VERSION ""

NS_ :

BS_:

BU_: PFAF_HS LVMPC_HS DCDC_HS AMP_HS VICM2_HS FICM_HS ARS_HS MCP_B_HS MCP_A_HS ICCM_OBD_HS SAS_HS ACCM_HS VLBS_HS EBCM_OBD_HS EDI_HS HPCC_HS VITM_OBD_HS PTAM_HS OBCM_HS VICM_HS HCP_HS FDCM_HS APPS_HS ICCM_HS EOCM_F_HS GPCM_HS FSCM_ITBC_HS SCM_HS ITBC_HS VCM_HS HMIM_HS FCP_HS VES_HS Dummy_HS MCP_C_HS RWS_HS ONSTAR_HS EPS_HS TestTool_HS MCP_HS BCP_HS ALC_HS AHL_AFL_HS SADS_HS EPB_HS FSCM_HS AFS_HS FCM_HS TCCM_HS RDCM_HS PTO_HS PCM_HS EBCM_HS ACC_HS BCM_HS TCM_HS ECM_HS

BO_ 452 PPEI_Torque_Request_Status: 8 ECM_HS
 SG_ FSpRgACCSwADdPVal : 50|2@0+ (1,0) [0|3] ""  EBCM_OBD_HS,EBCM_HS
 SG_ FSpRgACCSwADdARC : 6|2@0+ (1,0) [0|3] ""  EBCM_OBD_HS,EBCM_HS
 SG_ FSpRgACCSwADd : 7|1@0+ (1,0) [0|1] ""  EBCM_OBD_HS,EBCM_HS,ACC_HS
 SG_ AutBrkAccActPsStRC : 34|2@0+ (1,0) [0|3] ""  EOCM_F_HS,ACC_HS,EBCM_OBD_HS,EBCM_HS
 SG_ AutBrkAccActPsStPVal : 48|9@0+ (1,0) [0|511] ""  EOCM_F_HS,ACC_HS,EBCM_OBD_HS,EBCM_HS
 SG_ ABAAPS_AccPos : 47|8@0+ (0.392157,0) [0|100.000035] "%"  EBCM_OBD_HS,EBCM_HS,ACC_HS,EOCM_F_HS
 SG_ ABAAPS_AccPosV : 32|1@0+ (1,0) [0|1] ""  EBCM_OBD_HS,EBCM_HS,ACC_HS,EOCM_F_HS
 SG_ ACCATCS_LmtgStat : 12|2@0+ (1,0) [0|3] ""  EOCM_F_HS,ACC_HS
 SG_ ACCATCS_RqStat : 15|3@0+ (1,0) [0|7] ""  EOCM_F_HS,ACC_HS
 SG_ RdLdNomAxlTrq : 10|19@0+ (0.125,-22534) [-22534|43001.875] "Nm"  EOCM_F_HS,ACC_HS
 SG_ AccPdlOvrrdAtvProtVal : 1|2@0+ (1,0) [0|3] ""  EOCM_F_HS,EBCM_OBD_HS,EBCM_HS,ACC_HS,PTO_HS
 SG_ AccPdlOvrrdAtvARC : 3|2@0+ (1,0) [0|3] ""  EOCM_F_HS,EBCM_OBD_HS,EBCM_HS,ACC_HS,PTO_HS
 SG_ AccPdlOvrrdAtv : 4|1@0+ (1,0) [0|1] ""  BCM_HS,EOCM_F_HS,EBCM_OBD_HS,EBCM_HS,ACC_HS,PTO_HS
 SG_ CPSATCS_ReqStatus : 37|3@0+ (1,0) [0|7] ""  ACC_HS,EOCM_F_HS
 SG_ CPSATCS_LmtngStatus : 39|2@0+ (1,0) [0|3] ""  ACC_HS,EOCM_F_HS
 SG_ RVBATCS_ReqStat : 53|3@0+ (1,0) [0|7] ""  EOCM_F_HS
 SG_ RVBATCS_LmtngStat : 55|2@0+ (1,0) [0|3] ""  EOCM_F_HS

BO_ 1905 DTC_Triggered_771: 7 FDCM_HS
 SG_ DTCI_DTCFaultType_771 : 55|8@0+ (1,0) [0|255] ""  HMIM_HS,FCP_HS,ONSTAR_HS
 SG_ DTCI_CodeSupported_771 : 40|1@0+ (1,0) [0|1] ""  HMIM_HS,FCP_HS,ONSTAR_HS
 SG_ DTCI_CurrentStatus_771 : 41|1@0+ (1,0) [0|1] ""  HMIM_HS,FCP_HS,ONSTAR_HS
 SG_ DTCI_TstNPsdCdClrdSt_771 : 42|1@0+ (1,0) [0|1] ""  HMIM_HS,FCP_HS,ONSTAR_HS
 SG_ DTCI_TstFldCdClrdStat_771 : 43|1@0+ (1,0) [0|1] ""  HMIM_HS,FCP_HS,ONSTAR_HS
 SG_ DTCI_HistStat_771 : 44|1@0+ (1,0) [0|1] ""  HMIM_HS,FCP_HS,ONSTAR_HS
 SG_ DTCI_TstNPsdPwrUpSt_771 : 45|1@0+ (1,0) [0|1] ""  HMIM_HS,FCP_HS,ONSTAR_HS
 SG_ DTCI_TstFldPwrUpSt_771 : 46|1@0+ (1,0) [0|1] ""  HMIM_HS,FCP_HS,ONSTAR_HS
 SG_ DTCI_WrnIndRqdSt_771 : 47|1@0+ (1,0) [0|1] ""  HMIM_HS,FCP_HS,ONSTAR_HS
 SG_ DTCI_DTCFailType_771 : 39|8@0+ (1,0) [0|255] ""  HMIM_HS,FCP_HS,ONSTAR_HS
 SG_ DTCI_DTCNumber_771 : 23|16@0+ (1,0) [0|65535] ""  HMIM_HS,FCP_HS,ONSTAR_HS
 SG_ DTCI_DTCSource_771 : 15|8@0+ (1,0) [0|255] ""  HMIM_HS,FCP_HS,ONSTAR_HS
 SG_ DTCI_DTCTriggered_771 : 0|1@0+ (1,0) [0|1] ""  HMIM_HS,FCP_HS,ONSTAR_HS
 SG_ DTCIUnused7_771 : 1|1@0+ (1,0) [0|1] ""  HMIM_HS,FCP_HS,ONSTAR_HS
 SG_ DTCIUnused6_771 : 2|1@0+ (1,0) [0|1] ""  HMIM_HS,FCP_HS,ONSTAR_HS
 SG_ DTCIUnused5_771 : 3|1@0+ (1,0) [0|1] ""  HMIM_HS,FCP_HS,ONSTAR_HS
 SG_ DTCIUnused4_771 : 4|1@0+ (1,0) [0|1] ""  HMIM_HS,FCP_HS,ONSTAR_HS
 SG_ DTCIUnused3_771 : 5|1@0+ (1,0) [0|1] ""  HMIM_HS,FCP_HS,ONSTAR_HS
 SG_ DTCIUnused2_771 : 6|1@0+ (1,0) [0|1] ""  HMIM_HS,FCP_HS,ONSTAR_HS
 SG_ DTCIUnused1_771 : 7|1@0+ (1,0) [0|1] ""  HMIM_HS,FCP_HS,ONSTAR_HS

BO_ 1935 DTC_Triggered_78F: 7 Dummy_HS
 SG_ DTCI_DTCSource_78F : 15|8@0+ (1,0) [0|255] ""  HMIM_HS,FCP_HS,ONSTAR_HS
 SG_ DTCI_DTCTriggered_78F : 0|1@0+ (1,0) [0|1] ""  HMIM_HS,FCP_HS,ONSTAR_HS
 SG_ DTCIUnused1_78F : 7|1@0+ (1,0) [0|1] ""  HMIM_HS,FCP_HS,ONSTAR_HS
 SG_ DTCIUnused2_78F : 6|1@0+ (1,0) [0|1] ""  HMIM_HS,FCP_HS,ONSTAR_HS
 SG_ DTCIUnused3_78F : 5|1@0+ (1,0) [0|1] ""  HMIM_HS,FCP_HS,ONSTAR_HS
 SG_ DTCIUnused4_78F : 4|1@0+ (1,0) [0|1] ""  HMIM_HS,FCP_HS,ONSTAR_HS
 SG_ DTCIUnused5_78F : 3|1@0+ (1,0) [0|1] ""  HMIM_HS,FCP_HS,ONSTAR_HS
 SG_ DTCIUnused6_78F : 2|1@0+ (1,0) [0|1] ""  HMIM_HS,FCP_HS,ONSTAR_HS
 SG_ DTCIUnused7_78F : 1|1@0+ (1,0) [0|1] ""  HMIM_HS,FCP_HS,ONSTAR_HS
 SG_ DTCI_CodeSupported_78F : 40|1@0+ (1,0) [0|1] ""  HMIM_HS,FCP_HS,ONSTAR_HS
 SG_ DTCI_CurrentStatus_78F : 41|1@0+ (1,0) [0|1] ""  HMIM_HS,FCP_HS,ONSTAR_HS
 SG_ DTCI_DTCFaultType_78F : 55|8@0+ (1,0) [0|255] ""  HMIM_HS,FCP_HS,ONSTAR_HS
 SG_ DTCI_TstFldCdClrdStat_78F : 43|1@0+ (1,0) [0|1] ""  HMIM_HS,FCP_HS,ONSTAR_HS
 SG_ DTCI_TstNPsdCdClrdSt_78F : 42|1@0+ (1,0) [0|1] ""  HMIM_HS,FCP_HS,ONSTAR_HS
 SG_ DTCI_HistStat_78F : 44|1@0+ (1,0) [0|1] ""  HMIM_HS,FCP_HS,ONSTAR_HS
 SG_ DTCI_TstNPsdPwrUpSt_78F : 45|1@0+ (1,0) [0|1] ""  HMIM_HS,FCP_HS,ONSTAR_HS
 SG_ DTCI_TstFldPwrUpSt_78F : 46|1@0+ (1,0) [0|1] ""  HMIM_HS,FCP_HS,ONSTAR_HS
 SG_ DTCI_WrnIndRqdSt_78F : 47|1@0+ (1,0) [0|1] ""  HMIM_HS,FCP_HS,ONSTAR_HS
 SG_ DTCI_DTCFailType_78F : 39|8@0+ (1,0) [0|255] ""  HMIM_HS,FCP_HS,ONSTAR_HS
 SG_ DTCI_DTCNumber_78F : 23|16@0+ (1,0) [0|65535] ""  HMIM_HS,FCP_HS,ONSTAR_HS

BO_ 1934 DTC_Triggered_78E: 7 Dummy_HS
 SG_ DTCI_CodeSupported_78E : 40|1@0+ (1,0) [0|1] ""  HMIM_HS,FCP_HS,ONSTAR_HS
 SG_ DTCI_CurrentStatus_78E : 41|1@0+ (1,0) [0|1] ""  HMIM_HS,FCP_HS,ONSTAR_HS
 SG_ DTCI_DTCFailType_78E : 39|8@0+ (1,0) [0|255] ""  HMIM_HS,FCP_HS,ONSTAR_HS
 SG_ DTCI_DTCFaultType_78E : 55|8@0+ (1,0) [0|255] ""  HMIM_HS,FCP_HS,ONSTAR_HS
 SG_ DTCI_DTCNumber_78E : 23|16@0+ (1,0) [0|65535] ""  HMIM_HS,FCP_HS,ONSTAR_HS
 SG_ DTCI_DTCSource_78E : 15|8@0+ (1,0) [0|255] ""  HMIM_HS,FCP_HS,ONSTAR_HS
 SG_ DTCI_DTCTriggered_78E : 0|1@0+ (1,0) [0|1] ""  HMIM_HS,FCP_HS,ONSTAR_HS
 SG_ DTCI_HistStat_78E : 44|1@0+ (1,0) [0|1] ""  HMIM_HS,FCP_HS,ONSTAR_HS
 SG_ DTCI_TstFldCdClrdStat_78E : 43|1@0+ (1,0) [0|1] ""  HMIM_HS,FCP_HS,ONSTAR_HS
 SG_ DTCI_TstFldPwrUpSt_78E : 46|1@0+ (1,0) [0|1] ""  HMIM_HS,FCP_HS,ONSTAR_HS
 SG_ DTCI_TstNPsdCdClrdSt_78E : 42|1@0+ (1,0) [0|1] ""  HMIM_HS,FCP_HS,ONSTAR_HS
 SG_ DTCI_TstNPsdPwrUpSt_78E : 45|1@0+ (1,0) [0|1] ""  HMIM_HS,FCP_HS,ONSTAR_HS
 SG_ DTCIUnused1_78E : 7|1@0+ (1,0) [0|1] ""  HMIM_HS,FCP_HS,ONSTAR_HS
 SG_ DTCIUnused2_78E : 6|1@0+ (1,0) [0|1] ""  HMIM_HS,FCP_HS,ONSTAR_HS
 SG_ DTCIUnused3_78E : 5|1@0+ (1,0) [0|1] ""  HMIM_HS,FCP_HS,ONSTAR_HS
 SG_ DTCIUnused4_78E : 4|1@0+ (1,0) [0|1] ""  HMIM_HS,FCP_HS,ONSTAR_HS
 SG_ DTCIUnused5_78E : 3|1@0+ (1,0) [0|1] ""  HMIM_HS,FCP_HS,ONSTAR_HS
 SG_ DTCIUnused6_78E : 2|1@0+ (1,0) [0|1] ""  HMIM_HS,FCP_HS,ONSTAR_HS
 SG_ DTCIUnused7_78E : 1|1@0+ (1,0) [0|1] ""  HMIM_HS,FCP_HS,ONSTAR_HS
 SG_ DTCI_WrnIndRqdSt_78E : 47|1@0+ (1,0) [0|1] ""  HMIM_HS,FCP_HS,ONSTAR_HS

BO_ 1933 DTC_Triggered_78D: 7 Dummy_HS
 SG_ DTCI_CodeSupported_78D : 40|1@0+ (1,0) [0|1] ""  HMIM_HS,FCP_HS,ONSTAR_HS
 SG_ DTCI_CurrentStatus_78D : 41|1@0+ (1,0) [0|1] ""  HMIM_HS,FCP_HS,ONSTAR_HS
 SG_ DTCI_DTCFailType_78D : 39|8@0+ (1,0) [0|255] ""  HMIM_HS,FCP_HS,ONSTAR_HS
 SG_ DTCI_DTCFaultType_78D : 55|8@0+ (1,0) [0|255] ""  HMIM_HS,FCP_HS,ONSTAR_HS
 SG_ DTCI_DTCNumber_78D : 23|16@0+ (1,0) [0|65535] ""  HMIM_HS,FCP_HS,ONSTAR_HS
 SG_ DTCI_DTCSource_78D : 15|8@0+ (1,0) [0|255] ""  HMIM_HS,FCP_HS,ONSTAR_HS
 SG_ DTCI_DTCTriggered_78D : 0|1@0+ (1,0) [0|1] ""  HMIM_HS,FCP_HS,ONSTAR_HS
 SG_ DTCI_HistStat_78D : 44|1@0+ (1,0) [0|1] ""  HMIM_HS,FCP_HS,ONSTAR_HS
 SG_ DTCI_TstFldCdClrdStat_78D : 43|1@0+ (1,0) [0|1] ""  HMIM_HS,FCP_HS,ONSTAR_HS
 SG_ DTCI_TstFldPwrUpSt_78D : 46|1@0+ (1,0) [0|1] ""  HMIM_HS,FCP_HS,ONSTAR_HS
 SG_ DTCI_TstNPsdCdClrdSt_78D : 42|1@0+ (1,0) [0|1] ""  HMIM_HS,FCP_HS,ONSTAR_HS
 SG_ DTCI_TstNPsdPwrUpSt_78D : 45|1@0+ (1,0) [0|1] ""  HMIM_HS,FCP_HS,ONSTAR_HS
 SG_ DTCIUnused1_78D : 7|1@0+ (1,0) [0|1] ""  HMIM_HS,FCP_HS,ONSTAR_HS
 SG_ DTCIUnused2_78D : 6|1@0+ (1,0) [0|1] ""  HMIM_HS,FCP_HS,ONSTAR_HS
 SG_ DTCIUnused3_78D : 5|1@0+ (1,0) [0|1] ""  HMIM_HS,FCP_HS,ONSTAR_HS
 SG_ DTCIUnused4_78D : 4|1@0+ (1,0) [0|1] ""  HMIM_HS,FCP_HS,ONSTAR_HS
 SG_ DTCIUnused5_78D : 3|1@0+ (1,0) [0|1] ""  HMIM_HS,FCP_HS,ONSTAR_HS
 SG_ DTCIUnused6_78D : 2|1@0+ (1,0) [0|1] ""  HMIM_HS,FCP_HS,ONSTAR_HS
 SG_ DTCIUnused7_78D : 1|1@0+ (1,0) [0|1] ""  HMIM_HS,FCP_HS,ONSTAR_HS
 SG_ DTCI_WrnIndRqdSt_78D : 47|1@0+ (1,0) [0|1] ""  HMIM_HS,FCP_HS,ONSTAR_HS

BO_ 1932 DTC_Triggered_78C: 7 Dummy_HS
 SG_ DTCI_CodeSupported_78C : 40|1@0+ (1,0) [0|1] ""  HMIM_HS,FCP_HS,ONSTAR_HS
 SG_ DTCI_CurrentStatus_78C : 41|1@0+ (1,0) [0|1] ""  HMIM_HS,FCP_HS,ONSTAR_HS
 SG_ DTCI_DTCFailType_78C : 39|8@0+ (1,0) [0|255] ""  HMIM_HS,FCP_HS,ONSTAR_HS
 SG_ DTCI_DTCFaultType_78C : 55|8@0+ (1,0) [0|255] ""  HMIM_HS,FCP_HS,ONSTAR_HS
 SG_ DTCI_DTCNumber_78C : 23|16@0+ (1,0) [0|65535] ""  HMIM_HS,FCP_HS,ONSTAR_HS
 SG_ DTCI_DTCSource_78C : 15|8@0+ (1,0) [0|255] ""  HMIM_HS,FCP_HS,ONSTAR_HS
 SG_ DTCI_DTCTriggered_78C : 0|1@0+ (1,0) [0|1] ""  HMIM_HS,FCP_HS,ONSTAR_HS
 SG_ DTCI_HistStat_78C : 44|1@0+ (1,0) [0|1] ""  HMIM_HS,FCP_HS,ONSTAR_HS
 SG_ DTCI_TstFldCdClrdStat_78C : 43|1@0+ (1,0) [0|1] ""  HMIM_HS,FCP_HS,ONSTAR_HS
 SG_ DTCI_TstFldPwrUpSt_78C : 45|1@0+ (1,0) [0|1] ""  HMIM_HS,FCP_HS,ONSTAR_HS
 SG_ DTCI_TstNPsdCdClrdSt_78C : 42|1@0+ (1,0) [0|1] ""  HMIM_HS,FCP_HS,ONSTAR_HS
 SG_ DTCI_TstNPsdPwrUpSt_78C : 46|1@0+ (1,0) [0|1] ""  HMIM_HS,FCP_HS,ONSTAR_HS
 SG_ DTCIUnused1_78C : 7|1@0+ (1,0) [0|1] ""  HMIM_HS,FCP_HS,ONSTAR_HS
 SG_ DTCIUnused2_78C : 6|1@0+ (1,0) [0|1] ""  HMIM_HS,FCP_HS,ONSTAR_HS
 SG_ DTCIUnused3_78C : 5|1@0+ (1,0) [0|1] ""  HMIM_HS,FCP_HS,ONSTAR_HS
 SG_ DTCIUnused4_78C : 4|1@0+ (1,0) [0|1] ""  HMIM_HS,FCP_HS,ONSTAR_HS
 SG_ DTCIUnused5_78C : 3|1@0+ (1,0) [0|1] ""  HMIM_HS,FCP_HS,ONSTAR_HS
 SG_ DTCIUnused6_78C : 2|1@0+ (1,0) [0|1] ""  HMIM_HS,FCP_HS,ONSTAR_HS
 SG_ DTCIUnused7_78C : 1|1@0+ (1,0) [0|1] ""  HMIM_HS,FCP_HS,ONSTAR_HS
 SG_ DTCI_WrnIndRqdSt_78C : 47|1@0+ (1,0) [0|1] ""  HMIM_HS,FCP_HS,ONSTAR_HS

BO_ 1931 DTC_Triggered_78B: 7 Dummy_HS
 SG_ DTCI_CodeSupported_78B : 40|1@0+ (1,0) [0|1] ""  HMIM_HS,FCP_HS,ONSTAR_HS
 SG_ DTCI_CurrentStatus_78B : 41|1@0+ (1,0) [0|1] ""  HMIM_HS,FCP_HS,ONSTAR_HS
 SG_ DTCI_DTCFailType_78B : 39|8@0+ (1,0) [0|255] ""  HMIM_HS,FCP_HS,ONSTAR_HS
 SG_ DTCI_DTCFaultType_78B : 55|8@0+ (1,0) [0|255] ""  HMIM_HS,FCP_HS,ONSTAR_HS
 SG_ DTCI_DTCNumber_78B : 23|16@0+ (1,0) [0|65535] ""  HMIM_HS,FCP_HS,ONSTAR_HS
 SG_ DTCI_DTCSource_78B : 15|8@0+ (1,0) [0|255] ""  HMIM_HS,FCP_HS,ONSTAR_HS
 SG_ DTCI_DTCTriggered_78B : 0|1@0+ (1,0) [0|1] ""  HMIM_HS,FCP_HS,ONSTAR_HS
 SG_ DTCI_HistStat_78B : 44|1@0+ (1,0) [0|1] ""  HMIM_HS,FCP_HS,ONSTAR_HS
 SG_ DTCI_TstFldCdClrdStat_78B : 43|1@0+ (1,0) [0|1] ""  HMIM_HS,FCP_HS,ONSTAR_HS
 SG_ DTCI_TstFldPwrUpSt_78B : 46|1@0+ (1,0) [0|1] ""  HMIM_HS,FCP_HS,ONSTAR_HS
 SG_ DTCI_TstNPsdCdClrdSt_78B : 42|1@0+ (1,0) [0|1] ""  HMIM_HS,FCP_HS,ONSTAR_HS
 SG_ DTCI_TstNPsdPwrUpSt_78B : 45|1@0+ (1,0) [0|1] ""  HMIM_HS,FCP_HS,ONSTAR_HS
 SG_ DTCIUnused1_78B : 7|1@0+ (1,0) [0|1] ""  HMIM_HS,FCP_HS,ONSTAR_HS
 SG_ DTCIUnused2_78B : 6|1@0+ (1,0) [0|1] ""  HMIM_HS,FCP_HS,ONSTAR_HS
 SG_ DTCIUnused3_78B : 5|1@0+ (1,0) [0|1] ""  HMIM_HS,FCP_HS,ONSTAR_HS
 SG_ DTCIUnused4_78B : 4|1@0+ (1,0) [0|1] ""  HMIM_HS,FCP_HS,ONSTAR_HS
 SG_ DTCIUnused5_78B : 3|1@0+ (1,0) [0|1] ""  HMIM_HS,FCP_HS,ONSTAR_HS
 SG_ DTCIUnused6_78B : 2|1@0+ (1,0) [0|1] ""  HMIM_HS,FCP_HS,ONSTAR_HS
 SG_ DTCIUnused7_78B : 1|1@0+ (1,0) [0|1] ""  HMIM_HS,FCP_HS,ONSTAR_HS
 SG_ DTCI_WrnIndRqdSt_78B : 47|1@0+ (1,0) [0|1] ""  HMIM_HS,FCP_HS,ONSTAR_HS

BO_ 1930 DTC_Triggered_78A: 7 EOCM_F_HS
 SG_ DTCI_CodeSupported_78A : 40|1@0+ (1,0) [0|1] ""  HMIM_HS,FCP_HS,ONSTAR_HS
 SG_ DTCI_CurrentStatus_78A : 41|1@0+ (1,0) [0|1] ""  HMIM_HS,FCP_HS,ONSTAR_HS
 SG_ DTCI_DTCFailType_78A : 39|8@0+ (1,0) [0|255] ""  HMIM_HS,FCP_HS,ONSTAR_HS
 SG_ DTCI_DTCFaultType_78A : 55|8@0+ (1,0) [0|255] ""  HMIM_HS,FCP_HS,ONSTAR_HS
 SG_ DTCI_DTCNumber_78A : 23|16@0+ (1,0) [0|65535] ""  HMIM_HS,FCP_HS,ONSTAR_HS
 SG_ DTCI_DTCSource_78A : 15|8@0+ (1,0) [0|255] ""  HMIM_HS,FCP_HS,ONSTAR_HS
 SG_ DTCI_DTCTriggered_78A : 0|1@0+ (1,0) [0|1] ""  HMIM_HS,FCP_HS,ONSTAR_HS
 SG_ DTCI_HistStat_78A : 44|1@0+ (1,0) [0|1] ""  HMIM_HS,FCP_HS,ONSTAR_HS
 SG_ DTCI_TstFldCdClrdStat_78A : 43|1@0+ (1,0) [0|1] ""  HMIM_HS,FCP_HS,ONSTAR_HS
 SG_ DTCI_TstFldPwrUpSt_78A : 46|1@0+ (1,0) [0|1] ""  HMIM_HS,FCP_HS,ONSTAR_HS
 SG_ DTCI_TstNPsdCdClrdSt_78A : 42|1@0+ (1,0) [0|1] ""  HMIM_HS,FCP_HS,ONSTAR_HS
 SG_ DTCI_TstNPsdPwrUpSt_78A : 45|1@0+ (1,0) [0|1] ""  HMIM_HS,FCP_HS,ONSTAR_HS
 SG_ DTCIUnused1_78A : 7|1@0+ (1,0) [0|1] ""  HMIM_HS,FCP_HS,ONSTAR_HS
 SG_ DTCIUnused2_78A : 6|1@0+ (1,0) [0|1] ""  HMIM_HS,FCP_HS,ONSTAR_HS
 SG_ DTCIUnused3_78A : 5|1@0+ (1,0) [0|1] ""  HMIM_HS,FCP_HS,ONSTAR_HS
 SG_ DTCIUnused4_78A : 4|1@0+ (1,0) [0|1] ""  HMIM_HS,FCP_HS,ONSTAR_HS
 SG_ DTCIUnused5_78A : 3|1@0+ (1,0) [0|1] ""  HMIM_HS,FCP_HS,ONSTAR_HS
 SG_ DTCIUnused6_78A : 2|1@0+ (1,0) [0|1] ""  HMIM_HS,FCP_HS,ONSTAR_HS
 SG_ DTCIUnused7_78A : 1|1@0+ (1,0) [0|1] ""  HMIM_HS,FCP_HS,ONSTAR_HS
 SG_ DTCI_WrnIndRqdSt_78A : 47|1@0+ (1,0) [0|1] ""  HMIM_HS,FCP_HS,ONSTAR_HS

BO_ 1929 DTC_Triggered_789: 7 ARS_HS
 SG_ DTCI_CodeSupported_789 : 40|1@0+ (1,0) [0|1] ""  HMIM_HS,FCP_HS,ONSTAR_HS
 SG_ DTCI_CurrentStatus_789 : 41|1@0+ (1,0) [0|1] ""  HMIM_HS,FCP_HS,ONSTAR_HS
 SG_ DTCI_DTCFailType_789 : 39|8@0+ (1,0) [0|255] ""  HMIM_HS,FCP_HS,ONSTAR_HS
 SG_ DTCI_DTCFaultType_789 : 55|8@0+ (1,0) [0|255] ""  HMIM_HS,FCP_HS,ONSTAR_HS
 SG_ DTCI_DTCNumber_789 : 23|16@0+ (1,0) [0|65535] ""  HMIM_HS,FCP_HS,ONSTAR_HS
 SG_ DTCI_DTCSource_789 : 15|8@0+ (1,0) [0|255] ""  HMIM_HS,FCP_HS,ONSTAR_HS
 SG_ DTCI_DTCTriggered_789 : 0|1@0+ (1,0) [0|1] ""  HMIM_HS,FCP_HS,ONSTAR_HS
 SG_ DTCI_HistStat_789 : 44|1@0+ (1,0) [0|1] ""  HMIM_HS,FCP_HS,ONSTAR_HS
 SG_ DTCI_TstFldCdClrdStat_789 : 43|1@0+ (1,0) [0|1] ""  HMIM_HS,FCP_HS,ONSTAR_HS
 SG_ DTCI_TstFldPwrUpSt_789 : 46|1@0+ (1,0) [0|1] ""  HMIM_HS,FCP_HS,ONSTAR_HS
 SG_ DTCI_TstNPsdCdClrdSt_789 : 42|1@0+ (1,0) [0|1] ""  HMIM_HS,FCP_HS,ONSTAR_HS
 SG_ DTCI_TstNPsdPwrUpSt_789 : 45|1@0+ (1,0) [0|1] ""  HMIM_HS,FCP_HS,ONSTAR_HS
 SG_ DTCIUnused1_789 : 7|1@0+ (1,0) [0|1] ""  HMIM_HS,FCP_HS,ONSTAR_HS
 SG_ DTCIUnused2_789 : 6|1@0+ (1,0) [0|1] ""  HMIM_HS,FCP_HS,ONSTAR_HS
 SG_ DTCIUnused3_789 : 5|1@0+ (1,0) [0|1] ""  HMIM_HS,FCP_HS,ONSTAR_HS
 SG_ DTCIUnused4_789 : 4|1@0+ (1,0) [0|1] ""  HMIM_HS,FCP_HS,ONSTAR_HS
 SG_ DTCIUnused5_789 : 3|1@0+ (1,0) [0|1] ""  HMIM_HS,FCP_HS,ONSTAR_HS
 SG_ DTCIUnused6_789 : 2|1@0+ (1,0) [0|1] ""  HMIM_HS,FCP_HS,ONSTAR_HS
 SG_ DTCIUnused7_789 : 1|1@0+ (1,0) [0|1] ""  HMIM_HS,FCP_HS,ONSTAR_HS
 SG_ DTCI_WrnIndRqdSt_789 : 47|1@0+ (1,0) [0|1] ""  HMIM_HS,FCP_HS,ONSTAR_HS

BO_ 1928 DTC_Triggered_788: 7 HMIM_HS
 SG_ DTCI_CodeSupported_788 : 40|1@0+ (1,0) [0|1] ""  HMIM_HS,FCP_HS,ONSTAR_HS
 SG_ DTCI_CurrentStatus_788 : 41|1@0+ (1,0) [0|1] ""  HMIM_HS,FCP_HS,ONSTAR_HS
 SG_ DTCI_DTCFailType_788 : 39|8@0+ (1,0) [0|255] ""  HMIM_HS,FCP_HS,ONSTAR_HS
 SG_ DTCI_DTCFaultType_788 : 55|8@0+ (1,0) [0|255] ""  HMIM_HS,FCP_HS,ONSTAR_HS
 SG_ DTCI_DTCNumber_788 : 23|16@0+ (1,0) [0|65535] ""  HMIM_HS,FCP_HS,ONSTAR_HS
 SG_ DTCI_DTCSource_788 : 15|8@0+ (1,0) [0|255] ""  HMIM_HS,FCP_HS,ONSTAR_HS
 SG_ DTCI_DTCTriggered_788 : 0|1@0+ (1,0) [0|1] ""  HMIM_HS,FCP_HS,ONSTAR_HS
 SG_ DTCI_HistStat_788 : 44|1@0+ (1,0) [0|1] ""  HMIM_HS,FCP_HS,ONSTAR_HS
 SG_ DTCI_TstFldCdClrdStat_788 : 42|1@0+ (1,0) [0|1] ""  HMIM_HS,FCP_HS,ONSTAR_HS
 SG_ DTCI_TstFldPwrUpSt_788 : 46|1@0+ (1,0) [0|1] ""  HMIM_HS,FCP_HS,ONSTAR_HS
 SG_ DTCI_TstNPsdCdClrdSt_788 : 43|1@0+ (1,0) [0|1] ""  HMIM_HS,FCP_HS,ONSTAR_HS
 SG_ DTCI_TstNPsdPwrUpSt_788 : 45|1@0+ (1,0) [0|1] ""  HMIM_HS,FCP_HS,ONSTAR_HS
 SG_ DTCIUnused1_788 : 7|1@0+ (1,0) [0|1] ""  HMIM_HS,FCP_HS,ONSTAR_HS
 SG_ DTCIUnused2_788 : 6|1@0+ (1,0) [0|1] ""  HMIM_HS,FCP_HS,ONSTAR_HS
 SG_ DTCIUnused3_788 : 5|1@0+ (1,0) [0|1] ""  HMIM_HS,FCP_HS,ONSTAR_HS
 SG_ DTCIUnused4_788 : 4|1@0+ (1,0) [0|1] ""  HMIM_HS,FCP_HS,ONSTAR_HS
 SG_ DTCIUnused5_788 : 3|1@0+ (1,0) [0|1] ""  HMIM_HS,FCP_HS,ONSTAR_HS
 SG_ DTCIUnused6_788 : 2|1@0+ (1,0) [0|1] ""  HMIM_HS,FCP_HS,ONSTAR_HS
 SG_ DTCIUnused7_788 : 1|1@0+ (1,0) [0|1] ""  HMIM_HS,FCP_HS,ONSTAR_HS
 SG_ DTCI_WrnIndRqdSt_788 : 47|1@0+ (1,0) [0|1] ""  HMIM_HS,FCP_HS,ONSTAR_HS

BO_ 1927 DTC_Triggered_787: 7 VICM_HS
 SG_ DTCI_CodeSupported_787 : 40|1@0+ (1,0) [0|1] ""  HMIM_HS,FCP_HS,ONSTAR_HS
 SG_ DTCI_CurrentStatus_787 : 41|1@0+ (1,0) [0|1] ""  HMIM_HS,FCP_HS,ONSTAR_HS
 SG_ DTCI_DTCFailType_787 : 39|8@0+ (1,0) [0|255] ""  HMIM_HS,FCP_HS,ONSTAR_HS
 SG_ DTCI_DTCFaultType_787 : 55|8@0+ (1,0) [0|255] ""  HMIM_HS,FCP_HS,ONSTAR_HS
 SG_ DTCI_DTCNumber_787 : 23|16@0+ (1,0) [0|65535] ""  HMIM_HS,FCP_HS,ONSTAR_HS
 SG_ DTCI_DTCSource_787 : 15|8@0+ (1,0) [0|255] ""  HMIM_HS,FCP_HS,ONSTAR_HS
 SG_ DTCI_DTCTriggered_787 : 0|1@0+ (1,0) [0|1] ""  HMIM_HS,FCP_HS,ONSTAR_HS
 SG_ DTCI_HistStat_787 : 44|1@0+ (1,0) [0|1] ""  HMIM_HS,FCP_HS,ONSTAR_HS
 SG_ DTCI_TstFldCdClrdStat_787 : 43|1@0+ (1,0) [0|1] ""  HMIM_HS,FCP_HS,ONSTAR_HS
 SG_ DTCI_TstFldPwrUpSt_787 : 46|1@0+ (1,0) [0|1] ""  HMIM_HS,FCP_HS,ONSTAR_HS
 SG_ DTCI_TstNPsdCdClrdSt_787 : 42|1@0+ (1,0) [0|1] ""  HMIM_HS,FCP_HS,ONSTAR_HS
 SG_ DTCI_TstNPsdPwrUpSt_787 : 45|1@0+ (1,0) [0|1] ""  HMIM_HS,FCP_HS,ONSTAR_HS
 SG_ DTCIUnused1_787 : 7|1@0+ (1,0) [0|1] ""  HMIM_HS,FCP_HS,ONSTAR_HS
 SG_ DTCIUnused2_787 : 6|1@0+ (1,0) [0|1] ""  HMIM_HS,FCP_HS,ONSTAR_HS
 SG_ DTCIUnused3_787 : 5|1@0+ (1,0) [0|1] ""  HMIM_HS,FCP_HS,ONSTAR_HS
 SG_ DTCIUnused4_787 : 4|1@0+ (1,0) [0|1] ""  HMIM_HS,FCP_HS,ONSTAR_HS
 SG_ DTCIUnused5_787 : 3|1@0+ (1,0) [0|1] ""  HMIM_HS,FCP_HS,ONSTAR_HS
 SG_ DTCIUnused6_787 : 2|1@0+ (1,0) [0|1] ""  HMIM_HS,FCP_HS,ONSTAR_HS
 SG_ DTCIUnused7_787 : 1|1@0+ (1,0) [0|1] ""  HMIM_HS,FCP_HS,ONSTAR_HS
 SG_ DTCI_WrnIndRqdSt_787 : 47|1@0+ (1,0) [0|1] ""  HMIM_HS,FCP_HS,ONSTAR_HS

BO_ 1926 DTC_Triggered_786: 7 MCP_B_HS
 SG_ DTCI_CodeSupported_786 : 40|1@0+ (1,0) [0|1] ""  HMIM_HS,FCP_HS,ONSTAR_HS
 SG_ DTCI_CurrentStatus_786 : 41|1@0+ (1,0) [0|1] ""  HMIM_HS,FCP_HS,ONSTAR_HS
 SG_ DTCI_DTCFailType_786 : 39|8@0+ (1,0) [0|255] ""  HMIM_HS,FCP_HS,ONSTAR_HS
 SG_ DTCI_DTCFaultType_786 : 55|8@0+ (1,0) [0|255] ""  HMIM_HS,FCP_HS,ONSTAR_HS
 SG_ DTCI_DTCNumber_786 : 23|16@0+ (1,0) [0|65535] ""  HMIM_HS,FCP_HS,ONSTAR_HS
 SG_ DTCI_DTCSource_786 : 15|8@0+ (1,0) [0|255] ""  HMIM_HS,FCP_HS,ONSTAR_HS
 SG_ DTCI_DTCTriggered_786 : 0|1@0+ (1,0) [0|1] ""  HMIM_HS,FCP_HS,ONSTAR_HS
 SG_ DTCI_HistStat_786 : 44|1@0+ (1,0) [0|1] ""  HMIM_HS,FCP_HS,ONSTAR_HS
 SG_ DTCI_TstFldCdClrdStat_786 : 43|1@0+ (1,0) [0|1] ""  HMIM_HS,FCP_HS,ONSTAR_HS
 SG_ DTCI_TstFldPwrUpSt_786 : 46|1@0+ (1,0) [0|1] ""  HMIM_HS,FCP_HS,ONSTAR_HS
 SG_ DTCI_TstNPsdCdClrdSt_786 : 42|1@0+ (1,0) [0|1] ""  HMIM_HS,FCP_HS,ONSTAR_HS
 SG_ DTCI_TstNPsdPwrUpSt_786 : 45|1@0+ (1,0) [0|1] ""  HMIM_HS,FCP_HS,ONSTAR_HS
 SG_ DTCIUnused1_786 : 7|1@0+ (1,0) [0|1] ""  HMIM_HS,FCP_HS,ONSTAR_HS
 SG_ DTCIUnused2_786 : 6|1@0+ (1,0) [0|1] ""  HMIM_HS,FCP_HS,ONSTAR_HS
 SG_ DTCIUnused3_786 : 5|1@0+ (1,0) [0|1] ""  HMIM_HS,FCP_HS,ONSTAR_HS
 SG_ DTCIUnused4_786 : 4|1@0+ (1,0) [0|1] ""  HMIM_HS,FCP_HS,ONSTAR_HS
 SG_ DTCIUnused5_786 : 3|1@0+ (1,0) [0|1] ""  HMIM_HS,FCP_HS,ONSTAR_HS
 SG_ DTCIUnused6_786 : 2|1@0+ (1,0) [0|1] ""  HMIM_HS,FCP_HS,ONSTAR_HS
 SG_ DTCIUnused7_786 : 1|1@0+ (1,0) [0|1] ""  HMIM_HS,FCP_HS,ONSTAR_HS
 SG_ DTCI_WrnIndRqdSt_786 : 47|1@0+ (1,0) [0|1] ""  HMIM_HS,FCP_HS,ONSTAR_HS

BO_ 1925 DTC_Triggered_785: 7 ICCM_HS
 SG_ DTCI_CodeSupported_785 : 40|1@0+ (1,0) [0|1] ""  HMIM_HS,FCP_HS,ONSTAR_HS
 SG_ DTCI_CurrentStatus_785 : 41|1@0+ (1,0) [0|1] ""  HMIM_HS,FCP_HS,ONSTAR_HS
 SG_ DTCI_DTCFailType_785 : 39|8@0+ (1,0) [0|255] ""  HMIM_HS,FCP_HS,ONSTAR_HS
 SG_ DTCI_DTCFaultType_785 : 55|8@0+ (1,0) [0|255] ""  HMIM_HS,FCP_HS,ONSTAR_HS
 SG_ DTCI_DTCNumber_785 : 23|16@0+ (1,0) [0|65535] ""  HMIM_HS,FCP_HS,ONSTAR_HS
 SG_ DTCI_DTCSource_785 : 15|8@0+ (1,0) [0|255] ""  HMIM_HS,FCP_HS,ONSTAR_HS
 SG_ DTCI_DTCTriggered_785 : 0|1@0+ (1,0) [0|1] ""  HMIM_HS,FCP_HS,ONSTAR_HS
 SG_ DTCI_HistStat_785 : 44|1@0+ (1,0) [0|1] ""  HMIM_HS,FCP_HS,ONSTAR_HS
 SG_ DTCI_TstFldCdClrdStat_785 : 43|1@0+ (1,0) [0|1] ""  HMIM_HS,FCP_HS,ONSTAR_HS
 SG_ DTCI_TstFldPwrUpSt_785 : 46|1@0+ (1,0) [0|1] ""  HMIM_HS,FCP_HS,ONSTAR_HS
 SG_ DTCI_TstNPsdCdClrdSt_785 : 42|1@0+ (1,0) [0|1] ""  HMIM_HS,FCP_HS,ONSTAR_HS
 SG_ DTCI_TstNPsdPwrUpSt_785 : 45|1@0+ (1,0) [0|1] ""  HMIM_HS,FCP_HS,ONSTAR_HS
 SG_ DTCIUnused1_785 : 7|1@0+ (1,0) [0|1] ""  HMIM_HS,FCP_HS,ONSTAR_HS
 SG_ DTCIUnused2_785 : 6|1@0+ (1,0) [0|1] ""  HMIM_HS,FCP_HS,ONSTAR_HS
 SG_ DTCIUnused3_785 : 5|1@0+ (1,0) [0|1] ""  HMIM_HS,FCP_HS,ONSTAR_HS
 SG_ DTCIUnused4_785 : 4|1@0+ (1,0) [0|1] ""  HMIM_HS,FCP_HS,ONSTAR_HS
 SG_ DTCIUnused5_785 : 3|1@0+ (1,0) [0|1] ""  HMIM_HS,FCP_HS,ONSTAR_HS
 SG_ DTCIUnused6_785 : 2|1@0+ (1,0) [0|1] ""  HMIM_HS,FCP_HS,ONSTAR_HS
 SG_ DTCIUnused7_785 : 1|1@0+ (1,0) [0|1] ""  HMIM_HS,FCP_HS,ONSTAR_HS
 SG_ DTCI_WrnIndRqdSt_785 : 47|1@0+ (1,0) [0|1] ""  HMIM_HS,FCP_HS,ONSTAR_HS

BO_ 1924 DTC_Triggered_784: 7 PTAM_HS
 SG_ DTCI_HistStat_784 : 44|1@0+ (1,0) [0|1] ""  HMIM_HS,FCP_HS,ONSTAR_HS
 SG_ DTCI_TstFldCdClrdStat_784 : 43|1@0+ (1,0) [0|1] ""  HMIM_HS,FCP_HS,ONSTAR_HS
 SG_ DTCI_TstFldPwrUpSt_784 : 46|1@0+ (1,0) [0|1] ""  HMIM_HS,FCP_HS,ONSTAR_HS
 SG_ DTCI_TstNPsdCdClrdSt_784 : 42|1@0+ (1,0) [0|1] ""  HMIM_HS,FCP_HS,ONSTAR_HS
 SG_ DTCI_TstNPsdPwrUpSt_784 : 45|1@0+ (1,0) [0|1] ""  HMIM_HS,FCP_HS,ONSTAR_HS
 SG_ DTCIUnused1_784 : 7|1@0+ (1,0) [0|1] ""  HMIM_HS,FCP_HS,ONSTAR_HS
 SG_ DTCIUnused2_784 : 6|1@0+ (1,0) [0|1] ""  HMIM_HS,FCP_HS,ONSTAR_HS
 SG_ DTCIUnused3_784 : 5|1@0+ (1,0) [0|1] ""  HMIM_HS,FCP_HS,ONSTAR_HS
 SG_ DTCIUnused4_784 : 4|1@0+ (1,0) [0|1] ""  HMIM_HS,FCP_HS,ONSTAR_HS
 SG_ DTCIUnused5_784 : 3|1@0+ (1,0) [0|1] ""  HMIM_HS,FCP_HS,ONSTAR_HS
 SG_ DTCIUnused6_784 : 2|1@0+ (1,0) [0|1] ""  HMIM_HS,FCP_HS,ONSTAR_HS
 SG_ DTCIUnused7_784 : 1|1@0+ (1,0) [0|1] ""  HMIM_HS,FCP_HS,ONSTAR_HS
 SG_ DTCI_WrnIndRqdSt_784 : 47|1@0+ (1,0) [0|1] ""  HMIM_HS,FCP_HS,ONSTAR_HS
 SG_ DTCI_CodeSupported_784 : 40|1@0+ (1,0) [0|1] ""  HMIM_HS,FCP_HS,ONSTAR_HS
 SG_ DTCI_CurrentStatus_784 : 41|1@0+ (1,0) [0|1] ""  HMIM_HS,FCP_HS,ONSTAR_HS
 SG_ DTCI_DTCFailType_784 : 39|8@0+ (1,0) [0|255] ""  HMIM_HS,FCP_HS,ONSTAR_HS
 SG_ DTCI_DTCFaultType_784 : 55|8@0+ (1,0) [0|255] ""  HMIM_HS,FCP_HS,ONSTAR_HS
 SG_ DTCI_DTCNumber_784 : 23|16@0+ (1,0) [0|65535] ""  HMIM_HS,FCP_HS,ONSTAR_HS
 SG_ DTCI_DTCSource_784 : 15|8@0+ (1,0) [0|255] ""  HMIM_HS,FCP_HS,ONSTAR_HS
 SG_ DTCI_DTCTriggered_784 : 0|1@0+ (1,0) [0|1] ""  HMIM_HS,FCP_HS,ONSTAR_HS

BO_ 1923 DTC_Triggered_783: 7 ALC_HS
 SG_ DTCI_WrnIndRqdSt_783 : 47|1@0+ (1,0) [0|1] ""  HMIM_HS,FCP_HS,ONSTAR_HS
 SG_ DTCI_TstNPsdPwrUpSt_783 : 45|1@0+ (1,0) [0|1] ""  HMIM_HS,FCP_HS,ONSTAR_HS
 SG_ DTCI_TstNPsdCdClrdSt_783 : 42|1@0+ (1,0) [0|1] ""  HMIM_HS,FCP_HS,ONSTAR_HS
 SG_ DTCI_TstFldPwrUpSt_783 : 46|1@0+ (1,0) [0|1] ""  HMIM_HS,FCP_HS,ONSTAR_HS
 SG_ DTCI_TstFldCdClrdStat_783 : 43|1@0+ (1,0) [0|1] ""  HMIM_HS,FCP_HS,ONSTAR_HS
 SG_ DTCI_HistStat_783 : 44|1@0+ (1,0) [0|1] ""  HMIM_HS,FCP_HS,ONSTAR_HS
 SG_ DTCI_DTCTriggered_783 : 0|1@0+ (1,0) [0|1] ""  HMIM_HS,FCP_HS,ONSTAR_HS
 SG_ DTCI_DTCSource_783 : 15|8@0+ (1,0) [0|255] ""  HMIM_HS,FCP_HS,ONSTAR_HS
 SG_ DTCI_DTCNumber_783 : 23|16@0+ (1,0) [0|65535] ""  HMIM_HS,FCP_HS,ONSTAR_HS
 SG_ DTCI_DTCFaultType_783 : 55|8@0+ (1,0) [0|255] ""  HMIM_HS,FCP_HS,ONSTAR_HS
 SG_ DTCI_DTCFailType_783 : 39|8@0+ (1,0) [0|255] ""  HMIM_HS,FCP_HS,ONSTAR_HS
 SG_ DTCI_CurrentStatus_783 : 41|1@0+ (1,0) [0|1] ""  HMIM_HS,FCP_HS,ONSTAR_HS
 SG_ DTCI_CodeSupported_783 : 40|1@0+ (1,0) [0|1] ""  HMIM_HS,FCP_HS,ONSTAR_HS
 SG_ DTCIUnused7_783 : 1|1@0+ (1,0) [0|1] ""  HMIM_HS,FCP_HS,ONSTAR_HS
 SG_ DTCIUnused6_783 : 2|1@0+ (1,0) [0|1] ""  HMIM_HS,FCP_HS,ONSTAR_HS
 SG_ DTCIUnused5_783 : 3|1@0+ (1,0) [0|1] ""  HMIM_HS,FCP_HS,ONSTAR_HS
 SG_ DTCIUnused4_783 : 4|1@0+ (1,0) [0|1] ""  HMIM_HS,FCP_HS,ONSTAR_HS
 SG_ DTCIUnused3_783 : 5|1@0+ (1,0) [0|1] ""  HMIM_HS,FCP_HS,ONSTAR_HS
 SG_ DTCIUnused2_783 : 6|1@0+ (1,0) [0|1] ""  HMIM_HS,FCP_HS,ONSTAR_HS
 SG_ DTCIUnused1_783 : 7|1@0+ (1,0) [0|1] ""  HMIM_HS,FCP_HS,ONSTAR_HS

BO_ 1363 UUDT_Resp_From_AMP_HS: 8 AMP_HS
 SG_ DgnInf_HS553 : 7|64@0+ (1,0) [0|1.844674407371E+019] ""  FCP_HS,ONSTAR_HS,TestTool_HS

BO_ 607 USDT_Req_to_VLBS_HS: 8 TestTool_HS
 SG_ DgnInf : 7|64@0+ (1,0) [0|1.844674407371E+019] ""  VLBS_HS

BO_ 1630 USDT_Resp_From_VCM_HS: 8 VCM_HS
 SG_ DgnInf : 7|64@0+ (1,0) [0|1.844674407371E+019] ""  FCP_HS,ONSTAR_HS,TestTool_HS

BO_ 1629 USDT_Resp_From_ARS_HS: 8 ARS_HS
 SG_ DgnInf : 7|64@0+ (1,0) [0|1.844674407371E+019] ""  FCP_HS,ONSTAR_HS,TestTool_HS

BO_ 606 USDT_Req_to_VCM_HS: 8 TestTool_HS
 SG_ DgnInf : 7|64@0+ (1,0) [0|1.844674407371E+019] ""  VCM_HS

BO_ 605 USDT_Req_to_ARS_HS: 8 TestTool_HS
 SG_ DgnInf : 7|64@0+ (1,0) [0|1.844674407371E+019] ""  ARS_HS

BO_ 604 USDT_Req_to_ACCM_HS: 8 TestTool_HS
 SG_ DgnInf : 7|64@0+ (1,0) [0|1.844674407371E+019] ""  ACCM_HS

BO_ 603 USDT_Req_to_ACC_HS: 8 TestTool_HS
 SG_ DgnInf : 7|64@0+ (1,0) [0|1.844674407371E+019] ""  ACC_HS

BO_ 602 USDT_Req_to_ICCM_HS: 8 TestTool_HS
 SG_ DgnInf : 7|64@0+ (1,0) [0|1.844674407371E+019] ""  ICCM_HS

BO_ 1631 USDT_Resp_From_VLBS_HS: 8 VLBS_HS
 SG_ DgnInf : 7|64@0+ (1,0) [0|1.844674407371E+019] ""  FCP_HS,ONSTAR_HS,TestTool_HS

BO_ 1375 UUDT_Resp_From_VLBS_HS: 8 VLBS_HS
 SG_ DgnInf_HS55F : 7|64@0+ (1,0) [0|1.844674407371E+019] ""  FCP_HS,ONSTAR_HS,TestTool_HS

BO_ 1374 UUDT_Resp_From_VCM_HS: 8 VCM_HS
 SG_ DgnInf_HS55E : 7|64@0+ (1,0) [0|1.844674407371E+019] ""  FCP_HS,ONSTAR_HS,TestTool_HS

BO_ 1373 UUDT_Resp_From_ARS_HS: 8 ARS_HS
 SG_ DgnInf_HS55D : 7|64@0+ (1,0) [0|1.844674407371E+019] ""  FCP_HS,ONSTAR_HS,TestTool_HS

BO_ 1372 UUDT_Resp_From_ACCM_HS: 8 ACCM_HS
 SG_ DgnInf_HS55C : 7|64@0+ (1,0) [0|1.844674407371E+019] ""  FCP_HS,ONSTAR_HS,TestTool_HS

BO_ 1371 UUDT_Resp_From_ACC_HS: 8 ACC_HS
 SG_ DgnInf_HS55B : 7|64@0+ (1,0) [0|1.844674407371E+019] ""  FCP_HS,ONSTAR_HS,TestTool_HS

BO_ 1370 UUDT_Resp_From_ICCM_HS: 8 ICCM_HS
 SG_ DgnInf_HS55A : 7|64@0+ (1,0) [0|1.844674407371E+019] ""  FCP_HS,ONSTAR_HS,TestTool_HS

BO_ 1368 UUDT_Resp_From_MCP_B_HS: 8 MCP_B_HS
 SG_ DgnInf_HS558 : 7|64@0+ (1,0) [0|1.844674407371E+019] ""  FCP_HS,ONSTAR_HS,TestTool_HS

BO_ 1367 UUDT_Resp_From_MCP_HS: 8 MCP_HS
 SG_ DgnInf_HS557 : 7|64@0+ (1,0) [0|1.844674407371E+019] ""  FCP_HS,ONSTAR_HS,TestTool_HS

BO_ 1366 UUDT_Resp_From_TCCM_HS: 8 TCCM_HS
 SG_ DgnInf_HS556 : 7|64@0+ (1,0) [0|1.844674407371E+019] ""  FCP_HS,ONSTAR_HS,TestTool_HS

BO_ 1362 UUDT_Resp_From_HMIM_HS: 8 HMIM_HS
 SG_ DgnInf_HS552 : 7|64@0+ (1,0) [0|1.844674407371E+019] ""  FCP_HS,ONSTAR_HS,TestTool_HS

BO_ 1628 USDT_Resp_From_ACCM_HS: 8 ACCM_HS
 SG_ DgnInf : 7|64@0+ (1,0) [0|1.844674407371E+019] ""  FCP_HS,ONSTAR_HS,TestTool_HS

BO_ 1627 USDT_Resp_From_ACC_HS: 8 ACC_HS
 SG_ DgnInf : 7|64@0+ (1,0) [0|1.844674407371E+019] ""  FCP_HS,ONSTAR_HS,TestTool_HS

BO_ 1626 USDT_Resp_From_ICCM_HS: 8 ICCM_HS
 SG_ DgnInf : 7|64@0+ (1,0) [0|1.844674407371E+019] ""  FCP_HS,ONSTAR_HS,TestTool_HS

BO_ 1624 USDT_Resp_From_MCP_B_HS: 8 MCP_B_HS
 SG_ DgnInf : 7|64@0+ (1,0) [0|1.844674407371E+019] ""  FCP_HS,ONSTAR_HS,TestTool_HS

BO_ 1623 USDT_Resp_From_MCP_HS: 8 MCP_HS
 SG_ DgnInf : 7|64@0+ (1,0) [0|1.844674407371E+019] ""  FCP_HS,ONSTAR_HS,TestTool_HS

BO_ 1622 USDT_Resp_From_TCCM_HS: 8 TCCM_HS
 SG_ DgnInf : 7|64@0+ (1,0) [0|1.844674407371E+019] ""  FCP_HS,ONSTAR_HS,TestTool_HS

BO_ 1619 USDT_Resp_From_AMP_HS: 8 AMP_HS
 SG_ DgnInf : 7|64@0+ (1,0) [0|1.844674407371E+019] ""  FCP_HS,ONSTAR_HS,TestTool_HS

BO_ 1618 USDT_Resp_From_HMIM_HS: 8 HMIM_HS
 SG_ DgnInf : 7|64@0+ (1,0) [0|1.844674407371E+019] ""  FCP_HS,ONSTAR_HS,TestTool_HS

BO_ 1617 USDT_Resp_From_FDCM_HS: 8 FDCM_HS
 SG_ DgnInf : 7|64@0+ (1,0) [0|1.844674407371E+019] ""  FCP_HS,ONSTAR_HS,TestTool_HS

BO_ 600 USDT_Req_to_MCP_B_HS: 8 TestTool_HS
 SG_ DgnInf : 7|64@0+ (1,0) [0|1.844674407371E+019] ""  MCP_B_HS

BO_ 599 USDT_Req_to_MCP_HS: 8 TestTool_HS
 SG_ DgnInf : 7|64@0+ (1,0) [0|1.844674407371E+019] ""  MCP_A_HS,MCP_HS

BO_ 598 USDT_Req_to_TCCM_HS: 8 TestTool_HS
 SG_ DgnInf : 7|64@0+ (1,0) [0|1.844674407371E+019] ""  TCCM_HS

BO_ 595 USDT_Req_to_AMP_HS: 8 TestTool_HS
 SG_ DgnInf : 7|64@0+ (1,0) [0|1.844674407371E+019] ""  AMP_HS

BO_ 594 USDT_Req_to_HMIM_HS: 8 TestTool_HS
 SG_ DgnInf : 7|64@0+ (1,0) [0|1.844674407371E+019] ""  HMIM_HS

BO_ 593 USDT_Req_to_FDCM_HS: 8 TestTool_HS
 SG_ DgnInf : 7|64@0+ (1,0) [0|1.844674407371E+019] ""  FDCM_HS

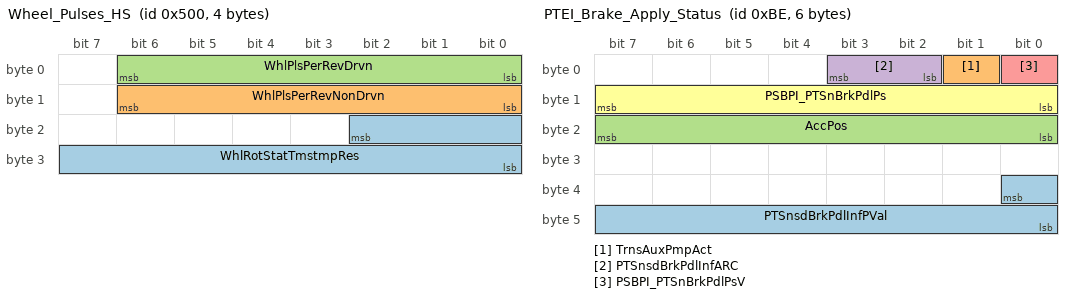
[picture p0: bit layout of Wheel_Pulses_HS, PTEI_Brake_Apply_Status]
BO_ 1280 Wheel_Pulses_HS: 4 EBCM_HS
 SG_ WhlRotStatTmstmpRes : 18|11@0+ (0.002,0) [0|4.094] "uSec"  HMIM_HS,TCCM_HS,BCM_HS,VES_HS,EPS_HS,EOCM_F_HS,FSCM_ITBC_HS
 SG_ WhlPlsPerRevNonDrvn : 14|7@0+ (1,0) [0|127] ""  ICCM_OBD_HS,ICCM_HS,HMIM_HS,TCCM_HS,EOCM_F_HS,FSCM_ITBC_HS,VES_HS,EPS_HS,RDCM_HS,EPB_HS,ACC_HS,BCM_HS,AFS_HS,SADS_HS,FCP_HS,ONSTAR_HS
 SG_ WhlPlsPerRevDrvn : 6|7@0+ (1,0) [0|127] ""  ICCM_OBD_HS,ICCM_HS,HMIM_HS,TCCM_HS,EOCM_F_HS,FSCM_ITBC_HS,VES_HS,EPS_HS,RDCM_HS,FCP_HS,ONSTAR_HS,ACC_HS,BCM_HS,EPB_HS,AFS_HS,SADS_HS

BO_ 190 PTEI_Brake_Apply_Status: 6 ECM_HS
 SG_ PTSnsdBrkPdlInfPVal : 32|9@0+ (1,0) [0|511] ""  ICCM_OBD_HS,ICCM_HS
 SG_ TrnsAuxPmpAct : 1|1@0+ (1,0) [0|1] ""  TCM_HS
 SG_ AccPos : 23|8@0+ (0.392157,0) [0|100.000035] "%"  BCP_HS,FICM_HS,TCM_HS,TCCM_HS
 SG_ PTSnsdBrkPdlInfARC : 3|2@0+ (1,0) [0|3] ""  ICCM_OBD_HS,ICCM_HS
 SG_ PSBPI_PTSnBrkPdlPsV : 0|1@0+ (1,0) [0|1] ""  ICCM_OBD_HS,ICCM_HS,TCM_HS
 SG_ PSBPI_PTSnBrkPdlPs : 15|8@0+ (0.392157,0) [0|100.000035] "%"  ICCM_OBD_HS,ICCM_HS,TCM_HS

BO_ 1361 UUDT_Resp_From_FDCM_HS: 8 FDCM_HS
 SG_ DgnInf_HS551 : 7|64@0+ (1,0) [0|1.844674407371E+019] ""  FCP_HS,ONSTAR_HS,TestTool_HS

BO_ 1345 UUDT_Resp_From_BCM_HS: 8 BCM_HS
 SG_ DgnInf_HS541 : 7|64@0+ (1,0) [0|1.844674407371E+019] ""  FCP_HS,ONSTAR_HS,TestTool_HS

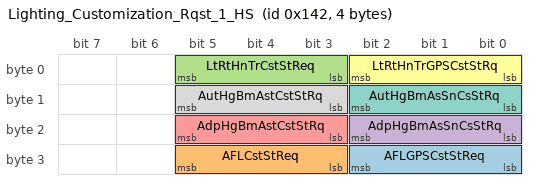
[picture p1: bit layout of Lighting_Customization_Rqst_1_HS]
BO_ 322 Lighting_Customization_Rqst_1_HS: 4 BCM_HS
 SG_ AFLGPSCstStReq : 26|3@0+ (1,0) [0|7] ""  AHL_AFL_HS
 SG_ AFLCstStReq : 29|3@0+ (1,0) [0|7] ""  AHL_AFL_HS
 SG_ LtRtHnTrCstStReq : 5|3@0+ (1,0) [0|7] ""  AHL_AFL_HS
 SG_ AdpHgBmAsSnCsStRq : 18|3@0+ (1,0) [0|7] ""  AHL_AFL_HS
 SG_ AdpHgBmAstCstStRq : 21|3@0+ (1,0) [0|7] ""  AHL_AFL_HS
 SG_ LtRtHnTrGPSCstStRq : 2|3@0+ (1,0) [0|7] ""  AHL_AFL_HS
 SG_ AutHgBmAsSnCsStRq : 10|3@0+ (1,0) [0|7] ""  AHL_AFL_HS
 SG_ AutHgBmAstCstStRq : 13|3@0+ (1,0) [0|7] ""  AHL_AFL_HS

BO_ 1608 USDT_Resp_From_Free_48_HS: 8 Dummy_HS
 SG_ DgnInf : 7|64@0+ (1,0) [0|1.844674407371E+019] ""  FCP_HS,ONSTAR_HS,TestTool_HS

BO_ 534 Damper_Information_HS: 2 SADS_HS
 SG_ DmpSysVehTopSpdLim : 15|8@0+ (2,0) [0|510] "km / h"  BCM_HS
 SG_ SrvSuspSysIO : 0|1@0+ (1,0) [0|1] ""  EDI_HS,FCP_HS,ONSTAR_HS,BCM_HS

BO_ 309 Body_Information_2_HS: 8 BCM_HS
 SG_ StBltTgtCSRq : 23|3@0+ (1,0) [0|7] ""  EBCM_OBD_HS,EBCM_HS
 SG_ ColPrSysCustReq : 15|3@0+ (1,0) [0|7] ""  ACC_HS,EOCM_F_HS
 SG_ SecV : 62|1@0+ (1,0) [0|1] ""  ACC_HS
 SG_ Sec : 61|6@0+ (1,0) [0|63] "s"  ACC_HS
 SG_ CldrYr_154 : 55|8@0+ (1,2000) [2000|2255] "year"  ACC_HS
 SG_ CldrYr : 47|8@0+ (1,2000) [2000|2255] "year"  ACC_HS
 SG_ CldrMth_154 : 39|4@0+ (1,0) [0|15] ""  ACC_HS
 SG_ CldrMth : 35|4@0+ (1,0) [0|15] ""  ACC_HS
 SG_ CldrDay_154 : 30|5@0+ (1,0) [0|31] "days"  ACC_HS
 SG_ CldrDay : 20|5@0+ (1,0) [0|31] "days"  ACC_HS
 SG_ AutoHiBmVDA : 25|1@0+ (1,0) [0|1] ""  AHL_AFL_HS
 SG_ CtLghtDet : 24|1@0+ (1,0) [0|1] ""  AHL_AFL_HS
 SG_ RrClosVDA : 11|1@0+ (1,0) [0|1] ""  ICCM_OBD_HS,ICCM_HS,ALC_HS,SADS_HS
 SG_ TCSysDisSwAtv : 4|1@0+ (1,0) [0|1] ""  EBCM_OBD_HS,EBCM_HS
 SG_ VehMovState : 2|3@0+ (1,0) [0|7] ""  HMIM_HS,EBCM_OBD_HS,EBCM_HS,RDCM_HS,FCM_HS,SADS_HS,AHL_AFL_HS
 SG_ TCSysDisSwAtvV : 3|1@0+ (1,0) [0|1] ""  EBCM_OBD_HS,EBCM_HS
 SG_ HillDesCtrlMdSwActV : 10|1@0+ (1,0) [0|1] ""  EBCM_OBD_HS,EBCM_HS
 SG_ WSWshSwAtv : 5|1@0+ (1,0) [0|1] ""  EOCM_F_HS,FCM_HS,ACC_HS
 SG_ HillDesCtrlMdSwAct : 9|1@0+ (1,0) [0|1] ""  EBCM_OBD_HS,EBCM_HS
 SG_ RrClosAjarSwAct : 12|1@0+ (1,0) [0|1] ""  ICCM_OBD_HS,ICCM_HS,ALC_HS,SADS_HS
 SG_ WSWprAct : 6|1@0+ (1,0) [0|1] ""  FCM_HS,EOCM_F_HS,EBCM_OBD_HS,EBCM_HS,ACC_HS,AHL_AFL_HS

BO_TX_BU_ 452 : PCM_HS,ECM_HS;
BO_TX_BU_ 1925 : ICCM_OBD_HS,ICCM_HS;
BO_TX_BU_ 607 : FCP_HS,ONSTAR_HS,TestTool_HS;
BO_TX_BU_ 606 : FCP_HS,ONSTAR_HS,TestTool_HS;
BO_TX_BU_ 605 : FCP_HS,ONSTAR_HS,TestTool_HS;
BO_TX_BU_ 604 : FCP_HS,ONSTAR_HS,TestTool_HS;
BO_TX_BU_ 603 : FCP_HS,ONSTAR_HS,TestTool_HS;
BO_TX_BU_ 602 : FCP_HS,ONSTAR_HS,TestTool_HS;
BO_TX_BU_ 1367 : MCP_A_HS,MCP_HS;
BO_TX_BU_ 1623 : MCP_A_HS,MCP_HS;
BO_TX_BU_ 600 : FCP_HS,ONSTAR_HS,TestTool_HS;
BO_TX_BU_ 599 : FCP_HS,ONSTAR_HS,TestTool_HS;
BO_TX_BU_ 598 : FCP_HS,ONSTAR_HS,TestTool_HS;
BO_TX_BU_ 595 : FCP_HS,ONSTAR_HS,TestTool_HS;
BO_TX_BU_ 594 : FCP_HS,ONSTAR_HS,TestTool_HS;
BO_TX_BU_ 593 : FCP_HS,ONSTAR_HS,TestTool_HS;
BO_TX_BU_ 1280 : EBCM_OBD_HS,EBCM_HS;
BO_TX_BU_ 190 : PCM_HS,ECM_HS;
CM_ SG_ 1905 DTCI_DTCFaultType_771 "Based on Powertrain definition.  Not expected to be supported by all devices.";
CM_ SG_ 1905 DTCI_DTCFailType_771 "Assigned per GMW3110, Appendix E";
CM_ SG_ 1905 DTCI_DTCSource_771 "This shall be equal to the Diagnostic Address of the transmittting device.";
CM_ SG_ 1935 DTCI_DTCSource_78F "This shall be equal to the Diagnostic Address of the transmittting device.";
CM_ SG_ 1935 DTCI_DTCFaultType_78F "Based on Powertrain definition.  Not expected to be supported by all devices.";
CM_ SG_ 1935 DTCI_DTCFailType_78F "Assigned per GMW3110, Appendix E";
CM_ SG_ 1934 DTCI_DTCFailType_78E "Assigned per GMW3110, Appendix E";
CM_ SG_ 1934 DTCI_DTCFaultType_78E "Based on Powertrain definition.  Not expected to be supported by all devices.";
CM_ SG_ 1934 DTCI_DTCSource_78E "This shall be equal to the Diagnostic Address of the transmittting device.";
CM_ SG_ 1933 DTCI_DTCFailType_78D "Assigned per GMW3110, Appendix E";
CM_ SG_ 1933 DTCI_DTCFaultType_78D "Based on Powertrain definition.  Not expected to be supported by all devices.";
CM_ SG_ 1933 DTCI_DTCSource_78D "This shall be equal to the Diagnostic Address of the transmittting device.";
CM_ SG_ 1932 DTCI_DTCFailType_78C "Assigned per GMW3110, Appendix E";
CM_ SG_ 1932 DTCI_DTCFaultType_78C "Based on Powertrain definition.  Not expected to be supported by all devices.";
CM_ SG_ 1932 DTCI_DTCSource_78C "This shall be equal to the Diagnostic Address of the transmittting device.";
CM_ SG_ 1931 DTCI_DTCFailType_78B "Assigned per GMW3110, Appendix E";
CM_ SG_ 1931 DTCI_DTCFaultType_78B "Based on Powertrain definition.  Not expected to be supported by all devices.";
CM_ SG_ 1931 DTCI_DTCSource_78B "This shall be equal to the Diagnostic Address of the transmittting device.";
CM_ SG_ 1930 DTCI_DTCFailType_78A "Assigned per GMW3110, Appendix E";
CM_ SG_ 1930 DTCI_DTCFaultType_78A "Based on Powertrain definition.  Not expected to be supported by all devices.";
CM_ SG_ 1930 DTCI_DTCSource_78A "This shall be equal to the Diagnostic Address of the transmittting device.";
CM_ SG_ 1929 DTCI_DTCFailType_789 "Assigned per GMW3110, Appendix E";
CM_ SG_ 1929 DTCI_DTCFaultType_789 "Based on Powertrain definition.  Not expected to be supported by all devices.";
CM_ SG_ 1929 DTCI_DTCSource_789 "This shall be equal to the Diagnostic Address of the transmittting device.";
CM_ SG_ 1928 DTCI_DTCFailType_788 "Assigned per GMW3110, Appendix E";
CM_ SG_ 1928 DTCI_DTCFaultType_788 "Based on Powertrain definition.  Not expected to be supported by all devices.";
CM_ SG_ 1928 DTCI_DTCSource_788 "This shall be equal to the Diagnostic Address of the transmittting device.";
CM_ SG_ 1927 DTCI_DTCFailType_787 "Assigned per GMW3110, Appendix E";
CM_ SG_ 1927 DTCI_DTCFaultType_787 "Based on Powertrain definition.  Not expected to be supported by all devices.";
CM_ SG_ 1927 DTCI_DTCSource_787 "This shall be equal to the Diagnostic Address of the transmittting device.";
CM_ SG_ 1926 DTCI_DTCFailType_786 "Assigned per GMW3110, Appendix E";
CM_ SG_ 1926 DTCI_DTCFaultType_786 "Based on Powertrain definition.  Not expected to be supported by all devices.";
CM_ SG_ 1926 DTCI_DTCSource_786 "This shall be equal to the Diagnostic Address of the transmittting device.";
CM_ SG_ 1925 DTCI_DTCFailType_785 "Assigned per GMW3110, Appendix E";
CM_ SG_ 1925 DTCI_DTCFaultType_785 "Based on Powertrain definition.  Not expected to be supported by all devices.";
CM_ SG_ 1925 DTCI_DTCSource_785 "This shall be equal to the Diagnostic Address of the transmittting device.";
CM_ SG_ 1924 DTCI_DTCFailType_784 "Assigned per GMW3110, Appendix E";
CM_ SG_ 1924 DTCI_DTCFaultType_784 "Based on Powertrain definition.  Not expected to be supported by all devices.";
CM_ SG_ 1924 DTCI_DTCSource_784 "This shall be equal to the Diagnostic Address of the transmittting device.";
CM_ SG_ 1923 DTCI_DTCSource_783 "This shall be equal to the Diagnostic Address of the transmittting device.";
CM_ SG_ 1923 DTCI_DTCFaultType_783 "Based on Powertrain definition.  Not expected to be supported by all devices.";
CM_ SG_ 1923 DTCI_DTCFailType_783 "Assigned per GMW3110, Appendix E";
BA_DEF_ SG_  "VNSigSLHS_VNReq" ENUM  "No","Yes";
BA_DEF_ SG_  "VNSigSLHSSharedDiagnostic" ENUM  "No","Yes";
BA_DEF_ SG_  "SignalType" STRING ;
BA_DEF_ SG_  "PacketOrder" INT 0 65535;
BA_DEF_ SG_  "SignalLongName" STRING ;
BA_DEF_ SG_  "GenSigStartValue" INT 0 65535;
BA_DEF_ SG_  "VNSigAllNodes" ENUM  "No","Yes";
BA_DEF_ SG_  "GenSigDeltaValue" INT 0 0;
BA_DEF_ SG_  "GenSigSendType" ENUM  "not used","not used","not used","not used","not used","not used","not used","NoSigSendType","not used","not used","OnAnyChange","OnChangeIfActive","OnDelta";
BA_DEF_ SG_  "GenSigSendOnInit" ENUM  "Not Initialized","Application","Handler";
BA_DEF_ BO_  "AppGenMsgCycleTime" INT 0 0;
BA_DEF_ BO_  "GenMsgILSupport" ENUM  "No","Yes";
BA_DEF_ BO_  "TpApplType" STRING ;
BA_DEF_ BO_  "Prio" INT 0 7;
BA_DEF_ BO_  "MessageSubnet" ENUM  "LS","MS","HS","CE","PE","HV","FO";
BA_DEF_ BO_  "DiagState" ENUM  "No","Yes";
BA_DEF_ BO_  "GenMsgDelayTime" INT 0 100000;
BA_DEF_ BO_  "GenMsgCycleTime" INT 0 100000;
BA_DEF_ BO_  "GenMsgSendType" ENUM  "cyclicX","spontanX","cyclicIfActiveX","spontanWithDelay","cyclicAndSpontanX","cyclicAndSpontanWithDelay","spontanWithRepitition","cyclicIfActiveAndSpontanWD";
BA_DEF_ BO_  "DiagResponse" ENUM  "No","Yes";
BA_DEF_ BO_  "DiagRequest" ENUM  "No","Yes";
BA_DEF_ BO_  "NmMessage" ENUM  "No","Yes";
BA_DEF_REL_ BU_SG_REL_  "GenSigSuprvRespComment" STRING ;
BA_DEF_REL_ BU_SG_REL_  "GenSigVBitResp" ENUM  "No","Yes";
BA_DEF_REL_ BU_SG_REL_  "GenSigVBitRespComment" STRING ;
BA_DEF_REL_ BU_SG_REL_  "GenSigVDAFailComment" STRING ;
BA_DEF_REL_ BU_SG_REL_  "GenSigVDAFailResp" ENUM  "No","Yes";
BA_DEF_REL_ BU_SG_REL_  "GenSigRxStartValue" STRING ;
BA_DEF_REL_ BU_SG_REL_  "GenSigSuprvRespSubValue" INT 0 65535;
BA_DEF_REL_ BU_SG_REL_  "GenSigSuprvResp" ENUM  "None","Notify App","Substitute Default";
BA_DEF_REL_ BU_SG_REL_  "GenSigTimeoutMsg" HEX -2147483648 268435455;
BA_DEF_REL_ BU_SG_REL_  "GenSigTimeoutTime" INT 0 15000;
BA_DEF_DEF_  "VNSigSLHS_VNReq" "No";
BA_DEF_DEF_  "VNSigSLHSSharedDiagnostic" "No";
BA_DEF_DEF_  "SignalType" "";
BA_DEF_DEF_  "PacketOrder" 0;
BA_DEF_DEF_  "SignalLongName" "";
BA_DEF_DEF_  "GenSigStartValue" 0;
BA_DEF_DEF_  "VNSigAllNodes" "No";
BA_DEF_DEF_  "GenSigDeltaValue" 0;
BA_DEF_DEF_  "GenSigSendType" "NoSigSendType";
BA_DEF_DEF_  "GenSigSendOnInit" "Not Initialized";
BA_DEF_DEF_  "AppGenMsgCycleTime" 0;
BA_DEF_DEF_  "GenMsgILSupport" "Yes";
BA_DEF_DEF_  "TpApplType" "";
BA_DEF_DEF_  "Prio" 4;
BA_DEF_DEF_  "MessageSubnet" "FO";
BA_DEF_DEF_  "DiagState" "No";
BA_DEF_DEF_  "GenMsgDelayTime" 0;
BA_DEF_DEF_  "GenMsgCycleTime" 0;
BA_DEF_DEF_  "GenMsgSendType" "spontanX";
BA_DEF_DEF_  "DiagResponse" "No";
BA_DEF_DEF_  "DiagRequest" "No";
BA_DEF_DEF_  "NmMessage" "No";
BA_DEF_DEF_REL_ "GenSigSuprvRespComment" "";
BA_DEF_DEF_REL_ "GenSigVBitResp" "No";
BA_DEF_DEF_REL_ "GenSigVBitRespComment" "";
BA_DEF_DEF_REL_ "GenSigVDAFailComment" "";
BA_DEF_DEF_REL_ "GenSigVDAFailResp" "No";
BA_DEF_DEF_REL_ "GenSigRxStartValue" "";
BA_DEF_DEF_REL_ "GenSigSuprvRespSubValue" 0;
BA_DEF_DEF_REL_ "GenSigSuprvResp" "None";
BA_DEF_DEF_REL_ "GenSigTimeoutMsg" 0;
BA_DEF_DEF_REL_ "GenSigTimeoutTime" 0;
BA_ "Prio" BO_ 452 0;
BA_ "MessageSubnet" BO_ 452 2;
BA_ "GenMsgCycleTime" BO_ 452 25;
BA_ "GenMsgSendType" BO_ 452 0;
BA_ "Prio" BO_ 1905 6;
BA_ "MessageSubnet" BO_ 1905 2;
BA_ "GenMsgCycleTime" BO_ 1905 1000;
BA_ "GenMsgSendType" BO_ 1905 0;
BA_ "Prio" BO_ 1935 0;
BA_ "MessageSubnet" BO_ 1935 2;
BA_ "GenMsgCycleTime" BO_ 1935 1000;
BA_ "GenMsgSendType" BO_ 1935 0;
BA_ "Prio" BO_ 1934 0;
BA_ "MessageSubnet" BO_ 1934 2;
BA_ "GenMsgCycleTime" BO_ 1934 1000;
BA_ "GenMsgSendType" BO_ 1934 0;
BA_ "Prio" BO_ 1933 0;
BA_ "MessageSubnet" BO_ 1933 2;
BA_ "GenMsgCycleTime" BO_ 1933 1000;
BA_ "GenMsgSendType" BO_ 1933 0;
BA_ "Prio" BO_ 1932 0;
BA_ "MessageSubnet" BO_ 1932 2;
BA_ "GenMsgCycleTime" BO_ 1932 1000;
BA_ "GenMsgSendType" BO_ 1932 0;
BA_ "Prio" BO_ 1931 0;
BA_ "MessageSubnet" BO_ 1931 2;
BA_ "GenMsgCycleTime" BO_ 1931 1000;
BA_ "GenMsgSendType" BO_ 1931 0;
BA_ "Prio" BO_ 1930 0;
BA_ "MessageSubnet" BO_ 1930 2;
BA_ "GenMsgCycleTime" BO_ 1930 1000;
BA_ "GenMsgSendType" BO_ 1930 0;
BA_ "Prio" BO_ 1929 0;
BA_ "MessageSubnet" BO_ 1929 2;
BA_ "GenMsgCycleTime" BO_ 1929 1000;
BA_ "GenMsgSendType" BO_ 1929 0;
BA_ "Prio" BO_ 1928 0;
BA_ "MessageSubnet" BO_ 1928 2;
BA_ "GenMsgCycleTime" BO_ 1928 1000;
BA_ "GenMsgSendType" BO_ 1928 0;
BA_ "Prio" BO_ 1927 0;
BA_ "MessageSubnet" BO_ 1927 2;
BA_ "GenMsgCycleTime" BO_ 1927 1000;
BA_ "GenMsgSendType" BO_ 1927 0;
BA_ "Prio" BO_ 1926 0;
BA_ "MessageSubnet" BO_ 1926 2;
BA_ "GenMsgCycleTime" BO_ 1926 1000;
BA_ "GenMsgSendType" BO_ 1926 0;
BA_ "Prio" BO_ 1925 0;
BA_ "MessageSubnet" BO_ 1925 2;
BA_ "GenMsgCycleTime" BO_ 1925 1000;
BA_ "GenMsgSendType" BO_ 1925 0;
BA_ "Prio" BO_ 1924 0;
BA_ "MessageSubnet" BO_ 1924 2;
BA_ "GenMsgCycleTime" BO_ 1924 1000;
BA_ "GenMsgSendType" BO_ 1924 0;
BA_ "Prio" BO_ 1923 0;
BA_ "MessageSubnet" BO_ 1923 2;
BA_ "GenMsgCycleTime" BO_ 1923 1000;
BA_ "GenMsgSendType" BO_ 1923 0;
BA_ "GenMsgILSupport" BO_ 1363 0;
BA_ "TpApplType" BO_ 1363 "DiagUUDTResponse";
BA_ "Prio" BO_ 1363 0;
BA_ "MessageSubnet" BO_ 1363 2;
BA_ "Prio" BO_ 607 0;
BA_ "MessageSubnet" BO_ 607 2;
BA_ "DiagRequest" BO_ 607 1;
BA_ "GenMsgILSupport" BO_ 1630 0;
BA_ "Prio" BO_ 1630 0;
BA_ "MessageSubnet" BO_ 1630 2;
BA_ "DiagResponse" BO_ 1630 1;
BA_ "GenMsgILSupport" BO_ 1629 0;
BA_ "Prio" BO_ 1629 0;
BA_ "MessageSubnet" BO_ 1629 2;
BA_ "DiagResponse" BO_ 1629 1;
BA_ "GenMsgILSupport" BO_ 606 0;
BA_ "Prio" BO_ 606 0;
BA_ "MessageSubnet" BO_ 606 2;
BA_ "DiagRequest" BO_ 606 1;
BA_ "GenMsgILSupport" BO_ 605 0;
BA_ "Prio" BO_ 605 0;
BA_ "MessageSubnet" BO_ 605 2;
BA_ "DiagRequest" BO_ 605 1;
BA_ "Prio" BO_ 604 0;
BA_ "MessageSubnet" BO_ 604 2;
BA_ "DiagRequest" BO_ 604 1;
BA_ "Prio" BO_ 603 0;
BA_ "MessageSubnet" BO_ 603 2;
BA_ "DiagRequest" BO_ 603 1;
BA_ "Prio" BO_ 602 0;
BA_ "MessageSubnet" BO_ 602 2;
BA_ "DiagRequest" BO_ 602 1;
BA_ "Prio" BO_ 1631 0;
BA_ "MessageSubnet" BO_ 1631 2;
BA_ "DiagResponse" BO_ 1631 1;
BA_ "GenMsgILSupport" BO_ 1375 0;
BA_ "TpApplType" BO_ 1375 "DiagUUDTResponse";
BA_ "Prio" BO_ 1375 0;
BA_ "MessageSubnet" BO_ 1375 2;
BA_ "GenMsgILSupport" BO_ 1374 0;
BA_ "TpApplType" BO_ 1374 "DiagUUDTResponse";
BA_ "Prio" BO_ 1374 0;
BA_ "MessageSubnet" BO_ 1374 2;
BA_ "GenMsgILSupport" BO_ 1373 0;
BA_ "TpApplType" BO_ 1373 "DiagUUDTResponse";
BA_ "Prio" BO_ 1373 0;
BA_ "MessageSubnet" BO_ 1373 2;
BA_ "GenMsgILSupport" BO_ 1372 0;
BA_ "TpApplType" BO_ 1372 "DiagUUDTResponse";
BA_ "Prio" BO_ 1372 0;
BA_ "MessageSubnet" BO_ 1372 2;
BA_ "GenMsgILSupport" BO_ 1371 0;
BA_ "TpApplType" BO_ 1371 "DiagUUDTResponse";
BA_ "Prio" BO_ 1371 0;
BA_ "MessageSubnet" BO_ 1371 2;
BA_ "GenMsgILSupport" BO_ 1370 0;
BA_ "TpApplType" BO_ 1370 "DiagUUDTResponse";
BA_ "Prio" BO_ 1370 0;
BA_ "MessageSubnet" BO_ 1370 2;
BA_ "GenMsgILSupport" BO_ 1368 0;
BA_ "TpApplType" BO_ 1368 "DiagUUDTResponse";
BA_ "Prio" BO_ 1368 0;
BA_ "MessageSubnet" BO_ 1368 2;
BA_ "GenMsgILSupport" BO_ 1367 0;
BA_ "TpApplType" BO_ 1367 "DiagUUDTResponse";
BA_ "Prio" BO_ 1367 0;
BA_ "MessageSubnet" BO_ 1367 2;
BA_ "GenMsgILSupport" BO_ 1366 0;
BA_ "TpApplType" BO_ 1366 "DiagUUDTResponse";
BA_ "Prio" BO_ 1366 0;
BA_ "MessageSubnet" BO_ 1366 2;
BA_ "GenMsgILSupport" BO_ 1362 0;
BA_ "TpApplType" BO_ 1362 "DiagUUDTResponse";
BA_ "Prio" BO_ 1362 0;
BA_ "MessageSubnet" BO_ 1362 2;
BA_ "Prio" BO_ 1628 0;
BA_ "MessageSubnet" BO_ 1628 2;
BA_ "DiagResponse" BO_ 1628 1;
BA_ "Prio" BO_ 1627 0;
BA_ "MessageSubnet" BO_ 1627 2;
BA_ "DiagResponse" BO_ 1627 1;
BA_ "Prio" BO_ 1626 0;
BA_ "MessageSubnet" BO_ 1626 2;
BA_ "DiagResponse" BO_ 1626 1;
BA_ "Prio" BO_ 1624 0;
BA_ "MessageSubnet" BO_ 1624 2;
BA_ "DiagResponse" BO_ 1624 1;
BA_ "Prio" BO_ 1623 0;
BA_ "MessageSubnet" BO_ 1623 2;
BA_ "DiagResponse" BO_ 1623 1;
BA_ "Prio" BO_ 1622 0;
BA_ "MessageSubnet" BO_ 1622 2;
BA_ "DiagResponse" BO_ 1622 1;
BA_ "Prio" BO_ 1619 0;
BA_ "MessageSubnet" BO_ 1619 2;
BA_ "DiagResponse" BO_ 1619 1;
BA_ "Prio" BO_ 1618 0;
BA_ "MessageSubnet" BO_ 1618 2;
BA_ "DiagResponse" BO_ 1618 1;
BA_ "Prio" BO_ 1617 0;
BA_ "MessageSubnet" BO_ 1617 2;
BA_ "DiagResponse" BO_ 1617 1;
BA_ "Prio" BO_ 600 0;
BA_ "MessageSubnet" BO_ 600 2;
BA_ "DiagRequest" BO_ 600 1;
BA_ "Prio" BO_ 599 0;
BA_ "MessageSubnet" BO_ 599 2;
BA_ "DiagRequest" BO_ 599 1;
BA_ "Prio" BO_ 598 0;
BA_ "MessageSubnet" BO_ 598 2;
BA_ "DiagRequest" BO_ 598 1;
BA_ "Prio" BO_ 595 0;
BA_ "MessageSubnet" BO_ 595 2;
BA_ "DiagRequest" BO_ 595 1;
BA_ "Prio" BO_ 594 0;
BA_ "MessageSubnet" BO_ 594 2;
BA_ "DiagRequest" BO_ 594 1;
BA_ "Prio" BO_ 593 0;
BA_ "MessageSubnet" BO_ 593 2;
BA_ "DiagRequest" BO_ 593 1;
BA_ "Prio" BO_ 1280 0;
BA_ "MessageSubnet" BO_ 1280 2;
BA_ "GenMsgCycleTime" BO_ 1280 1000;
BA_ "GenMsgSendType" BO_ 1280 0;
BA_ "Prio" BO_ 190 0;
BA_ "MessageSubnet" BO_ 190 2;
BA_ "GenMsgCycleTime" BO_ 190 12;
BA_ "GenMsgSendType" BO_ 190 0;
BA_ "GenMsgILSupport" BO_ 1361 0;
BA_ "TpApplType" BO_ 1361 "DiagUUDTResponse";
BA_ "Prio" BO_ 1361 0;
BA_ "MessageSubnet" BO_ 1361 2;
BA_ "GenMsgILSupport" BO_ 1345 0;
BA_ "TpApplType" BO_ 1345 "DiagUUDTResponse";
BA_ "Prio" BO_ 1345 0;
BA_ "MessageSubnet" BO_ 1345 2;
BA_ "Prio" BO_ 322 0;
BA_ "MessageSubnet" BO_ 322 2;
BA_ "GenMsgCycleTime" BO_ 322 100;
BA_ "GenMsgSendType" BO_ 322 0;
BA_ "Prio" BO_ 1608 0;
BA_ "MessageSubnet" BO_ 1608 2;
BA_ "DiagResponse" BO_ 1608 1;
BA_ "Prio" BO_ 534 0;
BA_ "MessageSubnet" BO_ 534 2;
BA_ "GenMsgCycleTime" BO_ 534 100;
BA_ "GenMsgSendType" BO_ 534 0;
BA_ "Prio" BO_ 309 0;
BA_ "MessageSubnet" BO_ 309 2;
BA_ "GenMsgCycleTime" BO_ 309 100;
BA_ "GenMsgSendType" BO_ 309 0;
BA_ "SignalType" SG_ 452 FSpRgACCSwADdPVal "UNM";
BA_ "SignalLongName" SG_ 452 FSpRgACCSwADdPVal "Full Speed Range ACC Cruise Switch Action Detected Protection Value";
BA_ "VNSigAllNodes" SG_ 452 FSpRgACCSwADdPVal 1;
BA_ "SignalType" SG_ 452 FSpRgACCSwADdARC "UNM";
BA_ "SignalLongName" SG_ 452 FSpRgACCSwADdARC "Full Speed Range ACC Cruise Switch Action Detected Alive Rolling Count";
BA_ "VNSigAllNodes" SG_ 452 FSpRgACCSwADdARC 1;
BA_ "SignalType" SG_ 452 FSpRgACCSwADd "BLN";
BA_ "SignalLongName" SG_ 452 FSpRgACCSwADd "Full Speed Range ACC Cruise Switch Action Detected";
BA_ "VNSigAllNodes" SG_ 452 FSpRgACCSwADd 1;
BA_ "SignalType" SG_ 452 AutBrkAccActPsStRC "UNM";
BA_ "SignalLongName" SG_ 452 AutBrkAccActPsStRC "Autonomous Braking Accelerator Actual Position Status Rolling Count";
BA_ "VNSigAllNodes" SG_ 452 AutBrkAccActPsStRC 1;
BA_ "SignalType" SG_ 452 AutBrkAccActPsStPVal "UNM";
BA_ "SignalLongName" SG_ 452 AutBrkAccActPsStPVal "Autonomous Braking Accelerator Actual Position Status Protection Value";
BA_ "VNSigAllNodes" SG_ 452 AutBrkAccActPsStPVal 1;
BA_ "SignalType" SG_ 452 ABAAPS_AccPos "UNM";
BA_ "PacketOrder" SG_ 452 ABAAPS_AccPos 2;
BA_ "SignalLongName" SG_ 452 ABAAPS_AccPos "Autonomous Braking Accelerator Actual Position Status : Accelerator Position";
BA_ "VNSigAllNodes" SG_ 452 ABAAPS_AccPos 1;
BA_ "SignalType" SG_ 452 ABAAPS_AccPosV "ENM";
BA_ "PacketOrder" SG_ 452 ABAAPS_AccPosV 1;
BA_ "SignalLongName" SG_ 452 ABAAPS_AccPosV "Autonomous Braking Accelerator Actual Position Status : Accelerator Position Validity";
BA_ "VNSigAllNodes" SG_ 452 ABAAPS_AccPosV 1;
BA_ "SignalType" SG_ 452 ACCATCS_LmtgStat "ENM";
BA_ "PacketOrder" SG_ 452 ACCATCS_LmtgStat 2;
BA_ "SignalLongName" SG_ 452 ACCATCS_LmtgStat "Adaptive Cruise Control Axle Torque Command Status : Limiting Status";
BA_ "VNSigAllNodes" SG_ 452 ACCATCS_LmtgStat 1;
BA_ "SignalType" SG_ 452 ACCATCS_RqStat "ENM";
BA_ "PacketOrder" SG_ 452 ACCATCS_RqStat 1;
BA_ "SignalLongName" SG_ 452 ACCATCS_RqStat "Adaptive Cruise Control Axle Torque Command Status : Request Status";
BA_ "VNSigAllNodes" SG_ 452 ACCATCS_RqStat 1;
BA_ "SignalType" SG_ 452 RdLdNomAxlTrq "UNM";
BA_ "SignalLongName" SG_ 452 RdLdNomAxlTrq "Road Load Nominal Axle Torque";
BA_ "VNSigAllNodes" SG_ 452 RdLdNomAxlTrq 1;
BA_ "SignalType" SG_ 452 AccPdlOvrrdAtvProtVal "UNM";
BA_ "SignalLongName" SG_ 452 AccPdlOvrrdAtvProtVal "Accelerator Pedal Override Active Protection Value";
BA_ "VNSigAllNodes" SG_ 452 AccPdlOvrrdAtvProtVal 1;
BA_ "SignalType" SG_ 452 AccPdlOvrrdAtvARC "UNM";
BA_ "SignalLongName" SG_ 452 AccPdlOvrrdAtvARC "Accelerator Pedal Override Active Alive Rolling Count";
BA_ "VNSigAllNodes" SG_ 452 AccPdlOvrrdAtvARC 1;
BA_ "SignalType" SG_ 452 AccPdlOvrrdAtv "BLN";
BA_ "SignalLongName" SG_ 452 AccPdlOvrrdAtv "Accelerator Pedal Override Active";
BA_ "VNSigAllNodes" SG_ 452 AccPdlOvrrdAtv 1;
BA_ "SignalType" SG_ 452 CPSATCS_ReqStatus "ENM";
BA_ "PacketOrder" SG_ 452 CPSATCS_ReqStatus 1;
BA_ "SignalLongName" SG_ 452 CPSATCS_ReqStatus "Collision Preparation System Axle Torque Command Status : Request Status";
BA_ "VNSigAllNodes" SG_ 452 CPSATCS_ReqStatus 1;
BA_ "SignalType" SG_ 452 CPSATCS_LmtngStatus "ENM";
BA_ "PacketOrder" SG_ 452 CPSATCS_LmtngStatus 2;
BA_ "SignalLongName" SG_ 452 CPSATCS_LmtngStatus "Collision Preparation System Axle Torque Command Status : Limiting Status";
BA_ "VNSigAllNodes" SG_ 452 CPSATCS_LmtngStatus 1;
BA_ "SignalType" SG_ 452 RVBATCS_ReqStat "ENM";
BA_ "PacketOrder" SG_ 452 RVBATCS_ReqStat 1;
BA_ "SignalLongName" SG_ 452 RVBATCS_ReqStat "Rear Virtual Bumper Axle Torque Command Status : Request Status";
BA_ "VNSigAllNodes" SG_ 452 RVBATCS_ReqStat 1;
BA_ "SignalType" SG_ 452 RVBATCS_LmtngStat "ENM";
BA_ "PacketOrder" SG_ 452 RVBATCS_LmtngStat 2;
BA_ "SignalLongName" SG_ 452 RVBATCS_LmtngStat "Rear Virtual Bumper Axle Torque Command Status : Limiting Status";
BA_ "VNSigAllNodes" SG_ 452 RVBATCS_LmtngStat 1;
BA_ "SignalType" SG_ 1905 DTCI_DTCFaultType_771 "ENM";
BA_ "PacketOrder" SG_ 1905 DTCI_DTCFaultType_771 20;
BA_ "SignalLongName" SG_ 1905 DTCI_DTCFaultType_771 "Diagnostic Trouble Code Information Extended : Diagnostic Trouble Code Fault Type";
BA_ "VNSigAllNodes" SG_ 1905 DTCI_DTCFaultType_771 1;
BA_ "SignalType" SG_ 1905 DTCI_CodeSupported_771 "BLN";
BA_ "PacketOrder" SG_ 1905 DTCI_CodeSupported_771 19;
BA_ "SignalLongName" SG_ 1905 DTCI_CodeSupported_771 "Diagnostic Trouble Code Information Extended : Code Supported";
BA_ "VNSigAllNodes" SG_ 1905 DTCI_CodeSupported_771 1;
BA_ "SignalType" SG_ 1905 DTCI_CurrentStatus_771 "BLN";
BA_ "PacketOrder" SG_ 1905 DTCI_CurrentStatus_771 18;
BA_ "SignalLongName" SG_ 1905 DTCI_CurrentStatus_771 "Diagnostic Trouble Code Information Extended : Current Status";
BA_ "VNSigAllNodes" SG_ 1905 DTCI_CurrentStatus_771 1;
BA_ "SignalType" SG_ 1905 DTCI_TstNPsdCdClrdSt_771 "BLN";
BA_ "PacketOrder" SG_ 1905 DTCI_TstNPsdCdClrdSt_771 17;
BA_ "SignalLongName" SG_ 1905 DTCI_TstNPsdCdClrdSt_771 "Diagnostic Trouble Code Information Extended : Test Not Passed Since Code Cleared Status";
BA_ "VNSigAllNodes" SG_ 1905 DTCI_TstNPsdCdClrdSt_771 1;
BA_ "SignalType" SG_ 1905 DTCI_TstFldCdClrdStat_771 "BLN";
BA_ "PacketOrder" SG_ 1905 DTCI_TstFldCdClrdStat_771 16;
BA_ "SignalLongName" SG_ 1905 DTCI_TstFldCdClrdStat_771 "Diagnostic Trouble Code Information Extended : Test Failed Since Code Cleared Status";
BA_ "VNSigAllNodes" SG_ 1905 DTCI_TstFldCdClrdStat_771 1;
BA_ "SignalType" SG_ 1905 DTCI_HistStat_771 "BLN";
BA_ "PacketOrder" SG_ 1905 DTCI_HistStat_771 15;
BA_ "SignalLongName" SG_ 1905 DTCI_HistStat_771 "Diagnostic Trouble Code Information Extended : History Status";
BA_ "VNSigAllNodes" SG_ 1905 DTCI_HistStat_771 1;
BA_ "SignalType" SG_ 1905 DTCI_TstNPsdPwrUpSt_771 "BLN";
BA_ "PacketOrder" SG_ 1905 DTCI_TstNPsdPwrUpSt_771 14;
BA_ "SignalLongName" SG_ 1905 DTCI_TstNPsdPwrUpSt_771 "Diagnostic Trouble Code Information Extended : Test Not Passed Since Power Up Status";
BA_ "VNSigAllNodes" SG_ 1905 DTCI_TstNPsdPwrUpSt_771 1;
BA_ "SignalType" SG_ 1905 DTCI_TstFldPwrUpSt_771 "BLN";
BA_ "PacketOrder" SG_ 1905 DTCI_TstFldPwrUpSt_771 13;
BA_ "SignalLongName" SG_ 1905 DTCI_TstFldPwrUpSt_771 "Diagnostic Trouble Code Information Extended : Test Failed Since Power Up Status";
BA_ "VNSigAllNodes" SG_ 1905 DTCI_TstFldPwrUpSt_771 1;
BA_ "SignalType" SG_ 1905 DTCI_WrnIndRqdSt_771 "BLN";
BA_ "PacketOrder" SG_ 1905 DTCI_WrnIndRqdSt_771 12;
BA_ "SignalLongName" SG_ 1905 DTCI_WrnIndRqdSt_771 "Diagnostic Trouble Code Information Extended : Warning Indicator Requested Status";
BA_ "VNSigAllNodes" SG_ 1905 DTCI_WrnIndRqdSt_771 1;
BA_ "SignalType" SG_ 1905 DTCI_DTCFailType_771 "UNM";
BA_ "PacketOrder" SG_ 1905 DTCI_DTCFailType_771 11;
BA_ "SignalLongName" SG_ 1905 DTCI_DTCFailType_771 "Diagnostic Trouble Code Information Extended : Diagnostic Trouble Code Failure Type";
BA_ "VNSigAllNodes" SG_ 1905 DTCI_DTCFailType_771 1;
BA_ "SignalType" SG_ 1905 DTCI_DTCNumber_771 "UNM";
BA_ "PacketOrder" SG_ 1905 DTCI_DTCNumber_771 10;
BA_ "SignalLongName" SG_ 1905 DTCI_DTCNumber_771 "Diagnostic Trouble Code Information Extended : Diagnostic Trouble Code Number";
BA_ "VNSigAllNodes" SG_ 1905 DTCI_DTCNumber_771 1;
BA_ "SignalType" SG_ 1905 DTCI_DTCSource_771 "UNM";
BA_ "PacketOrder" SG_ 1905 DTCI_DTCSource_771 9;
BA_ "SignalLongName" SG_ 1905 DTCI_DTCSource_771 "Diagnostic Trouble Code Information Extended : Diagnostic Trouble Code Source";
BA_ "VNSigAllNodes" SG_ 1905 DTCI_DTCSource_771 1;
BA_ "SignalType" SG_ 1905 DTCI_DTCTriggered_771 "BLN";
BA_ "PacketOrder" SG_ 1905 DTCI_DTCTriggered_771 8;
BA_ "SignalLongName" SG_ 1905 DTCI_DTCTriggered_771 "Diagnostic Trouble Code Information Extended : Diagnostic Trouble Code Triggered";
BA_ "VNSigAllNodes" SG_ 1905 DTCI_DTCTriggered_771 1;
BA_ "SignalType" SG_ 1905 DTCIUnused7_771 "BLN";
BA_ "PacketOrder" SG_ 1905 DTCIUnused7_771 7;
BA_ "SignalLongName" SG_ 1905 DTCIUnused7_771 "Diagnostic Trouble Code Information Extended : Unused 7";
BA_ "VNSigAllNodes" SG_ 1905 DTCIUnused7_771 1;
BA_ "SignalType" SG_ 1905 DTCIUnused6_771 "BLN";
BA_ "PacketOrder" SG_ 1905 DTCIUnused6_771 6;
BA_ "SignalLongName" SG_ 1905 DTCIUnused6_771 "Diagnostic Trouble Code Information Extended : Unused 6";
BA_ "VNSigAllNodes" SG_ 1905 DTCIUnused6_771 1;
BA_ "SignalType" SG_ 1905 DTCIUnused5_771 "BLN";
BA_ "PacketOrder" SG_ 1905 DTCIUnused5_771 5;
BA_ "SignalLongName" SG_ 1905 DTCIUnused5_771 "Diagnostic Trouble Code Information Extended : Unused 5";
BA_ "VNSigAllNodes" SG_ 1905 DTCIUnused5_771 1;
BA_ "SignalType" SG_ 1905 DTCIUnused4_771 "BLN";
BA_ "PacketOrder" SG_ 1905 DTCIUnused4_771 4;
BA_ "SignalLongName" SG_ 1905 DTCIUnused4_771 "Diagnostic Trouble Code Information Extended : Unused 4";
BA_ "VNSigAllNodes" SG_ 1905 DTCIUnused4_771 1;
BA_ "SignalType" SG_ 1905 DTCIUnused3_771 "BLN";
BA_ "PacketOrder" SG_ 1905 DTCIUnused3_771 3;
BA_ "SignalLongName" SG_ 1905 DTCIUnused3_771 "Diagnostic Trouble Code Information Extended : Unused 3";
BA_ "VNSigAllNodes" SG_ 1905 DTCIUnused3_771 1;
BA_ "SignalType" SG_ 1905 DTCIUnused2_771 "BLN";
BA_ "PacketOrder" SG_ 1905 DTCIUnused2_771 2;
BA_ "SignalLongName" SG_ 1905 DTCIUnused2_771 "Diagnostic Trouble Code Information Extended : Unused 2";
BA_ "VNSigAllNodes" SG_ 1905 DTCIUnused2_771 1;
BA_ "SignalType" SG_ 1905 DTCIUnused1_771 "BLN";
BA_ "PacketOrder" SG_ 1905 DTCIUnused1_771 1;
BA_ "SignalLongName" SG_ 1905 DTCIUnused1_771 "Diagnostic Trouble Code Information Extended : Unused 1";
BA_ "VNSigAllNodes" SG_ 1905 DTCIUnused1_771 1;
BA_ "SignalType" SG_ 1935 DTCI_DTCSource_78F "UNM";
BA_ "PacketOrder" SG_ 1935 DTCI_DTCSource_78F 9;
BA_ "SignalLongName" SG_ 1935 DTCI_DTCSource_78F "Diagnostic Trouble Code Information Extended 78F : Diagnostic Trouble Code Source";
BA_ "VNSigAllNodes" SG_ 1935 DTCI_DTCSource_78F 1;
BA_ "SignalType" SG_ 1935 DTCI_DTCTriggered_78F "BLN";
BA_ "PacketOrder" SG_ 1935 DTCI_DTCTriggered_78F 8;
BA_ "SignalLongName" SG_ 1935 DTCI_DTCTriggered_78F "Diagnostic Trouble Code Information Extended 78F : Diagnostic Trouble Code Triggered";
BA_ "VNSigAllNodes" SG_ 1935 DTCI_DTCTriggered_78F 1;
BA_ "SignalType" SG_ 1935 DTCIUnused1_78F "BLN";
BA_ "PacketOrder" SG_ 1935 DTCIUnused1_78F 1;
BA_ "SignalLongName" SG_ 1935 DTCIUnused1_78F "Diagnostic Trouble Code Information Extended 78F : Unused 1";
BA_ "VNSigAllNodes" SG_ 1935 DTCIUnused1_78F 1;
BA_ "SignalType" SG_ 1935 DTCIUnused2_78F "BLN";
BA_ "PacketOrder" SG_ 1935 DTCIUnused2_78F 2;
BA_ "SignalLongName" SG_ 1935 DTCIUnused2_78F "Diagnostic Trouble Code Information Extended 78F : Unused 2";
BA_ "VNSigAllNodes" SG_ 1935 DTCIUnused2_78F 1;
BA_ "SignalType" SG_ 1935 DTCIUnused3_78F "BLN";
BA_ "PacketOrder" SG_ 1935 DTCIUnused3_78F 3;
BA_ "SignalLongName" SG_ 1935 DTCIUnused3_78F "Diagnostic Trouble Code Information Extended 78F : Unused 3";
BA_ "VNSigAllNodes" SG_ 1935 DTCIUnused3_78F 1;
BA_ "SignalType" SG_ 1935 DTCIUnused4_78F "BLN";
BA_ "PacketOrder" SG_ 1935 DTCIUnused4_78F 4;
BA_ "SignalLongName" SG_ 1935 DTCIUnused4_78F "Diagnostic Trouble Code Information Extended 78F : Unused 4";
BA_ "VNSigAllNodes" SG_ 1935 DTCIUnused4_78F 1;
BA_ "SignalType" SG_ 1935 DTCIUnused5_78F "BLN";
BA_ "PacketOrder" SG_ 1935 DTCIUnused5_78F 5;
BA_ "SignalLongName" SG_ 1935 DTCIUnused5_78F "Diagnostic Trouble Code Information Extended 78F : Unused 5";
BA_ "VNSigAllNodes" SG_ 1935 DTCIUnused5_78F 1;
BA_ "SignalType" SG_ 1935 DTCIUnused6_78F "BLN";
BA_ "PacketOrder" SG_ 1935 DTCIUnused6_78F 6;
BA_ "SignalLongName" SG_ 1935 DTCIUnused6_78F "Diagnostic Trouble Code Information Extended 78F : Unused 6";
BA_ "VNSigAllNodes" SG_ 1935 DTCIUnused6_78F 1;
BA_ "SignalType" SG_ 1935 DTCIUnused7_78F "BLN";
BA_ "PacketOrder" SG_ 1935 DTCIUnused7_78F 7;
BA_ "SignalLongName" SG_ 1935 DTCIUnused7_78F "Diagnostic Trouble Code Information Extended 78F : Unused 7";
BA_ "VNSigAllNodes" SG_ 1935 DTCIUnused7_78F 1;
BA_ "SignalType" SG_ 1935 DTCI_CodeSupported_78F "BLN";
BA_ "PacketOrder" SG_ 1935 DTCI_CodeSupported_78F 19;
BA_ "SignalLongName" SG_ 1935 DTCI_CodeSupported_78F "Diagnostic Trouble Code Information Extended 78F : Code Supported";
BA_ "VNSigAllNodes" SG_ 1935 DTCI_CodeSupported_78F 1;
BA_ "SignalType" SG_ 1935 DTCI_CurrentStatus_78F "BLN";
BA_ "PacketOrder" SG_ 1935 DTCI_CurrentStatus_78F 18;
BA_ "SignalLongName" SG_ 1935 DTCI_CurrentStatus_78F "Diagnostic Trouble Code Information Extended 78F : Current Status";
BA_ "VNSigAllNodes" SG_ 1935 DTCI_CurrentStatus_78F 1;
BA_ "SignalType" SG_ 1935 DTCI_DTCFaultType_78F "ENM";
BA_ "PacketOrder" SG_ 1935 DTCI_DTCFaultType_78F 20;
BA_ "SignalLongName" SG_ 1935 DTCI_DTCFaultType_78F "Diagnostic Trouble Code Information Extended 78F : Diagnostic Trouble Code Fault Type";
BA_ "VNSigAllNodes" SG_ 1935 DTCI_DTCFaultType_78F 1;
BA_ "SignalType" SG_ 1935 DTCI_TstFldCdClrdStat_78F "BLN";
BA_ "PacketOrder" SG_ 1935 DTCI_TstFldCdClrdStat_78F 16;
BA_ "SignalLongName" SG_ 1935 DTCI_TstFldCdClrdStat_78F "Diagnostic Trouble Code Information Extended 78F : Test Failed Since Code Cleared Status";
BA_ "VNSigAllNodes" SG_ 1935 DTCI_TstFldCdClrdStat_78F 1;
BA_ "SignalType" SG_ 1935 DTCI_TstNPsdCdClrdSt_78F "BLN";
BA_ "PacketOrder" SG_ 1935 DTCI_TstNPsdCdClrdSt_78F 17;
BA_ "SignalLongName" SG_ 1935 DTCI_TstNPsdCdClrdSt_78F "Diagnostic Trouble Code Information Extended 78F : Test Not Passed Since Code Cleared Status";
BA_ "VNSigAllNodes" SG_ 1935 DTCI_TstNPsdCdClrdSt_78F 1;
BA_ "SignalType" SG_ 1935 DTCI_HistStat_78F "BLN";
BA_ "PacketOrder" SG_ 1935 DTCI_HistStat_78F 15;
BA_ "SignalLongName" SG_ 1935 DTCI_HistStat_78F "Diagnostic Trouble Code Information Extended 78F : History Status";
BA_ "VNSigAllNodes" SG_ 1935 DTCI_HistStat_78F 1;
BA_ "SignalType" SG_ 1935 DTCI_TstNPsdPwrUpSt_78F "BLN";
BA_ "PacketOrder" SG_ 1935 DTCI_TstNPsdPwrUpSt_78F 14;
BA_ "SignalLongName" SG_ 1935 DTCI_TstNPsdPwrUpSt_78F "Diagnostic Trouble Code Information Extended 78F : Test Not Passed Since Power Up Status";
BA_ "VNSigAllNodes" SG_ 1935 DTCI_TstNPsdPwrUpSt_78F 1;
BA_ "SignalType" SG_ 1935 DTCI_TstFldPwrUpSt_78F "BLN";
BA_ "PacketOrder" SG_ 1935 DTCI_TstFldPwrUpSt_78F 13;
BA_ "SignalLongName" SG_ 1935 DTCI_TstFldPwrUpSt_78F "Diagnostic Trouble Code Information Extended 78F : Test Failed Since Power Up Status";
BA_ "VNSigAllNodes" SG_ 1935 DTCI_TstFldPwrUpSt_78F 1;
BA_ "SignalType" SG_ 1935 DTCI_WrnIndRqdSt_78F "BLN";
BA_ "PacketOrder" SG_ 1935 DTCI_WrnIndRqdSt_78F 12;
BA_ "SignalLongName" SG_ 1935 DTCI_WrnIndRqdSt_78F "Diagnostic Trouble Code Information Extended 78F : Warning Indicator Requested Status";
BA_ "VNSigAllNodes" SG_ 1935 DTCI_WrnIndRqdSt_78F 1;
BA_ "SignalType" SG_ 1935 DTCI_DTCFailType_78F "UNM";
BA_ "PacketOrder" SG_ 1935 DTCI_DTCFailType_78F 11;
BA_ "SignalLongName" SG_ 1935 DTCI_DTCFailType_78F "Diagnostic Trouble Code Information Extended 78F : Diagnostic Trouble Code Failure Type";
BA_ "VNSigAllNodes" SG_ 1935 DTCI_DTCFailType_78F 1;
BA_ "SignalType" SG_ 1935 DTCI_DTCNumber_78F "UNM";
BA_ "PacketOrder" SG_ 1935 DTCI_DTCNumber_78F 10;
BA_ "SignalLongName" SG_ 1935 DTCI_DTCNumber_78F "Diagnostic Trouble Code Information Extended 78F : Diagnostic Trouble Code Number";
BA_ "VNSigAllNodes" SG_ 1935 DTCI_DTCNumber_78F 1;
BA_ "SignalType" SG_ 1934 DTCI_CodeSupported_78E "BLN";
BA_ "PacketOrder" SG_ 1934 DTCI_CodeSupported_78E 19;
BA_ "SignalLongName" SG_ 1934 DTCI_CodeSupported_78E "Diagnostic Trouble Code Information Extended 78E : Code Supported";
BA_ "VNSigAllNodes" SG_ 1934 DTCI_CodeSupported_78E 1;
BA_ "SignalType" SG_ 1934 DTCI_CurrentStatus_78E "BLN";
BA_ "PacketOrder" SG_ 1934 DTCI_CurrentStatus_78E 18;
BA_ "SignalLongName" SG_ 1934 DTCI_CurrentStatus_78E "Diagnostic Trouble Code Information Extended 78E : Current Status";
BA_ "VNSigAllNodes" SG_ 1934 DTCI_CurrentStatus_78E 1;
BA_ "SignalType" SG_ 1934 DTCI_DTCFailType_78E "UNM";
BA_ "PacketOrder" SG_ 1934 DTCI_DTCFailType_78E 11;
BA_ "SignalLongName" SG_ 1934 DTCI_DTCFailType_78E "Diagnostic Trouble Code Information Extended 78E : Diagnostic Trouble Code Failure Type";
BA_ "VNSigAllNodes" SG_ 1934 DTCI_DTCFailType_78E 1;
BA_ "SignalType" SG_ 1934 DTCI_DTCFaultType_78E "ENM";
BA_ "PacketOrder" SG_ 1934 DTCI_DTCFaultType_78E 20;
BA_ "SignalLongName" SG_ 1934 DTCI_DTCFaultType_78E "Diagnostic Trouble Code Information Extended 78E : Diagnostic Trouble Code Fault Type";
BA_ "VNSigAllNodes" SG_ 1934 DTCI_DTCFaultType_78E 1;
BA_ "SignalType" SG_ 1934 DTCI_DTCNumber_78E "UNM";
BA_ "PacketOrder" SG_ 1934 DTCI_DTCNumber_78E 10;
BA_ "SignalLongName" SG_ 1934 DTCI_DTCNumber_78E "Diagnostic Trouble Code Information Extended 78E : Diagnostic Trouble Code Number";
BA_ "VNSigAllNodes" SG_ 1934 DTCI_DTCNumber_78E 1;
BA_ "SignalType" SG_ 1934 DTCI_DTCSource_78E "UNM";
BA_ "PacketOrder" SG_ 1934 DTCI_DTCSource_78E 9;
BA_ "SignalLongName" SG_ 1934 DTCI_DTCSource_78E "Diagnostic Trouble Code Information Extended 78E : Diagnostic Trouble Code Source";
BA_ "VNSigAllNodes" SG_ 1934 DTCI_DTCSource_78E 1;
BA_ "SignalType" SG_ 1934 DTCI_DTCTriggered_78E "BLN";
BA_ "PacketOrder" SG_ 1934 DTCI_DTCTriggered_78E 8;
BA_ "SignalLongName" SG_ 1934 DTCI_DTCTriggered_78E "Diagnostic Trouble Code Information Extended 78E : Diagnostic Trouble Code Triggered";
BA_ "VNSigAllNodes" SG_ 1934 DTCI_DTCTriggered_78E 1;
BA_ "SignalType" SG_ 1934 DTCI_HistStat_78E "BLN";
BA_ "PacketOrder" SG_ 1934 DTCI_HistStat_78E 15;
BA_ "SignalLongName" SG_ 1934 DTCI_HistStat_78E "Diagnostic Trouble Code Information Extended 78E : History Status";
BA_ "VNSigAllNodes" SG_ 1934 DTCI_HistStat_78E 1;
BA_ "SignalType" SG_ 1934 DTCI_TstFldCdClrdStat_78E "BLN";
BA_ "PacketOrder" SG_ 1934 DTCI_TstFldCdClrdStat_78E 16;
BA_ "SignalLongName" SG_ 1934 DTCI_TstFldCdClrdStat_78E "Diagnostic Trouble Code Information Extended 78E : Test Failed Since Code Cleared Status";
BA_ "VNSigAllNodes" SG_ 1934 DTCI_TstFldCdClrdStat_78E 1;
BA_ "SignalType" SG_ 1934 DTCI_TstFldPwrUpSt_78E "BLN";
BA_ "PacketOrder" SG_ 1934 DTCI_TstFldPwrUpSt_78E 13;
BA_ "SignalLongName" SG_ 1934 DTCI_TstFldPwrUpSt_78E "Diagnostic Trouble Code Information Extended 78E : Test Failed Since Power Up Status";
BA_ "VNSigAllNodes" SG_ 1934 DTCI_TstFldPwrUpSt_78E 1;
BA_ "SignalType" SG_ 1934 DTCI_TstNPsdCdClrdSt_78E "BLN";
BA_ "PacketOrder" SG_ 1934 DTCI_TstNPsdCdClrdSt_78E 17;
BA_ "SignalLongName" SG_ 1934 DTCI_TstNPsdCdClrdSt_78E "Diagnostic Trouble Code Information Extended 78E : Test Not Passed Since Code Cleared Status";
BA_ "VNSigAllNodes" SG_ 1934 DTCI_TstNPsdCdClrdSt_78E 1;
BA_ "SignalType" SG_ 1934 DTCI_TstNPsdPwrUpSt_78E "BLN";
BA_ "PacketOrder" SG_ 1934 DTCI_TstNPsdPwrUpSt_78E 14;
BA_ "SignalLongName" SG_ 1934 DTCI_TstNPsdPwrUpSt_78E "Diagnostic Trouble Code Information Extended 78E : Test Not Passed Since Power Up Status";
BA_ "VNSigAllNodes" SG_ 1934 DTCI_TstNPsdPwrUpSt_78E 1;
BA_ "SignalType" SG_ 1934 DTCIUnused1_78E "BLN";
BA_ "PacketOrder" SG_ 1934 DTCIUnused1_78E 1;
BA_ "SignalLongName" SG_ 1934 DTCIUnused1_78E "Diagnostic Trouble Code Information Extended 78E : Unused 1";
BA_ "VNSigAllNodes" SG_ 1934 DTCIUnused1_78E 1;
BA_ "SignalType" SG_ 1934 DTCIUnused2_78E "BLN";
BA_ "PacketOrder" SG_ 1934 DTCIUnused2_78E 2;
BA_ "SignalLongName" SG_ 1934 DTCIUnused2_78E "Diagnostic Trouble Code Information Extended 78E : Unused 2";
BA_ "VNSigAllNodes" SG_ 1934 DTCIUnused2_78E 1;
BA_ "SignalType" SG_ 1934 DTCIUnused3_78E "BLN";
BA_ "PacketOrder" SG_ 1934 DTCIUnused3_78E 3;
BA_ "SignalLongName" SG_ 1934 DTCIUnused3_78E "Diagnostic Trouble Code Information Extended 78E : Unused 3";
BA_ "VNSigAllNodes" SG_ 1934 DTCIUnused3_78E 1;
BA_ "SignalType" SG_ 1934 DTCIUnused4_78E "BLN";
BA_ "PacketOrder" SG_ 1934 DTCIUnused4_78E 4;
BA_ "SignalLongName" SG_ 1934 DTCIUnused4_78E "Diagnostic Trouble Code Information Extended 78E : Unused 4";
BA_ "VNSigAllNodes" SG_ 1934 DTCIUnused4_78E 1;
BA_ "SignalType" SG_ 1934 DTCIUnused5_78E "BLN";
BA_ "PacketOrder" SG_ 1934 DTCIUnused5_78E 5;
BA_ "SignalLongName" SG_ 1934 DTCIUnused5_78E "Diagnostic Trouble Code Information Extended 78E : Unused 5";
BA_ "VNSigAllNodes" SG_ 1934 DTCIUnused5_78E 1;
BA_ "SignalType" SG_ 1934 DTCIUnused6_78E "BLN";
BA_ "PacketOrder" SG_ 1934 DTCIUnused6_78E 6;
BA_ "SignalLongName" SG_ 1934 DTCIUnused6_78E "Diagnostic Trouble Code Information Extended 78E : Unused 6";
BA_ "VNSigAllNodes" SG_ 1934 DTCIUnused6_78E 1;
BA_ "SignalType" SG_ 1934 DTCIUnused7_78E "BLN";
BA_ "PacketOrder" SG_ 1934 DTCIUnused7_78E 7;
BA_ "SignalLongName" SG_ 1934 DTCIUnused7_78E "Diagnostic Trouble Code Information Extended 78E : Unused 7";
BA_ "VNSigAllNodes" SG_ 1934 DTCIUnused7_78E 1;
BA_ "SignalType" SG_ 1934 DTCI_WrnIndRqdSt_78E "BLN";
BA_ "PacketOrder" SG_ 1934 DTCI_WrnIndRqdSt_78E 12;
BA_ "SignalLongName" SG_ 1934 DTCI_WrnIndRqdSt_78E "Diagnostic Trouble Code Information Extended 78E : Warning Indicator Requested Status";
BA_ "VNSigAllNodes" SG_ 1934 DTCI_WrnIndRqdSt_78E 1;
BA_ "SignalType" SG_ 1933 DTCI_CodeSupported_78D "BLN";
BA_ "PacketOrder" SG_ 1933 DTCI_CodeSupported_78D 19;
BA_ "SignalLongName" SG_ 1933 DTCI_CodeSupported_78D "Diagnostic Trouble Code Information Extended 78D : Code Supported";
BA_ "VNSigAllNodes" SG_ 1933 DTCI_CodeSupported_78D 1;
BA_ "SignalType" SG_ 1933 DTCI_CurrentStatus_78D "BLN";
BA_ "PacketOrder" SG_ 1933 DTCI_CurrentStatus_78D 18;
BA_ "SignalLongName" SG_ 1933 DTCI_CurrentStatus_78D "Diagnostic Trouble Code Information Extended 78D : Current Status";
BA_ "VNSigAllNodes" SG_ 1933 DTCI_CurrentStatus_78D 1;
BA_ "SignalType" SG_ 1933 DTCI_DTCFailType_78D "UNM";
BA_ "PacketOrder" SG_ 1933 DTCI_DTCFailType_78D 11;
BA_ "SignalLongName" SG_ 1933 DTCI_DTCFailType_78D "Diagnostic Trouble Code Information Extended 78D : Diagnostic Trouble Code Failure Type";
BA_ "VNSigAllNodes" SG_ 1933 DTCI_DTCFailType_78D 1;
BA_ "SignalType" SG_ 1933 DTCI_DTCFaultType_78D "ENM";
BA_ "PacketOrder" SG_ 1933 DTCI_DTCFaultType_78D 20;
BA_ "SignalLongName" SG_ 1933 DTCI_DTCFaultType_78D "Diagnostic Trouble Code Information Extended 78D : Diagnostic Trouble Code Fault Type";
BA_ "VNSigAllNodes" SG_ 1933 DTCI_DTCFaultType_78D 1;
BA_ "SignalType" SG_ 1933 DTCI_DTCNumber_78D "UNM";
BA_ "PacketOrder" SG_ 1933 DTCI_DTCNumber_78D 10;
BA_ "SignalLongName" SG_ 1933 DTCI_DTCNumber_78D "Diagnostic Trouble Code Information Extended 78D : Diagnostic Trouble Code Number";
BA_ "VNSigAllNodes" SG_ 1933 DTCI_DTCNumber_78D 1;
BA_ "SignalType" SG_ 1933 DTCI_DTCSource_78D "UNM";
BA_ "PacketOrder" SG_ 1933 DTCI_DTCSource_78D 9;
BA_ "SignalLongName" SG_ 1933 DTCI_DTCSource_78D "Diagnostic Trouble Code Information Extended 78D : Diagnostic Trouble Code Source";
BA_ "VNSigAllNodes" SG_ 1933 DTCI_DTCSource_78D 1;
BA_ "SignalType" SG_ 1933 DTCI_DTCTriggered_78D "BLN";
BA_ "PacketOrder" SG_ 1933 DTCI_DTCTriggered_78D 8;
BA_ "SignalLongName" SG_ 1933 DTCI_DTCTriggered_78D "Diagnostic Trouble Code Information Extended 78D : Diagnostic Trouble Code Triggered";
BA_ "VNSigAllNodes" SG_ 1933 DTCI_DTCTriggered_78D 1;
BA_ "SignalType" SG_ 1933 DTCI_HistStat_78D "BLN";
BA_ "PacketOrder" SG_ 1933 DTCI_HistStat_78D 15;
BA_ "SignalLongName" SG_ 1933 DTCI_HistStat_78D "Diagnostic Trouble Code Information Extended 78D : History Status";
BA_ "VNSigAllNodes" SG_ 1933 DTCI_HistStat_78D 1;
BA_ "SignalType" SG_ 1933 DTCI_TstFldCdClrdStat_78D "BLN";
BA_ "PacketOrder" SG_ 1933 DTCI_TstFldCdClrdStat_78D 16;
BA_ "SignalLongName" SG_ 1933 DTCI_TstFldCdClrdStat_78D "Diagnostic Trouble Code Information Extended 78D : Test Failed Since Code Cleared Status";
BA_ "VNSigAllNodes" SG_ 1933 DTCI_TstFldCdClrdStat_78D 1;
BA_ "SignalType" SG_ 1933 DTCI_TstFldPwrUpSt_78D "BLN";
BA_ "PacketOrder" SG_ 1933 DTCI_TstFldPwrUpSt_78D 13;
BA_ "SignalLongName" SG_ 1933 DTCI_TstFldPwrUpSt_78D "Diagnostic Trouble Code Information Extended 78D : Test Failed Since Power Up Status";
BA_ "VNSigAllNodes" SG_ 1933 DTCI_TstFldPwrUpSt_78D 1;
BA_ "SignalType" SG_ 1933 DTCI_TstNPsdCdClrdSt_78D "BLN";
BA_ "PacketOrder" SG_ 1933 DTCI_TstNPsdCdClrdSt_78D 17;
BA_ "SignalLongName" SG_ 1933 DTCI_TstNPsdCdClrdSt_78D "Diagnostic Trouble Code Information Extended 78D : Test Not Passed Since Code Cleared Status";
BA_ "VNSigAllNodes" SG_ 1933 DTCI_TstNPsdCdClrdSt_78D 1;
BA_ "SignalType" SG_ 1933 DTCI_TstNPsdPwrUpSt_78D "BLN";
BA_ "PacketOrder" SG_ 1933 DTCI_TstNPsdPwrUpSt_78D 14;
BA_ "SignalLongName" SG_ 1933 DTCI_TstNPsdPwrUpSt_78D "Diagnostic Trouble Code Information Extended 78D : Test Not Passed Since Power Up Status";
BA_ "VNSigAllNodes" SG_ 1933 DTCI_TstNPsdPwrUpSt_78D 1;
BA_ "SignalType" SG_ 1933 DTCIUnused1_78D "BLN";
BA_ "PacketOrder" SG_ 1933 DTCIUnused1_78D 1;
BA_ "SignalLongName" SG_ 1933 DTCIUnused1_78D "Diagnostic Trouble Code Information Extended 78D : Unused 1";
BA_ "VNSigAllNodes" SG_ 1933 DTCIUnused1_78D 1;
BA_ "SignalType" SG_ 1933 DTCIUnused2_78D "BLN";
BA_ "PacketOrder" SG_ 1933 DTCIUnused2_78D 2;
BA_ "SignalLongName" SG_ 1933 DTCIUnused2_78D "Diagnostic Trouble Code Information Extended 78D : Unused 2";
BA_ "VNSigAllNodes" SG_ 1933 DTCIUnused2_78D 1;
BA_ "SignalType" SG_ 1933 DTCIUnused3_78D "BLN";
BA_ "PacketOrder" SG_ 1933 DTCIUnused3_78D 3;
BA_ "SignalLongName" SG_ 1933 DTCIUnused3_78D "Diagnostic Trouble Code Information Extended 78D : Unused 3";
BA_ "VNSigAllNodes" SG_ 1933 DTCIUnused3_78D 1;
BA_ "SignalType" SG_ 1933 DTCIUnused4_78D "BLN";
BA_ "PacketOrder" SG_ 1933 DTCIUnused4_78D 4;
BA_ "SignalLongName" SG_ 1933 DTCIUnused4_78D "Diagnostic Trouble Code Information Extended 78D : Unused 4";
BA_ "VNSigAllNodes" SG_ 1933 DTCIUnused4_78D 1;
BA_ "SignalType" SG_ 1933 DTCIUnused5_78D "BLN";
BA_ "PacketOrder" SG_ 1933 DTCIUnused5_78D 5;
BA_ "SignalLongName" SG_ 1933 DTCIUnused5_78D "Diagnostic Trouble Code Information Extended 78D : Unused 5";
BA_ "VNSigAllNodes" SG_ 1933 DTCIUnused5_78D 1;
BA_ "SignalType" SG_ 1933 DTCIUnused6_78D "BLN";
BA_ "PacketOrder" SG_ 1933 DTCIUnused6_78D 6;
BA_ "SignalLongName" SG_ 1933 DTCIUnused6_78D "Diagnostic Trouble Code Information Extended 78D : Unused 6";
BA_ "VNSigAllNodes" SG_ 1933 DTCIUnused6_78D 1;
BA_ "SignalType" SG_ 1933 DTCIUnused7_78D "BLN";
BA_ "PacketOrder" SG_ 1933 DTCIUnused7_78D 7;
BA_ "SignalLongName" SG_ 1933 DTCIUnused7_78D "Diagnostic Trouble Code Information Extended 78D : Unused 7";
BA_ "VNSigAllNodes" SG_ 1933 DTCIUnused7_78D 1;
BA_ "SignalType" SG_ 1933 DTCI_WrnIndRqdSt_78D "BLN";
BA_ "PacketOrder" SG_ 1933 DTCI_WrnIndRqdSt_78D 12;
BA_ "SignalLongName" SG_ 1933 DTCI_WrnIndRqdSt_78D "Diagnostic Trouble Code Information Extended 78D : Warning Indicator Requested Status";
BA_ "VNSigAllNodes" SG_ 1933 DTCI_WrnIndRqdSt_78D 1;
BA_ "SignalType" SG_ 1932 DTCI_CodeSupported_78C "BLN";
BA_ "PacketOrder" SG_ 1932 DTCI_CodeSupported_78C 19;
BA_ "SignalLongName" SG_ 1932 DTCI_CodeSupported_78C "Diagnostic Trouble Code Information Extended 78C : Code Supported";
BA_ "VNSigAllNodes" SG_ 1932 DTCI_CodeSupported_78C 1;
BA_ "SignalType" SG_ 1932 DTCI_CurrentStatus_78C "BLN";
BA_ "PacketOrder" SG_ 1932 DTCI_CurrentStatus_78C 18;
BA_ "SignalLongName" SG_ 1932 DTCI_CurrentStatus_78C "Diagnostic Trouble Code Information Extended 78C : Current Status";
BA_ "VNSigAllNodes" SG_ 1932 DTCI_CurrentStatus_78C 1;
BA_ "SignalType" SG_ 1932 DTCI_DTCFailType_78C "UNM";
BA_ "PacketOrder" SG_ 1932 DTCI_DTCFailType_78C 11;
BA_ "SignalLongName" SG_ 1932 DTCI_DTCFailType_78C "Diagnostic Trouble Code Information Extended 78C : Diagnostic Trouble Code Failure Type";
BA_ "VNSigAllNodes" SG_ 1932 DTCI_DTCFailType_78C 1;
BA_ "SignalType" SG_ 1932 DTCI_DTCFaultType_78C "ENM";
BA_ "PacketOrder" SG_ 1932 DTCI_DTCFaultType_78C 20;
BA_ "SignalLongName" SG_ 1932 DTCI_DTCFaultType_78C "Diagnostic Trouble Code Information Extended 78C : Diagnostic Trouble Code Fault Type";
BA_ "VNSigAllNodes" SG_ 1932 DTCI_DTCFaultType_78C 1;
BA_ "SignalType" SG_ 1932 DTCI_DTCNumber_78C "UNM";
BA_ "PacketOrder" SG_ 1932 DTCI_DTCNumber_78C 10;
BA_ "SignalLongName" SG_ 1932 DTCI_DTCNumber_78C "Diagnostic Trouble Code Information Extended 78C : Diagnostic Trouble Code Number";
BA_ "VNSigAllNodes" SG_ 1932 DTCI_DTCNumber_78C 1;
BA_ "SignalType" SG_ 1932 DTCI_DTCSource_78C "UNM";
BA_ "PacketOrder" SG_ 1932 DTCI_DTCSource_78C 9;
BA_ "SignalLongName" SG_ 1932 DTCI_DTCSource_78C "Diagnostic Trouble Code Information Extended 78C : Diagnostic Trouble Code Source";
BA_ "VNSigAllNodes" SG_ 1932 DTCI_DTCSource_78C 1;
BA_ "SignalType" SG_ 1932 DTCI_DTCTriggered_78C "BLN";
BA_ "PacketOrder" SG_ 1932 DTCI_DTCTriggered_78C 8;
BA_ "SignalLongName" SG_ 1932 DTCI_DTCTriggered_78C "Diagnostic Trouble Code Information Extended 78C : Diagnostic Trouble Code Triggered";
BA_ "VNSigAllNodes" SG_ 1932 DTCI_DTCTriggered_78C 1;
BA_ "SignalType" SG_ 1932 DTCI_HistStat_78C "BLN";
BA_ "PacketOrder" SG_ 1932 DTCI_HistStat_78C 15;
BA_ "SignalLongName" SG_ 1932 DTCI_HistStat_78C "Diagnostic Trouble Code Information Extended 78C : History Status";
BA_ "VNSigAllNodes" SG_ 1932 DTCI_HistStat_78C 1;
BA_ "SignalType" SG_ 1932 DTCI_TstFldCdClrdStat_78C "BLN";
BA_ "PacketOrder" SG_ 1932 DTCI_TstFldCdClrdStat_78C 16;
BA_ "SignalLongName" SG_ 1932 DTCI_TstFldCdClrdStat_78C "Diagnostic Trouble Code Information Extended 78C : Test Failed Since Code Cleared Status";
BA_ "VNSigAllNodes" SG_ 1932 DTCI_TstFldCdClrdStat_78C 1;
BA_ "SignalType" SG_ 1932 DTCI_TstFldPwrUpSt_78C "BLN";
BA_ "PacketOrder" SG_ 1932 DTCI_TstFldPwrUpSt_78C 13;
BA_ "SignalLongName" SG_ 1932 DTCI_TstFldPwrUpSt_78C "Diagnostic Trouble Code Information Extended 78C : Test Failed Since Power Up Status";
BA_ "VNSigAllNodes" SG_ 1932 DTCI_TstFldPwrUpSt_78C 1;
BA_ "SignalType" SG_ 1932 DTCI_TstNPsdCdClrdSt_78C "BLN";
BA_ "PacketOrder" SG_ 1932 DTCI_TstNPsdCdClrdSt_78C 17;
BA_ "SignalLongName" SG_ 1932 DTCI_TstNPsdCdClrdSt_78C "Diagnostic Trouble Code Information Extended 78C : Test Not Passed Since Code Cleared Status";
BA_ "VNSigAllNodes" SG_ 1932 DTCI_TstNPsdCdClrdSt_78C 1;
BA_ "SignalType" SG_ 1932 DTCI_TstNPsdPwrUpSt_78C "BLN";
BA_ "PacketOrder" SG_ 1932 DTCI_TstNPsdPwrUpSt_78C 14;
BA_ "SignalLongName" SG_ 1932 DTCI_TstNPsdPwrUpSt_78C "Diagnostic Trouble Code Information Extended 78C : Test Not Passed Since Power Up Status";
BA_ "VNSigAllNodes" SG_ 1932 DTCI_TstNPsdPwrUpSt_78C 1;
BA_ "SignalType" SG_ 1932 DTCIUnused1_78C "BLN";
BA_ "PacketOrder" SG_ 1932 DTCIUnused1_78C 1;
BA_ "SignalLongName" SG_ 1932 DTCIUnused1_78C "Diagnostic Trouble Code Information Extended 78C : Unused 1";
BA_ "VNSigAllNodes" SG_ 1932 DTCIUnused1_78C 1;
BA_ "SignalType" SG_ 1932 DTCIUnused2_78C "BLN";
BA_ "PacketOrder" SG_ 1932 DTCIUnused2_78C 2;
BA_ "SignalLongName" SG_ 1932 DTCIUnused2_78C "Diagnostic Trouble Code Information Extended 78C : Unused 2";
BA_ "VNSigAllNodes" SG_ 1932 DTCIUnused2_78C 1;
BA_ "SignalType" SG_ 1932 DTCIUnused3_78C "BLN";
BA_ "PacketOrder" SG_ 1932 DTCIUnused3_78C 3;
BA_ "SignalLongName" SG_ 1932 DTCIUnused3_78C "Diagnostic Trouble Code Information Extended 78C : Unused 3";
BA_ "VNSigAllNodes" SG_ 1932 DTCIUnused3_78C 1;
BA_ "SignalType" SG_ 1932 DTCIUnused4_78C "BLN";
BA_ "PacketOrder" SG_ 1932 DTCIUnused4_78C 4;
BA_ "SignalLongName" SG_ 1932 DTCIUnused4_78C "Diagnostic Trouble Code Information Extended 78C : Unused 4";
BA_ "VNSigAllNodes" SG_ 1932 DTCIUnused4_78C 1;
BA_ "SignalType" SG_ 1932 DTCIUnused5_78C "BLN";
BA_ "PacketOrder" SG_ 1932 DTCIUnused5_78C 5;
BA_ "SignalLongName" SG_ 1932 DTCIUnused5_78C "Diagnostic Trouble Code Information Extended 78C : Unused 5";
BA_ "VNSigAllNodes" SG_ 1932 DTCIUnused5_78C 1;
BA_ "SignalType" SG_ 1932 DTCIUnused6_78C "BLN";
BA_ "PacketOrder" SG_ 1932 DTCIUnused6_78C 6;
BA_ "SignalLongName" SG_ 1932 DTCIUnused6_78C "Diagnostic Trouble Code Information Extended 78C : Unused 6";
BA_ "VNSigAllNodes" SG_ 1932 DTCIUnused6_78C 1;
BA_ "SignalType" SG_ 1932 DTCIUnused7_78C "BLN";
BA_ "PacketOrder" SG_ 1932 DTCIUnused7_78C 7;
BA_ "SignalLongName" SG_ 1932 DTCIUnused7_78C "Diagnostic Trouble Code Information Extended 78C : Unused 7";
BA_ "VNSigAllNodes" SG_ 1932 DTCIUnused7_78C 1;
BA_ "SignalType" SG_ 1932 DTCI_WrnIndRqdSt_78C "BLN";
BA_ "PacketOrder" SG_ 1932 DTCI_WrnIndRqdSt_78C 12;
BA_ "SignalLongName" SG_ 1932 DTCI_WrnIndRqdSt_78C "Diagnostic Trouble Code Information Extended 78C : Warning Indicator Requested Status";
BA_ "VNSigAllNodes" SG_ 1932 DTCI_WrnIndRqdSt_78C 1;
BA_ "SignalType" SG_ 1931 DTCI_CodeSupported_78B "BLN";
BA_ "PacketOrder" SG_ 1931 DTCI_CodeSupported_78B 19;
BA_ "SignalLongName" SG_ 1931 DTCI_CodeSupported_78B "Diagnostic Trouble Code Information Extended 78B : Code Supported";
BA_ "VNSigAllNodes" SG_ 1931 DTCI_CodeSupported_78B 1;
BA_ "SignalType" SG_ 1931 DTCI_CurrentStatus_78B "BLN";
BA_ "PacketOrder" SG_ 1931 DTCI_CurrentStatus_78B 18;
BA_ "SignalLongName" SG_ 1931 DTCI_CurrentStatus_78B "Diagnostic Trouble Code Information Extended 78B : Current Status";
BA_ "VNSigAllNodes" SG_ 1931 DTCI_CurrentStatus_78B 1;
BA_ "SignalType" SG_ 1931 DTCI_DTCFailType_78B "UNM";
BA_ "PacketOrder" SG_ 1931 DTCI_DTCFailType_78B 11;
BA_ "SignalLongName" SG_ 1931 DTCI_DTCFailType_78B "Diagnostic Trouble Code Information Extended 78B : Diagnostic Trouble Code Failure Type";
BA_ "VNSigAllNodes" SG_ 1931 DTCI_DTCFailType_78B 1;
BA_ "SignalType" SG_ 1931 DTCI_DTCFaultType_78B "ENM";
BA_ "PacketOrder" SG_ 1931 DTCI_DTCFaultType_78B 20;
BA_ "SignalLongName" SG_ 1931 DTCI_DTCFaultType_78B "Diagnostic Trouble Code Information Extended 78B : Diagnostic Trouble Code Fault Type";
BA_ "VNSigAllNodes" SG_ 1931 DTCI_DTCFaultType_78B 1;
BA_ "SignalType" SG_ 1931 DTCI_DTCNumber_78B "UNM";
BA_ "PacketOrder" SG_ 1931 DTCI_DTCNumber_78B 10;
BA_ "SignalLongName" SG_ 1931 DTCI_DTCNumber_78B "Diagnostic Trouble Code Information Extended 78B : Diagnostic Trouble Code Number";
BA_ "VNSigAllNodes" SG_ 1931 DTCI_DTCNumber_78B 1;
BA_ "SignalType" SG_ 1931 DTCI_DTCSource_78B "UNM";
BA_ "PacketOrder" SG_ 1931 DTCI_DTCSource_78B 9;
BA_ "SignalLongName" SG_ 1931 DTCI_DTCSource_78B "Diagnostic Trouble Code Information Extended 78B : Diagnostic Trouble Code Source";
BA_ "VNSigAllNodes" SG_ 1931 DTCI_DTCSource_78B 1;
BA_ "SignalType" SG_ 1931 DTCI_DTCTriggered_78B "BLN";
BA_ "PacketOrder" SG_ 1931 DTCI_DTCTriggered_78B 8;
BA_ "SignalLongName" SG_ 1931 DTCI_DTCTriggered_78B "Diagnostic Trouble Code Information Extended 78B : Diagnostic Trouble Code Triggered";
BA_ "VNSigAllNodes" SG_ 1931 DTCI_DTCTriggered_78B 1;
BA_ "SignalType" SG_ 1931 DTCI_HistStat_78B "BLN";
BA_ "PacketOrder" SG_ 1931 DTCI_HistStat_78B 15;
BA_ "SignalLongName" SG_ 1931 DTCI_HistStat_78B "Diagnostic Trouble Code Information Extended 78B : History Status";
BA_ "VNSigAllNodes" SG_ 1931 DTCI_HistStat_78B 1;
BA_ "SignalType" SG_ 1931 DTCI_TstFldCdClrdStat_78B "BLN";
BA_ "PacketOrder" SG_ 1931 DTCI_TstFldCdClrdStat_78B 16;
BA_ "SignalLongName" SG_ 1931 DTCI_TstFldCdClrdStat_78B "Diagnostic Trouble Code Information Extended 78B : Test Failed Since Code Cleared Status";
BA_ "VNSigAllNodes" SG_ 1931 DTCI_TstFldCdClrdStat_78B 1;
BA_ "SignalType" SG_ 1931 DTCI_TstFldPwrUpSt_78B "BLN";
BA_ "PacketOrder" SG_ 1931 DTCI_TstFldPwrUpSt_78B 13;
BA_ "SignalLongName" SG_ 1931 DTCI_TstFldPwrUpSt_78B "Diagnostic Trouble Code Information Extended 78B : Test Failed Since Power Up Status";
BA_ "VNSigAllNodes" SG_ 1931 DTCI_TstFldPwrUpSt_78B 1;
BA_ "SignalType" SG_ 1931 DTCI_TstNPsdCdClrdSt_78B "BLN";
BA_ "PacketOrder" SG_ 1931 DTCI_TstNPsdCdClrdSt_78B 17;
BA_ "SignalLongName" SG_ 1931 DTCI_TstNPsdCdClrdSt_78B "Diagnostic Trouble Code Information Extended 78B : Test Not Passed Since Code Cleared Status";
BA_ "VNSigAllNodes" SG_ 1931 DTCI_TstNPsdCdClrdSt_78B 1;
BA_ "SignalType" SG_ 1931 DTCI_TstNPsdPwrUpSt_78B "BLN";
BA_ "PacketOrder" SG_ 1931 DTCI_TstNPsdPwrUpSt_78B 14;
BA_ "SignalLongName" SG_ 1931 DTCI_TstNPsdPwrUpSt_78B "Diagnostic Trouble Code Information Extended 78B : Test Not Passed Since Power Up Status";
BA_ "VNSigAllNodes" SG_ 1931 DTCI_TstNPsdPwrUpSt_78B 1;
BA_ "SignalType" SG_ 1931 DTCIUnused1_78B "BLN";
BA_ "PacketOrder" SG_ 1931 DTCIUnused1_78B 1;
BA_ "SignalLongName" SG_ 1931 DTCIUnused1_78B "Diagnostic Trouble Code Information Extended 78B : Unused 1";
BA_ "VNSigAllNodes" SG_ 1931 DTCIUnused1_78B 1;
BA_ "SignalType" SG_ 1931 DTCIUnused2_78B "BLN";
BA_ "PacketOrder" SG_ 1931 DTCIUnused2_78B 2;
BA_ "SignalLongName" SG_ 1931 DTCIUnused2_78B "Diagnostic Trouble Code Information Extended 78B : Unused 2";
BA_ "VNSigAllNodes" SG_ 1931 DTCIUnused2_78B 1;
BA_ "SignalType" SG_ 1931 DTCIUnused3_78B "BLN";
BA_ "PacketOrder" SG_ 1931 DTCIUnused3_78B 3;
BA_ "SignalLongName" SG_ 1931 DTCIUnused3_78B "Diagnostic Trouble Code Information Extended 78B : Unused 3";
BA_ "VNSigAllNodes" SG_ 1931 DTCIUnused3_78B 1;
BA_ "SignalType" SG_ 1931 DTCIUnused4_78B "BLN";
BA_ "PacketOrder" SG_ 1931 DTCIUnused4_78B 4;
BA_ "SignalLongName" SG_ 1931 DTCIUnused4_78B "Diagnostic Trouble Code Information Extended 78B : Unused 4";
BA_ "VNSigAllNodes" SG_ 1931 DTCIUnused4_78B 1;
BA_ "SignalType" SG_ 1931 DTCIUnused5_78B "BLN";
BA_ "PacketOrder" SG_ 1931 DTCIUnused5_78B 5;
BA_ "SignalLongName" SG_ 1931 DTCIUnused5_78B "Diagnostic Trouble Code Information Extended 78B : Unused 5";
BA_ "VNSigAllNodes" SG_ 1931 DTCIUnused5_78B 1;
BA_ "SignalType" SG_ 1931 DTCIUnused6_78B "BLN";
BA_ "PacketOrder" SG_ 1931 DTCIUnused6_78B 6;
BA_ "SignalLongName" SG_ 1931 DTCIUnused6_78B "Diagnostic Trouble Code Information Extended 78B : Unused 6";
BA_ "VNSigAllNodes" SG_ 1931 DTCIUnused6_78B 1;
BA_ "SignalType" SG_ 1931 DTCIUnused7_78B "BLN";
BA_ "PacketOrder" SG_ 1931 DTCIUnused7_78B 7;
BA_ "SignalLongName" SG_ 1931 DTCIUnused7_78B "Diagnostic Trouble Code Information Extended 78B : Unused 7";
BA_ "VNSigAllNodes" SG_ 1931 DTCIUnused7_78B 1;
BA_ "SignalType" SG_ 1931 DTCI_WrnIndRqdSt_78B "BLN";
BA_ "PacketOrder" SG_ 1931 DTCI_WrnIndRqdSt_78B 12;
BA_ "SignalLongName" SG_ 1931 DTCI_WrnIndRqdSt_78B "Diagnostic Trouble Code Information Extended 78B : Warning Indicator Requested Status";
BA_ "VNSigAllNodes" SG_ 1931 DTCI_WrnIndRqdSt_78B 1;
BA_ "SignalType" SG_ 1930 DTCI_CodeSupported_78A "BLN";
BA_ "PacketOrder" SG_ 1930 DTCI_CodeSupported_78A 19;
BA_ "SignalLongName" SG_ 1930 DTCI_CodeSupported_78A "Diagnostic Trouble Code Information Extended 78A : Code Supported";
BA_ "VNSigAllNodes" SG_ 1930 DTCI_CodeSupported_78A 1;
BA_ "SignalType" SG_ 1930 DTCI_CurrentStatus_78A "BLN";
BA_ "PacketOrder" SG_ 1930 DTCI_CurrentStatus_78A 18;
BA_ "SignalLongName" SG_ 1930 DTCI_CurrentStatus_78A "Diagnostic Trouble Code Information Extended 78A : Current Status";
BA_ "VNSigAllNodes" SG_ 1930 DTCI_CurrentStatus_78A 1;
BA_ "SignalType" SG_ 1930 DTCI_DTCFailType_78A "UNM";
BA_ "PacketOrder" SG_ 1930 DTCI_DTCFailType_78A 11;
BA_ "SignalLongName" SG_ 1930 DTCI_DTCFailType_78A "Diagnostic Trouble Code Information Extended 78A : Diagnostic Trouble Code Failure Type";
BA_ "VNSigAllNodes" SG_ 1930 DTCI_DTCFailType_78A 1;
BA_ "SignalType" SG_ 1930 DTCI_DTCFaultType_78A "ENM";
BA_ "PacketOrder" SG_ 1930 DTCI_DTCFaultType_78A 20;
BA_ "SignalLongName" SG_ 1930 DTCI_DTCFaultType_78A "Diagnostic Trouble Code Information Extended 78A : Diagnostic Trouble Code Fault Type";
BA_ "VNSigAllNodes" SG_ 1930 DTCI_DTCFaultType_78A 1;
BA_ "SignalType" SG_ 1930 DTCI_DTCNumber_78A "UNM";
BA_ "PacketOrder" SG_ 1930 DTCI_DTCNumber_78A 10;
BA_ "SignalLongName" SG_ 1930 DTCI_DTCNumber_78A "Diagnostic Trouble Code Information Extended 78A : Diagnostic Trouble Code Number";
BA_ "VNSigAllNodes" SG_ 1930 DTCI_DTCNumber_78A 1;
BA_ "SignalType" SG_ 1930 DTCI_DTCSource_78A "UNM";
BA_ "PacketOrder" SG_ 1930 DTCI_DTCSource_78A 9;
BA_ "SignalLongName" SG_ 1930 DTCI_DTCSource_78A "Diagnostic Trouble Code Information Extended 78A : Diagnostic Trouble Code Source";
BA_ "VNSigAllNodes" SG_ 1930 DTCI_DTCSource_78A 1;
BA_ "SignalType" SG_ 1930 DTCI_DTCTriggered_78A "BLN";
BA_ "PacketOrder" SG_ 1930 DTCI_DTCTriggered_78A 8;
BA_ "SignalLongName" SG_ 1930 DTCI_DTCTriggered_78A "Diagnostic Trouble Code Information Extended 78A : Diagnostic Trouble Code Triggered";
BA_ "VNSigAllNodes" SG_ 1930 DTCI_DTCTriggered_78A 1;
BA_ "SignalType" SG_ 1930 DTCI_HistStat_78A "BLN";
BA_ "PacketOrder" SG_ 1930 DTCI_HistStat_78A 15;
BA_ "SignalLongName" SG_ 1930 DTCI_HistStat_78A "Diagnostic Trouble Code Information Extended 78A : History Status";
BA_ "VNSigAllNodes" SG_ 1930 DTCI_HistStat_78A 1;
BA_ "SignalType" SG_ 1930 DTCI_TstFldCdClrdStat_78A "BLN";
BA_ "PacketOrder" SG_ 1930 DTCI_TstFldCdClrdStat_78A 16;
BA_ "SignalLongName" SG_ 1930 DTCI_TstFldCdClrdStat_78A "Diagnostic Trouble Code Information Extended 78A : Test Failed Since Code Cleared Status";
BA_ "VNSigAllNodes" SG_ 1930 DTCI_TstFldCdClrdStat_78A 1;
BA_ "SignalType" SG_ 1930 DTCI_TstFldPwrUpSt_78A "BLN";
BA_ "PacketOrder" SG_ 1930 DTCI_TstFldPwrUpSt_78A 13;
BA_ "SignalLongName" SG_ 1930 DTCI_TstFldPwrUpSt_78A "Diagnostic Trouble Code Information Extended 78A : Test Failed Since Power Up Status";
BA_ "VNSigAllNodes" SG_ 1930 DTCI_TstFldPwrUpSt_78A 1;
BA_ "SignalType" SG_ 1930 DTCI_TstNPsdCdClrdSt_78A "BLN";
BA_ "PacketOrder" SG_ 1930 DTCI_TstNPsdCdClrdSt_78A 17;
BA_ "SignalLongName" SG_ 1930 DTCI_TstNPsdCdClrdSt_78A "Diagnostic Trouble Code Information Extended 78A : Test Not Passed Since Code Cleared Status";
BA_ "VNSigAllNodes" SG_ 1930 DTCI_TstNPsdCdClrdSt_78A 1;
BA_ "SignalType" SG_ 1930 DTCI_TstNPsdPwrUpSt_78A "BLN";
BA_ "PacketOrder" SG_ 1930 DTCI_TstNPsdPwrUpSt_78A 14;
BA_ "SignalLongName" SG_ 1930 DTCI_TstNPsdPwrUpSt_78A "Diagnostic Trouble Code Information Extended 78A : Test Not Passed Since Power Up Status";
BA_ "VNSigAllNodes" SG_ 1930 DTCI_TstNPsdPwrUpSt_78A 1;
BA_ "SignalType" SG_ 1930 DTCIUnused1_78A "BLN";
BA_ "PacketOrder" SG_ 1930 DTCIUnused1_78A 1;
BA_ "SignalLongName" SG_ 1930 DTCIUnused1_78A "Diagnostic Trouble Code Information Extended 78A : Unused 1";
BA_ "VNSigAllNodes" SG_ 1930 DTCIUnused1_78A 1;
BA_ "SignalType" SG_ 1930 DTCIUnused2_78A "BLN";
BA_ "PacketOrder" SG_ 1930 DTCIUnused2_78A 2;
BA_ "SignalLongName" SG_ 1930 DTCIUnused2_78A "Diagnostic Trouble Code Information Extended 78A : Unused 2";
BA_ "VNSigAllNodes" SG_ 1930 DTCIUnused2_78A 1;
BA_ "SignalType" SG_ 1930 DTCIUnused3_78A "BLN";
BA_ "PacketOrder" SG_ 1930 DTCIUnused3_78A 3;
BA_ "SignalLongName" SG_ 1930 DTCIUnused3_78A "Diagnostic Trouble Code Information Extended 78A : Unused 3";
BA_ "VNSigAllNodes" SG_ 1930 DTCIUnused3_78A 1;
BA_ "SignalType" SG_ 1930 DTCIUnused4_78A "BLN";
BA_ "PacketOrder" SG_ 1930 DTCIUnused4_78A 4;
BA_ "SignalLongName" SG_ 1930 DTCIUnused4_78A "Diagnostic Trouble Code Information Extended 78A : Unused 4";
BA_ "VNSigAllNodes" SG_ 1930 DTCIUnused4_78A 1;
BA_ "SignalType" SG_ 1930 DTCIUnused5_78A "BLN";
BA_ "PacketOrder" SG_ 1930 DTCIUnused5_78A 5;
BA_ "SignalLongName" SG_ 1930 DTCIUnused5_78A "Diagnostic Trouble Code Information Extended 78A : Unused 5";
BA_ "VNSigAllNodes" SG_ 1930 DTCIUnused5_78A 1;
BA_ "SignalType" SG_ 1930 DTCIUnused6_78A "BLN";
BA_ "PacketOrder" SG_ 1930 DTCIUnused6_78A 6;
BA_ "SignalLongName" SG_ 1930 DTCIUnused6_78A "Diagnostic Trouble Code Information Extended 78A : Unused 6";
BA_ "VNSigAllNodes" SG_ 1930 DTCIUnused6_78A 1;
BA_ "SignalType" SG_ 1930 DTCIUnused7_78A "BLN";
BA_ "PacketOrder" SG_ 1930 DTCIUnused7_78A 7;
BA_ "SignalLongName" SG_ 1930 DTCIUnused7_78A "Diagnostic Trouble Code Information Extended 78A : Unused 7";
BA_ "VNSigAllNodes" SG_ 1930 DTCIUnused7_78A 1;
BA_ "SignalType" SG_ 1930 DTCI_WrnIndRqdSt_78A "BLN";
BA_ "PacketOrder" SG_ 1930 DTCI_WrnIndRqdSt_78A 12;
BA_ "SignalLongName" SG_ 1930 DTCI_WrnIndRqdSt_78A "Diagnostic Trouble Code Information Extended 78A : Warning Indicator Requested Status";
BA_ "VNSigAllNodes" SG_ 1930 DTCI_WrnIndRqdSt_78A 1;
BA_ "SignalType" SG_ 1929 DTCI_CodeSupported_789 "BLN";
BA_ "PacketOrder" SG_ 1929 DTCI_CodeSupported_789 19;
BA_ "SignalLongName" SG_ 1929 DTCI_CodeSupported_789 "Diagnostic Trouble Code Information Extended 789 : Code Supported";
BA_ "VNSigAllNodes" SG_ 1929 DTCI_CodeSupported_789 1;
BA_ "SignalType" SG_ 1929 DTCI_CurrentStatus_789 "BLN";
BA_ "PacketOrder" SG_ 1929 DTCI_CurrentStatus_789 18;
BA_ "SignalLongName" SG_ 1929 DTCI_CurrentStatus_789 "Diagnostic Trouble Code Information Extended 789 : Current Status";
BA_ "VNSigAllNodes" SG_ 1929 DTCI_CurrentStatus_789 1;
BA_ "SignalType" SG_ 1929 DTCI_DTCFailType_789 "UNM";
BA_ "PacketOrder" SG_ 1929 DTCI_DTCFailType_789 11;
BA_ "SignalLongName" SG_ 1929 DTCI_DTCFailType_789 "Diagnostic Trouble Code Information Extended 789 : Diagnostic Trouble Code Failure Type";
BA_ "VNSigAllNodes" SG_ 1929 DTCI_DTCFailType_789 1;
BA_ "SignalType" SG_ 1929 DTCI_DTCFaultType_789 "ENM";
BA_ "PacketOrder" SG_ 1929 DTCI_DTCFaultType_789 20;
BA_ "SignalLongName" SG_ 1929 DTCI_DTCFaultType_789 "Diagnostic Trouble Code Information Extended 789 : Diagnostic Trouble Code Fault Type";
BA_ "VNSigAllNodes" SG_ 1929 DTCI_DTCFaultType_789 1;
BA_ "SignalType" SG_ 1929 DTCI_DTCNumber_789 "UNM";
BA_ "PacketOrder" SG_ 1929 DTCI_DTCNumber_789 10;
BA_ "SignalLongName" SG_ 1929 DTCI_DTCNumber_789 "Diagnostic Trouble Code Information Extended 789 : Diagnostic Trouble Code Number";
BA_ "VNSigAllNodes" SG_ 1929 DTCI_DTCNumber_789 1;
BA_ "SignalType" SG_ 1929 DTCI_DTCSource_789 "UNM";
BA_ "PacketOrder" SG_ 1929 DTCI_DTCSource_789 9;
BA_ "SignalLongName" SG_ 1929 DTCI_DTCSource_789 "Diagnostic Trouble Code Information Extended 789 : Diagnostic Trouble Code Source";
BA_ "VNSigAllNodes" SG_ 1929 DTCI_DTCSource_789 1;
BA_ "SignalType" SG_ 1929 DTCI_DTCTriggered_789 "BLN";
BA_ "PacketOrder" SG_ 1929 DTCI_DTCTriggered_789 8;
BA_ "SignalLongName" SG_ 1929 DTCI_DTCTriggered_789 "Diagnostic Trouble Code Information Extended 789 : Diagnostic Trouble Code Triggered";
BA_ "VNSigAllNodes" SG_ 1929 DTCI_DTCTriggered_789 1;
BA_ "SignalType" SG_ 1929 DTCI_HistStat_789 "BLN";
BA_ "PacketOrder" SG_ 1929 DTCI_HistStat_789 15;
BA_ "SignalLongName" SG_ 1929 DTCI_HistStat_789 "Diagnostic Trouble Code Information Extended 789 : History Status";
BA_ "VNSigAllNodes" SG_ 1929 DTCI_HistStat_789 1;
BA_ "SignalType" SG_ 1929 DTCI_TstFldCdClrdStat_789 "BLN";
BA_ "PacketOrder" SG_ 1929 DTCI_TstFldCdClrdStat_789 16;
BA_ "SignalLongName" SG_ 1929 DTCI_TstFldCdClrdStat_789 "Diagnostic Trouble Code Information Extended 789 : Test Failed Since Code Cleared Status";
BA_ "VNSigAllNodes" SG_ 1929 DTCI_TstFldCdClrdStat_789 1;
BA_ "SignalType" SG_ 1929 DTCI_TstFldPwrUpSt_789 "BLN";
BA_ "PacketOrder" SG_ 1929 DTCI_TstFldPwrUpSt_789 13;
BA_ "SignalLongName" SG_ 1929 DTCI_TstFldPwrUpSt_789 "Diagnostic Trouble Code Information Extended 789 : Test Failed Since Power Up Status";
BA_ "VNSigAllNodes" SG_ 1929 DTCI_TstFldPwrUpSt_789 1;
BA_ "SignalType" SG_ 1929 DTCI_TstNPsdCdClrdSt_789 "BLN";
BA_ "PacketOrder" SG_ 1929 DTCI_TstNPsdCdClrdSt_789 17;
BA_ "SignalLongName" SG_ 1929 DTCI_TstNPsdCdClrdSt_789 "Diagnostic Trouble Code Information Extended 789 : Test Not Passed Since Code Cleared Status";
BA_ "VNSigAllNodes" SG_ 1929 DTCI_TstNPsdCdClrdSt_789 1;
BA_ "SignalType" SG_ 1929 DTCI_TstNPsdPwrUpSt_789 "BLN";
BA_ "PacketOrder" SG_ 1929 DTCI_TstNPsdPwrUpSt_789 14;
BA_ "SignalLongName" SG_ 1929 DTCI_TstNPsdPwrUpSt_789 "Diagnostic Trouble Code Information Extended 789 : Test Not Passed Since Power Up Status";
BA_ "VNSigAllNodes" SG_ 1929 DTCI_TstNPsdPwrUpSt_789 1;
BA_ "SignalType" SG_ 1929 DTCIUnused1_789 "BLN";
BA_ "PacketOrder" SG_ 1929 DTCIUnused1_789 1;
BA_ "SignalLongName" SG_ 1929 DTCIUnused1_789 "Diagnostic Trouble Code Information Extended 789 : Unused 1";
BA_ "VNSigAllNodes" SG_ 1929 DTCIUnused1_789 1;
BA_ "SignalType" SG_ 1929 DTCIUnused2_789 "BLN";
BA_ "PacketOrder" SG_ 1929 DTCIUnused2_789 2;
BA_ "SignalLongName" SG_ 1929 DTCIUnused2_789 "Diagnostic Trouble Code Information Extended 789 : Unused 2";
BA_ "VNSigAllNodes" SG_ 1929 DTCIUnused2_789 1;
BA_ "SignalType" SG_ 1929 DTCIUnused3_789 "BLN";
BA_ "PacketOrder" SG_ 1929 DTCIUnused3_789 3;
BA_ "SignalLongName" SG_ 1929 DTCIUnused3_789 "Diagnostic Trouble Code Information Extended 789 : Unused 3";
BA_ "VNSigAllNodes" SG_ 1929 DTCIUnused3_789 1;
BA_ "SignalType" SG_ 1929 DTCIUnused4_789 "BLN";
BA_ "PacketOrder" SG_ 1929 DTCIUnused4_789 4;
BA_ "SignalLongName" SG_ 1929 DTCIUnused4_789 "Diagnostic Trouble Code Information Extended 789 : Unused 4";
BA_ "VNSigAllNodes" SG_ 1929 DTCIUnused4_789 1;
BA_ "SignalType" SG_ 1929 DTCIUnused5_789 "BLN";
BA_ "PacketOrder" SG_ 1929 DTCIUnused5_789 5;
BA_ "SignalLongName" SG_ 1929 DTCIUnused5_789 "Diagnostic Trouble Code Information Extended 789 : Unused 5";
BA_ "VNSigAllNodes" SG_ 1929 DTCIUnused5_789 1;
BA_ "SignalType" SG_ 1929 DTCIUnused6_789 "BLN";
BA_ "PacketOrder" SG_ 1929 DTCIUnused6_789 6;
BA_ "SignalLongName" SG_ 1929 DTCIUnused6_789 "Diagnostic Trouble Code Information Extended 789 : Unused 6";
BA_ "VNSigAllNodes" SG_ 1929 DTCIUnused6_789 1;
BA_ "SignalType" SG_ 1929 DTCIUnused7_789 "BLN";
BA_ "PacketOrder" SG_ 1929 DTCIUnused7_789 7;
BA_ "SignalLongName" SG_ 1929 DTCIUnused7_789 "Diagnostic Trouble Code Information Extended 789 : Unused 7";
BA_ "VNSigAllNodes" SG_ 1929 DTCIUnused7_789 1;
BA_ "SignalType" SG_ 1929 DTCI_WrnIndRqdSt_789 "BLN";
BA_ "PacketOrder" SG_ 1929 DTCI_WrnIndRqdSt_789 12;
BA_ "SignalLongName" SG_ 1929 DTCI_WrnIndRqdSt_789 "Diagnostic Trouble Code Information Extended 789 : Warning Indicator Requested Status";
BA_ "VNSigAllNodes" SG_ 1929 DTCI_WrnIndRqdSt_789 1;
BA_ "SignalType" SG_ 1928 DTCI_CodeSupported_788 "BLN";
BA_ "PacketOrder" SG_ 1928 DTCI_CodeSupported_788 19;
BA_ "SignalLongName" SG_ 1928 DTCI_CodeSupported_788 "Diagnostic Trouble Code Information Extended 788 : Code Supported";
BA_ "VNSigAllNodes" SG_ 1928 DTCI_CodeSupported_788 1;
BA_ "SignalType" SG_ 1928 DTCI_CurrentStatus_788 "BLN";
BA_ "PacketOrder" SG_ 1928 DTCI_CurrentStatus_788 18;
BA_ "SignalLongName" SG_ 1928 DTCI_CurrentStatus_788 "Diagnostic Trouble Code Information Extended 788 : Current Status";
BA_ "VNSigAllNodes" SG_ 1928 DTCI_CurrentStatus_788 1;
BA_ "SignalType" SG_ 1928 DTCI_DTCFailType_788 "UNM";
BA_ "PacketOrder" SG_ 1928 DTCI_DTCFailType_788 11;
BA_ "SignalLongName" SG_ 1928 DTCI_DTCFailType_788 "Diagnostic Trouble Code Information Extended 788 : Diagnostic Trouble Code Failure Type";
BA_ "VNSigAllNodes" SG_ 1928 DTCI_DTCFailType_788 1;
BA_ "SignalType" SG_ 1928 DTCI_DTCFaultType_788 "ENM";
BA_ "PacketOrder" SG_ 1928 DTCI_DTCFaultType_788 20;
BA_ "SignalLongName" SG_ 1928 DTCI_DTCFaultType_788 "Diagnostic Trouble Code Information Extended 788 : Diagnostic Trouble Code Fault Type";
BA_ "VNSigAllNodes" SG_ 1928 DTCI_DTCFaultType_788 1;
BA_ "SignalType" SG_ 1928 DTCI_DTCNumber_788 "UNM";
BA_ "PacketOrder" SG_ 1928 DTCI_DTCNumber_788 10;
BA_ "SignalLongName" SG_ 1928 DTCI_DTCNumber_788 "Diagnostic Trouble Code Information Extended 788 : Diagnostic Trouble Code Number";
BA_ "VNSigAllNodes" SG_ 1928 DTCI_DTCNumber_788 1;
BA_ "SignalType" SG_ 1928 DTCI_DTCSource_788 "UNM";
BA_ "PacketOrder" SG_ 1928 DTCI_DTCSource_788 9;
BA_ "SignalLongName" SG_ 1928 DTCI_DTCSource_788 "Diagnostic Trouble Code Information Extended 788 : Diagnostic Trouble Code Source";
BA_ "VNSigAllNodes" SG_ 1928 DTCI_DTCSource_788 1;
BA_ "SignalType" SG_ 1928 DTCI_DTCTriggered_788 "BLN";
BA_ "PacketOrder" SG_ 1928 DTCI_DTCTriggered_788 8;
BA_ "SignalLongName" SG_ 1928 DTCI_DTCTriggered_788 "Diagnostic Trouble Code Information Extended 788 : Diagnostic Trouble Code Triggered";
BA_ "VNSigAllNodes" SG_ 1928 DTCI_DTCTriggered_788 1;
BA_ "SignalType" SG_ 1928 DTCI_HistStat_788 "BLN";
BA_ "PacketOrder" SG_ 1928 DTCI_HistStat_788 15;
BA_ "SignalLongName" SG_ 1928 DTCI_HistStat_788 "Diagnostic Trouble Code Information Extended 788 : History Status";
BA_ "VNSigAllNodes" SG_ 1928 DTCI_HistStat_788 1;
BA_ "SignalType" SG_ 1928 DTCI_TstFldCdClrdStat_788 "BLN";
BA_ "PacketOrder" SG_ 1928 DTCI_TstFldCdClrdStat_788 16;
BA_ "SignalLongName" SG_ 1928 DTCI_TstFldCdClrdStat_788 "Diagnostic Trouble Code Information Extended 788 : Test Failed Since Code Cleared Status";
BA_ "VNSigAllNodes" SG_ 1928 DTCI_TstFldCdClrdStat_788 1;
BA_ "SignalType" SG_ 1928 DTCI_TstFldPwrUpSt_788 "BLN";
BA_ "PacketOrder" SG_ 1928 DTCI_TstFldPwrUpSt_788 13;
BA_ "SignalLongName" SG_ 1928 DTCI_TstFldPwrUpSt_788 "Diagnostic Trouble Code Information Extended 788 : Test Failed Since Power Up Status";
BA_ "VNSigAllNodes" SG_ 1928 DTCI_TstFldPwrUpSt_788 1;
BA_ "SignalType" SG_ 1928 DTCI_TstNPsdCdClrdSt_788 "BLN";
BA_ "PacketOrder" SG_ 1928 DTCI_TstNPsdCdClrdSt_788 17;
BA_ "SignalLongName" SG_ 1928 DTCI_TstNPsdCdClrdSt_788 "Diagnostic Trouble Code Information Extended 788 : Test Not Passed Since Code Cleared Status";
BA_ "VNSigAllNodes" SG_ 1928 DTCI_TstNPsdCdClrdSt_788 1;
BA_ "SignalType" SG_ 1928 DTCI_TstNPsdPwrUpSt_788 "BLN";
BA_ "PacketOrder" SG_ 1928 DTCI_TstNPsdPwrUpSt_788 14;
BA_ "SignalLongName" SG_ 1928 DTCI_TstNPsdPwrUpSt_788 "Diagnostic Trouble Code Information Extended 788 : Test Not Passed Since Power Up Status";
BA_ "VNSigAllNodes" SG_ 1928 DTCI_TstNPsdPwrUpSt_788 1;
BA_ "SignalType" SG_ 1928 DTCIUnused1_788 "BLN";
BA_ "PacketOrder" SG_ 1928 DTCIUnused1_788 1;
BA_ "SignalLongName" SG_ 1928 DTCIUnused1_788 "Diagnostic Trouble Code Information Extended 788 : Unused 1";
BA_ "VNSigAllNodes" SG_ 1928 DTCIUnused1_788 1;
BA_ "SignalType" SG_ 1928 DTCIUnused2_788 "BLN";
BA_ "PacketOrder" SG_ 1928 DTCIUnused2_788 2;
BA_ "SignalLongName" SG_ 1928 DTCIUnused2_788 "Diagnostic Trouble Code Information Extended 788 : Unused 2";
BA_ "VNSigAllNodes" SG_ 1928 DTCIUnused2_788 1;
BA_ "SignalType" SG_ 1928 DTCIUnused3_788 "BLN";
BA_ "PacketOrder" SG_ 1928 DTCIUnused3_788 3;
BA_ "SignalLongName" SG_ 1928 DTCIUnused3_788 "Diagnostic Trouble Code Information Extended 788 : Unused 3";
BA_ "VNSigAllNodes" SG_ 1928 DTCIUnused3_788 1;
BA_ "SignalType" SG_ 1928 DTCIUnused4_788 "BLN";
BA_ "PacketOrder" SG_ 1928 DTCIUnused4_788 4;
BA_ "SignalLongName" SG_ 1928 DTCIUnused4_788 "Diagnostic Trouble Code Information Extended 788 : Unused 4";
BA_ "VNSigAllNodes" SG_ 1928 DTCIUnused4_788 1;
BA_ "SignalType" SG_ 1928 DTCIUnused5_788 "BLN";
BA_ "PacketOrder" SG_ 1928 DTCIUnused5_788 5;
BA_ "SignalLongName" SG_ 1928 DTCIUnused5_788 "Diagnostic Trouble Code Information Extended 788 : Unused 5";
BA_ "VNSigAllNodes" SG_ 1928 DTCIUnused5_788 1;
BA_ "SignalType" SG_ 1928 DTCIUnused6_788 "BLN";
BA_ "PacketOrder" SG_ 1928 DTCIUnused6_788 6;
BA_ "SignalLongName" SG_ 1928 DTCIUnused6_788 "Diagnostic Trouble Code Information Extended 788 : Unused 6";
BA_ "VNSigAllNodes" SG_ 1928 DTCIUnused6_788 1;
BA_ "SignalType" SG_ 1928 DTCIUnused7_788 "BLN";
BA_ "PacketOrder" SG_ 1928 DTCIUnused7_788 7;
BA_ "SignalLongName" SG_ 1928 DTCIUnused7_788 "Diagnostic Trouble Code Information Extended 788 : Unused 7";
BA_ "VNSigAllNodes" SG_ 1928 DTCIUnused7_788 1;
BA_ "SignalType" SG_ 1928 DTCI_WrnIndRqdSt_788 "BLN";
BA_ "PacketOrder" SG_ 1928 DTCI_WrnIndRqdSt_788 12;
BA_ "SignalLongName" SG_ 1928 DTCI_WrnIndRqdSt_788 "Diagnostic Trouble Code Information Extended 788 : Warning Indicator Requested Status";
BA_ "VNSigAllNodes" SG_ 1928 DTCI_WrnIndRqdSt_788 1;
BA_ "SignalType" SG_ 1927 DTCI_CodeSupported_787 "BLN";
BA_ "PacketOrder" SG_ 1927 DTCI_CodeSupported_787 19;
BA_ "SignalLongName" SG_ 1927 DTCI_CodeSupported_787 "Diagnostic Trouble Code Information Extended 787 : Code Supported";
BA_ "VNSigAllNodes" SG_ 1927 DTCI_CodeSupported_787 1;
BA_ "SignalType" SG_ 1927 DTCI_CurrentStatus_787 "BLN";
BA_ "PacketOrder" SG_ 1927 DTCI_CurrentStatus_787 18;
BA_ "SignalLongName" SG_ 1927 DTCI_CurrentStatus_787 "Diagnostic Trouble Code Information Extended 787 : Current Status";
BA_ "VNSigAllNodes" SG_ 1927 DTCI_CurrentStatus_787 1;
BA_ "SignalType" SG_ 1927 DTCI_DTCFailType_787 "UNM";
BA_ "PacketOrder" SG_ 1927 DTCI_DTCFailType_787 11;
BA_ "SignalLongName" SG_ 1927 DTCI_DTCFailType_787 "Diagnostic Trouble Code Information Extended 787 : Diagnostic Trouble Code Failure Type";
BA_ "VNSigAllNodes" SG_ 1927 DTCI_DTCFailType_787 1;
BA_ "SignalType" SG_ 1927 DTCI_DTCFaultType_787 "ENM";
BA_ "PacketOrder" SG_ 1927 DTCI_DTCFaultType_787 20;
BA_ "SignalLongName" SG_ 1927 DTCI_DTCFaultType_787 "Diagnostic Trouble Code Information Extended 787 : Diagnostic Trouble Code Fault Type";
BA_ "VNSigAllNodes" SG_ 1927 DTCI_DTCFaultType_787 1;
BA_ "SignalType" SG_ 1927 DTCI_DTCNumber_787 "UNM";
BA_ "PacketOrder" SG_ 1927 DTCI_DTCNumber_787 10;
BA_ "SignalLongName" SG_ 1927 DTCI_DTCNumber_787 "Diagnostic Trouble Code Information Extended 787 : Diagnostic Trouble Code Number";
BA_ "VNSigAllNodes" SG_ 1927 DTCI_DTCNumber_787 1;
BA_ "SignalType" SG_ 1927 DTCI_DTCSource_787 "UNM";
BA_ "PacketOrder" SG_ 1927 DTCI_DTCSource_787 9;
BA_ "SignalLongName" SG_ 1927 DTCI_DTCSource_787 "Diagnostic Trouble Code Information Extended 787 : Diagnostic Trouble Code Source";
BA_ "VNSigAllNodes" SG_ 1927 DTCI_DTCSource_787 1;
BA_ "SignalType" SG_ 1927 DTCI_DTCTriggered_787 "BLN";
BA_ "PacketOrder" SG_ 1927 DTCI_DTCTriggered_787 8;
BA_ "SignalLongName" SG_ 1927 DTCI_DTCTriggered_787 "Diagnostic Trouble Code Information Extended 787 : Diagnostic Trouble Code Triggered";
BA_ "VNSigAllNodes" SG_ 1927 DTCI_DTCTriggered_787 1;
BA_ "SignalType" SG_ 1927 DTCI_HistStat_787 "BLN";
BA_ "PacketOrder" SG_ 1927 DTCI_HistStat_787 15;
BA_ "SignalLongName" SG_ 1927 DTCI_HistStat_787 "Diagnostic Trouble Code Information Extended 787 : History Status";
BA_ "VNSigAllNodes" SG_ 1927 DTCI_HistStat_787 1;
BA_ "SignalType" SG_ 1927 DTCI_TstFldCdClrdStat_787 "BLN";
BA_ "PacketOrder" SG_ 1927 DTCI_TstFldCdClrdStat_787 16;
BA_ "SignalLongName" SG_ 1927 DTCI_TstFldCdClrdStat_787 "Diagnostic Trouble Code Information Extended 787 : Test Failed Since Code Cleared Status";
BA_ "VNSigAllNodes" SG_ 1927 DTCI_TstFldCdClrdStat_787 1;
BA_ "SignalType" SG_ 1927 DTCI_TstFldPwrUpSt_787 "BLN";
BA_ "PacketOrder" SG_ 1927 DTCI_TstFldPwrUpSt_787 13;
BA_ "SignalLongName" SG_ 1927 DTCI_TstFldPwrUpSt_787 "Diagnostic Trouble Code Information Extended 787 : Test Failed Since Power Up Status";
BA_ "VNSigAllNodes" SG_ 1927 DTCI_TstFldPwrUpSt_787 1;
BA_ "SignalType" SG_ 1927 DTCI_TstNPsdCdClrdSt_787 "BLN";
BA_ "PacketOrder" SG_ 1927 DTCI_TstNPsdCdClrdSt_787 17;
BA_ "SignalLongName" SG_ 1927 DTCI_TstNPsdCdClrdSt_787 "Diagnostic Trouble Code Information Extended 787 : Test Not Passed Since Code Cleared Status";
BA_ "VNSigAllNodes" SG_ 1927 DTCI_TstNPsdCdClrdSt_787 1;
BA_ "SignalType" SG_ 1927 DTCI_TstNPsdPwrUpSt_787 "BLN";
BA_ "PacketOrder" SG_ 1927 DTCI_TstNPsdPwrUpSt_787 14;
BA_ "SignalLongName" SG_ 1927 DTCI_TstNPsdPwrUpSt_787 "Diagnostic Trouble Code Information Extended 787 : Test Not Passed Since Power Up Status";
BA_ "VNSigAllNodes" SG_ 1927 DTCI_TstNPsdPwrUpSt_787 1;
BA_ "SignalType" SG_ 1927 DTCIUnused1_787 "BLN";
BA_ "PacketOrder" SG_ 1927 DTCIUnused1_787 1;
BA_ "SignalLongName" SG_ 1927 DTCIUnused1_787 "Diagnostic Trouble Code Information Extended 787 : Unused 1";
BA_ "VNSigAllNodes" SG_ 1927 DTCIUnused1_787 1;
BA_ "SignalType" SG_ 1927 DTCIUnused2_787 "BLN";
BA_ "PacketOrder" SG_ 1927 DTCIUnused2_787 2;
BA_ "SignalLongName" SG_ 1927 DTCIUnused2_787 "Diagnostic Trouble Code Information Extended 787 : Unused 2";
BA_ "VNSigAllNodes" SG_ 1927 DTCIUnused2_787 1;
BA_ "SignalType" SG_ 1927 DTCIUnused3_787 "BLN";
BA_ "PacketOrder" SG_ 1927 DTCIUnused3_787 3;
BA_ "SignalLongName" SG_ 1927 DTCIUnused3_787 "Diagnostic Trouble Code Information Extended 787 : Unused 3";
BA_ "VNSigAllNodes" SG_ 1927 DTCIUnused3_787 1;
BA_ "SignalType" SG_ 1927 DTCIUnused4_787 "BLN";
BA_ "PacketOrder" SG_ 1927 DTCIUnused4_787 4;
BA_ "SignalLongName" SG_ 1927 DTCIUnused4_787 "Diagnostic Trouble Code Information Extended 787 : Unused 4";
BA_ "VNSigAllNodes" SG_ 1927 DTCIUnused4_787 1;
BA_ "SignalType" SG_ 1927 DTCIUnused5_787 "BLN";
BA_ "PacketOrder" SG_ 1927 DTCIUnused5_787 5;
BA_ "SignalLongName" SG_ 1927 DTCIUnused5_787 "Diagnostic Trouble Code Information Extended 787 : Unused 5";
BA_ "VNSigAllNodes" SG_ 1927 DTCIUnused5_787 1;
BA_ "SignalType" SG_ 1927 DTCIUnused6_787 "BLN";
BA_ "PacketOrder" SG_ 1927 DTCIUnused6_787 6;
BA_ "SignalLongName" SG_ 1927 DTCIUnused6_787 "Diagnostic Trouble Code Information Extended 787 : Unused 6";
BA_ "VNSigAllNodes" SG_ 1927 DTCIUnused6_787 1;
BA_ "SignalType" SG_ 1927 DTCIUnused7_787 "BLN";
BA_ "PacketOrder" SG_ 1927 DTCIUnused7_787 7;
BA_ "SignalLongName" SG_ 1927 DTCIUnused7_787 "Diagnostic Trouble Code Information Extended 787 : Unused 7";
BA_ "VNSigAllNodes" SG_ 1927 DTCIUnused7_787 1;
BA_ "SignalType" SG_ 1927 DTCI_WrnIndRqdSt_787 "BLN";
BA_ "PacketOrder" SG_ 1927 DTCI_WrnIndRqdSt_787 12;
BA_ "SignalLongName" SG_ 1927 DTCI_WrnIndRqdSt_787 "Diagnostic Trouble Code Information Extended 787 : Warning Indicator Requested Status";
BA_ "VNSigAllNodes" SG_ 1927 DTCI_WrnIndRqdSt_787 1;
BA_ "SignalType" SG_ 1926 DTCI_CodeSupported_786 "BLN";
BA_ "PacketOrder" SG_ 1926 DTCI_CodeSupported_786 19;
BA_ "SignalLongName" SG_ 1926 DTCI_CodeSupported_786 "Diagnostic Trouble Code Information Extended 786 : Code Supported";
BA_ "VNSigAllNodes" SG_ 1926 DTCI_CodeSupported_786 1;
BA_ "SignalType" SG_ 1926 DTCI_CurrentStatus_786 "BLN";
BA_ "PacketOrder" SG_ 1926 DTCI_CurrentStatus_786 18;
BA_ "SignalLongName" SG_ 1926 DTCI_CurrentStatus_786 "Diagnostic Trouble Code Information Extended 786 : Current Status";
BA_ "VNSigAllNodes" SG_ 1926 DTCI_CurrentStatus_786 1;
BA_ "SignalType" SG_ 1926 DTCI_DTCFailType_786 "UNM";
BA_ "PacketOrder" SG_ 1926 DTCI_DTCFailType_786 11;
BA_ "SignalLongName" SG_ 1926 DTCI_DTCFailType_786 "Diagnostic Trouble Code Information Extended 786 : Diagnostic Trouble Code Failure Type";
BA_ "VNSigAllNodes" SG_ 1926 DTCI_DTCFailType_786 1;
BA_ "SignalType" SG_ 1926 DTCI_DTCFaultType_786 "ENM";
BA_ "PacketOrder" SG_ 1926 DTCI_DTCFaultType_786 20;
BA_ "SignalLongName" SG_ 1926 DTCI_DTCFaultType_786 "Diagnostic Trouble Code Information Extended 786 : Diagnostic Trouble Code Fault Type";
BA_ "VNSigAllNodes" SG_ 1926 DTCI_DTCFaultType_786 1;
BA_ "SignalType" SG_ 1926 DTCI_DTCNumber_786 "UNM";
BA_ "PacketOrder" SG_ 1926 DTCI_DTCNumber_786 10;
BA_ "SignalLongName" SG_ 1926 DTCI_DTCNumber_786 "Diagnostic Trouble Code Information Extended 786 : Diagnostic Trouble Code Number";
BA_ "VNSigAllNodes" SG_ 1926 DTCI_DTCNumber_786 1;
BA_ "SignalType" SG_ 1926 DTCI_DTCSource_786 "UNM";
BA_ "PacketOrder" SG_ 1926 DTCI_DTCSource_786 9;
BA_ "SignalLongName" SG_ 1926 DTCI_DTCSource_786 "Diagnostic Trouble Code Information Extended 786 : Diagnostic Trouble Code Source";
BA_ "VNSigAllNodes" SG_ 1926 DTCI_DTCSource_786 1;
BA_ "SignalType" SG_ 1926 DTCI_DTCTriggered_786 "BLN";
BA_ "PacketOrder" SG_ 1926 DTCI_DTCTriggered_786 8;
BA_ "SignalLongName" SG_ 1926 DTCI_DTCTriggered_786 "Diagnostic Trouble Code Information Extended 786 : Diagnostic Trouble Code Triggered";
BA_ "VNSigAllNodes" SG_ 1926 DTCI_DTCTriggered_786 1;
BA_ "SignalType" SG_ 1926 DTCI_HistStat_786 "BLN";
BA_ "PacketOrder" SG_ 1926 DTCI_HistStat_786 15;
BA_ "SignalLongName" SG_ 1926 DTCI_HistStat_786 "Diagnostic Trouble Code Information Extended 786 : History Status";
BA_ "VNSigAllNodes" SG_ 1926 DTCI_HistStat_786 1;
BA_ "SignalType" SG_ 1926 DTCI_TstFldCdClrdStat_786 "BLN";
BA_ "PacketOrder" SG_ 1926 DTCI_TstFldCdClrdStat_786 16;
BA_ "SignalLongName" SG_ 1926 DTCI_TstFldCdClrdStat_786 "Diagnostic Trouble Code Information Extended 786 : Test Failed Since Code Cleared Status";
BA_ "VNSigAllNodes" SG_ 1926 DTCI_TstFldCdClrdStat_786 1;
BA_ "SignalType" SG_ 1926 DTCI_TstFldPwrUpSt_786 "BLN";
BA_ "PacketOrder" SG_ 1926 DTCI_TstFldPwrUpSt_786 13;
BA_ "SignalLongName" SG_ 1926 DTCI_TstFldPwrUpSt_786 "Diagnostic Trouble Code Information Extended 786 : Test Failed Since Power Up Status";
BA_ "VNSigAllNodes" SG_ 1926 DTCI_TstFldPwrUpSt_786 1;
BA_ "SignalType" SG_ 1926 DTCI_TstNPsdCdClrdSt_786 "BLN";
BA_ "PacketOrder" SG_ 1926 DTCI_TstNPsdCdClrdSt_786 17;
BA_ "SignalLongName" SG_ 1926 DTCI_TstNPsdCdClrdSt_786 "Diagnostic Trouble Code Information Extended 786 : Test Not Passed Since Code Cleared Status";
BA_ "VNSigAllNodes" SG_ 1926 DTCI_TstNPsdCdClrdSt_786 1;
BA_ "SignalType" SG_ 1926 DTCI_TstNPsdPwrUpSt_786 "BLN";
BA_ "PacketOrder" SG_ 1926 DTCI_TstNPsdPwrUpSt_786 14;
BA_ "SignalLongName" SG_ 1926 DTCI_TstNPsdPwrUpSt_786 "Diagnostic Trouble Code Information Extended 786 : Test Not Passed Since Power Up Status";
BA_ "VNSigAllNodes" SG_ 1926 DTCI_TstNPsdPwrUpSt_786 1;
BA_ "SignalType" SG_ 1926 DTCIUnused1_786 "BLN";
BA_ "PacketOrder" SG_ 1926 DTCIUnused1_786 1;
BA_ "SignalLongName" SG_ 1926 DTCIUnused1_786 "Diagnostic Trouble Code Information Extended 786 : Unused 1";
BA_ "VNSigAllNodes" SG_ 1926 DTCIUnused1_786 1;
BA_ "SignalType" SG_ 1926 DTCIUnused2_786 "BLN";
BA_ "PacketOrder" SG_ 1926 DTCIUnused2_786 2;
BA_ "SignalLongName" SG_ 1926 DTCIUnused2_786 "Diagnostic Trouble Code Information Extended 786 : Unused 2";
BA_ "VNSigAllNodes" SG_ 1926 DTCIUnused2_786 1;
BA_ "SignalType" SG_ 1926 DTCIUnused3_786 "BLN";
BA_ "PacketOrder" SG_ 1926 DTCIUnused3_786 3;
BA_ "SignalLongName" SG_ 1926 DTCIUnused3_786 "Diagnostic Trouble Code Information Extended 786 : Unused 3";
BA_ "VNSigAllNodes" SG_ 1926 DTCIUnused3_786 1;
BA_ "SignalType" SG_ 1926 DTCIUnused4_786 "BLN";
BA_ "PacketOrder" SG_ 1926 DTCIUnused4_786 4;
BA_ "SignalLongName" SG_ 1926 DTCIUnused4_786 "Diagnostic Trouble Code Information Extended 786 : Unused 4";
BA_ "VNSigAllNodes" SG_ 1926 DTCIUnused4_786 1;
BA_ "SignalType" SG_ 1926 DTCIUnused5_786 "BLN";
BA_ "PacketOrder" SG_ 1926 DTCIUnused5_786 5;
BA_ "SignalLongName" SG_ 1926 DTCIUnused5_786 "Diagnostic Trouble Code Information Extended 786 : Unused 5";
BA_ "VNSigAllNodes" SG_ 1926 DTCIUnused5_786 1;
BA_ "SignalType" SG_ 1926 DTCIUnused6_786 "BLN";
BA_ "PacketOrder" SG_ 1926 DTCIUnused6_786 6;
BA_ "SignalLongName" SG_ 1926 DTCIUnused6_786 "Diagnostic Trouble Code Information Extended 786 : Unused 6";
BA_ "VNSigAllNodes" SG_ 1926 DTCIUnused6_786 1;
BA_ "SignalType" SG_ 1926 DTCIUnused7_786 "BLN";
BA_ "PacketOrder" SG_ 1926 DTCIUnused7_786 7;
BA_ "SignalLongName" SG_ 1926 DTCIUnused7_786 "Diagnostic Trouble Code Information Extended 786 : Unused 7";
BA_ "VNSigAllNodes" SG_ 1926 DTCIUnused7_786 1;
BA_ "SignalType" SG_ 1926 DTCI_WrnIndRqdSt_786 "BLN";
BA_ "PacketOrder" SG_ 1926 DTCI_WrnIndRqdSt_786 12;
BA_ "SignalLongName" SG_ 1926 DTCI_WrnIndRqdSt_786 "Diagnostic Trouble Code Information Extended 786 : Warning Indicator Requested Status";
BA_ "VNSigAllNodes" SG_ 1926 DTCI_WrnIndRqdSt_786 1;
BA_ "SignalType" SG_ 1925 DTCI_CodeSupported_785 "BLN";
BA_ "PacketOrder" SG_ 1925 DTCI_CodeSupported_785 19;
BA_ "SignalLongName" SG_ 1925 DTCI_CodeSupported_785 "Diagnostic Trouble Code Information Extended 785 : Code Supported";
BA_ "VNSigAllNodes" SG_ 1925 DTCI_CodeSupported_785 1;
BA_ "SignalType" SG_ 1925 DTCI_CurrentStatus_785 "BLN";
BA_ "PacketOrder" SG_ 1925 DTCI_CurrentStatus_785 18;
BA_ "SignalLongName" SG_ 1925 DTCI_CurrentStatus_785 "Diagnostic Trouble Code Information Extended 785 : Current Status";
BA_ "VNSigAllNodes" SG_ 1925 DTCI_CurrentStatus_785 1;
BA_ "SignalType" SG_ 1925 DTCI_DTCFailType_785 "UNM";
BA_ "PacketOrder" SG_ 1925 DTCI_DTCFailType_785 11;
BA_ "SignalLongName" SG_ 1925 DTCI_DTCFailType_785 "Diagnostic Trouble Code Information Extended 785 : Diagnostic Trouble Code Failure Type";
BA_ "VNSigAllNodes" SG_ 1925 DTCI_DTCFailType_785 1;
BA_ "SignalType" SG_ 1925 DTCI_DTCFaultType_785 "ENM";
BA_ "PacketOrder" SG_ 1925 DTCI_DTCFaultType_785 20;
BA_ "SignalLongName" SG_ 1925 DTCI_DTCFaultType_785 "Diagnostic Trouble Code Information Extended 785 : Diagnostic Trouble Code Fault Type";
BA_ "VNSigAllNodes" SG_ 1925 DTCI_DTCFaultType_785 1;
BA_ "SignalType" SG_ 1925 DTCI_DTCNumber_785 "UNM";
BA_ "PacketOrder" SG_ 1925 DTCI_DTCNumber_785 10;
BA_ "SignalLongName" SG_ 1925 DTCI_DTCNumber_785 "Diagnostic Trouble Code Information Extended 785 : Diagnostic Trouble Code Number";
BA_ "VNSigAllNodes" SG_ 1925 DTCI_DTCNumber_785 1;
BA_ "SignalType" SG_ 1925 DTCI_DTCSource_785 "UNM";
BA_ "PacketOrder" SG_ 1925 DTCI_DTCSource_785 9;
BA_ "SignalLongName" SG_ 1925 DTCI_DTCSource_785 "Diagnostic Trouble Code Information Extended 785 : Diagnostic Trouble Code Source";
BA_ "VNSigAllNodes" SG_ 1925 DTCI_DTCSource_785 1;
BA_ "SignalType" SG_ 1925 DTCI_DTCTriggered_785 "BLN";
BA_ "PacketOrder" SG_ 1925 DTCI_DTCTriggered_785 8;
BA_ "SignalLongName" SG_ 1925 DTCI_DTCTriggered_785 "Diagnostic Trouble Code Information Extended 785 : Diagnostic Trouble Code Triggered";
BA_ "VNSigAllNodes" SG_ 1925 DTCI_DTCTriggered_785 1;
BA_ "SignalType" SG_ 1925 DTCI_HistStat_785 "BLN";
BA_ "PacketOrder" SG_ 1925 DTCI_HistStat_785 15;
BA_ "SignalLongName" SG_ 1925 DTCI_HistStat_785 "Diagnostic Trouble Code Information Extended 785 : History Status";
BA_ "VNSigAllNodes" SG_ 1925 DTCI_HistStat_785 1;
BA_ "SignalType" SG_ 1925 DTCI_TstFldCdClrdStat_785 "BLN";
BA_ "PacketOrder" SG_ 1925 DTCI_TstFldCdClrdStat_785 16;
BA_ "SignalLongName" SG_ 1925 DTCI_TstFldCdClrdStat_785 "Diagnostic Trouble Code Information Extended 785 : Test Failed Since Code Cleared Status";
BA_ "VNSigAllNodes" SG_ 1925 DTCI_TstFldCdClrdStat_785 1;
BA_ "SignalType" SG_ 1925 DTCI_TstFldPwrUpSt_785 "BLN";
BA_ "PacketOrder" SG_ 1925 DTCI_TstFldPwrUpSt_785 13;
BA_ "SignalLongName" SG_ 1925 DTCI_TstFldPwrUpSt_785 "Diagnostic Trouble Code Information Extended 785 : Test Failed Since Power Up Status";
BA_ "VNSigAllNodes" SG_ 1925 DTCI_TstFldPwrUpSt_785 1;
BA_ "SignalType" SG_ 1925 DTCI_TstNPsdCdClrdSt_785 "BLN";
BA_ "PacketOrder" SG_ 1925 DTCI_TstNPsdCdClrdSt_785 17;
BA_ "SignalLongName" SG_ 1925 DTCI_TstNPsdCdClrdSt_785 "Diagnostic Trouble Code Information Extended 785 : Test Not Passed Since Code Cleared Status";
BA_ "VNSigAllNodes" SG_ 1925 DTCI_TstNPsdCdClrdSt_785 1;
BA_ "SignalType" SG_ 1925 DTCI_TstNPsdPwrUpSt_785 "BLN";
BA_ "PacketOrder" SG_ 1925 DTCI_TstNPsdPwrUpSt_785 14;
BA_ "SignalLongName" SG_ 1925 DTCI_TstNPsdPwrUpSt_785 "Diagnostic Trouble Code Information Extended 785 : Test Not Passed Since Power Up Status";
BA_ "VNSigAllNodes" SG_ 1925 DTCI_TstNPsdPwrUpSt_785 1;
BA_ "SignalType" SG_ 1925 DTCIUnused1_785 "BLN";
BA_ "PacketOrder" SG_ 1925 DTCIUnused1_785 1;
BA_ "SignalLongName" SG_ 1925 DTCIUnused1_785 "Diagnostic Trouble Code Information Extended 785 : Unused 1";
BA_ "VNSigAllNodes" SG_ 1925 DTCIUnused1_785 1;
BA_ "SignalType" SG_ 1925 DTCIUnused2_785 "BLN";
BA_ "PacketOrder" SG_ 1925 DTCIUnused2_785 2;
BA_ "SignalLongName" SG_ 1925 DTCIUnused2_785 "Diagnostic Trouble Code Information Extended 785 : Unused 2";
BA_ "VNSigAllNodes" SG_ 1925 DTCIUnused2_785 1;
BA_ "SignalType" SG_ 1925 DTCIUnused3_785 "BLN";
BA_ "PacketOrder" SG_ 1925 DTCIUnused3_785 3;
BA_ "SignalLongName" SG_ 1925 DTCIUnused3_785 "Diagnostic Trouble Code Information Extended 785 : Unused 3";
BA_ "VNSigAllNodes" SG_ 1925 DTCIUnused3_785 1;
BA_ "SignalType" SG_ 1925 DTCIUnused4_785 "BLN";
BA_ "PacketOrder" SG_ 1925 DTCIUnused4_785 4;
BA_ "SignalLongName" SG_ 1925 DTCIUnused4_785 "Diagnostic Trouble Code Information Extended 785 : Unused 4";
BA_ "VNSigAllNodes" SG_ 1925 DTCIUnused4_785 1;
BA_ "SignalType" SG_ 1925 DTCIUnused5_785 "BLN";
BA_ "PacketOrder" SG_ 1925 DTCIUnused5_785 5;
BA_ "SignalLongName" SG_ 1925 DTCIUnused5_785 "Diagnostic Trouble Code Information Extended 785 : Unused 5";
BA_ "VNSigAllNodes" SG_ 1925 DTCIUnused5_785 1;
BA_ "SignalType" SG_ 1925 DTCIUnused6_785 "BLN";
BA_ "PacketOrder" SG_ 1925 DTCIUnused6_785 6;
BA_ "SignalLongName" SG_ 1925 DTCIUnused6_785 "Diagnostic Trouble Code Information Extended 785 : Unused 6";
BA_ "VNSigAllNodes" SG_ 1925 DTCIUnused6_785 1;
BA_ "SignalType" SG_ 1925 DTCIUnused7_785 "BLN";
BA_ "PacketOrder" SG_ 1925 DTCIUnused7_785 7;
BA_ "SignalLongName" SG_ 1925 DTCIUnused7_785 "Diagnostic Trouble Code Information Extended 785 : Unused 7";
BA_ "VNSigAllNodes" SG_ 1925 DTCIUnused7_785 1;
BA_ "SignalType" SG_ 1925 DTCI_WrnIndRqdSt_785 "BLN";
BA_ "PacketOrder" SG_ 1925 DTCI_WrnIndRqdSt_785 12;
BA_ "SignalLongName" SG_ 1925 DTCI_WrnIndRqdSt_785 "Diagnostic Trouble Code Information Extended 785 : Warning Indicator Requested Status";
BA_ "VNSigAllNodes" SG_ 1925 DTCI_WrnIndRqdSt_785 1;
BA_ "SignalType" SG_ 1924 DTCI_HistStat_784 "BLN";
BA_ "PacketOrder" SG_ 1924 DTCI_HistStat_784 15;
BA_ "SignalLongName" SG_ 1924 DTCI_HistStat_784 "Diagnostic Trouble Code Information Extended 784 : History Status";
BA_ "VNSigAllNodes" SG_ 1924 DTCI_HistStat_784 1;
BA_ "SignalType" SG_ 1924 DTCI_TstFldCdClrdStat_784 "BLN";
BA_ "PacketOrder" SG_ 1924 DTCI_TstFldCdClrdStat_784 16;
BA_ "SignalLongName" SG_ 1924 DTCI_TstFldCdClrdStat_784 "Diagnostic Trouble Code Information Extended 784 : Test Failed Since Code Cleared Status";
BA_ "VNSigAllNodes" SG_ 1924 DTCI_TstFldCdClrdStat_784 1;
BA_ "SignalType" SG_ 1924 DTCI_TstFldPwrUpSt_784 "BLN";
BA_ "PacketOrder" SG_ 1924 DTCI_TstFldPwrUpSt_784 13;
BA_ "SignalLongName" SG_ 1924 DTCI_TstFldPwrUpSt_784 "Diagnostic Trouble Code Information Extended 784 : Test Failed Since Power Up Status";
BA_ "VNSigAllNodes" SG_ 1924 DTCI_TstFldPwrUpSt_784 1;
BA_ "SignalType" SG_ 1924 DTCI_TstNPsdCdClrdSt_784 "BLN";
BA_ "PacketOrder" SG_ 1924 DTCI_TstNPsdCdClrdSt_784 17;
BA_ "SignalLongName" SG_ 1924 DTCI_TstNPsdCdClrdSt_784 "Diagnostic Trouble Code Information Extended 784 : Test Not Passed Since Code Cleared Status";
BA_ "VNSigAllNodes" SG_ 1924 DTCI_TstNPsdCdClrdSt_784 1;
BA_ "SignalType" SG_ 1924 DTCI_TstNPsdPwrUpSt_784 "BLN";
BA_ "PacketOrder" SG_ 1924 DTCI_TstNPsdPwrUpSt_784 14;
BA_ "SignalLongName" SG_ 1924 DTCI_TstNPsdPwrUpSt_784 "Diagnostic Trouble Code Information Extended 784 : Test Not Passed Since Power Up Status";
BA_ "VNSigAllNodes" SG_ 1924 DTCI_TstNPsdPwrUpSt_784 1;
BA_ "SignalType" SG_ 1924 DTCIUnused1_784 "BLN";
BA_ "PacketOrder" SG_ 1924 DTCIUnused1_784 1;
BA_ "SignalLongName" SG_ 1924 DTCIUnused1_784 "Diagnostic Trouble Code Information Extended 784 : Unused 1";
BA_ "VNSigAllNodes" SG_ 1924 DTCIUnused1_784 1;
BA_ "SignalType" SG_ 1924 DTCIUnused2_784 "BLN";
BA_ "PacketOrder" SG_ 1924 DTCIUnused2_784 2;
BA_ "SignalLongName" SG_ 1924 DTCIUnused2_784 "Diagnostic Trouble Code Information Extended 784 : Unused 2";
BA_ "VNSigAllNodes" SG_ 1924 DTCIUnused2_784 1;
BA_ "SignalType" SG_ 1924 DTCIUnused3_784 "BLN";
BA_ "PacketOrder" SG_ 1924 DTCIUnused3_784 3;
BA_ "SignalLongName" SG_ 1924 DTCIUnused3_784 "Diagnostic Trouble Code Information Extended 784 : Unused 3";
BA_ "VNSigAllNodes" SG_ 1924 DTCIUnused3_784 1;
BA_ "SignalType" SG_ 1924 DTCIUnused4_784 "BLN";
BA_ "PacketOrder" SG_ 1924 DTCIUnused4_784 4;
BA_ "SignalLongName" SG_ 1924 DTCIUnused4_784 "Diagnostic Trouble Code Information Extended 784 : Unused 4";
BA_ "VNSigAllNodes" SG_ 1924 DTCIUnused4_784 1;
BA_ "SignalType" SG_ 1924 DTCIUnused5_784 "BLN";
BA_ "PacketOrder" SG_ 1924 DTCIUnused5_784 5;
BA_ "SignalLongName" SG_ 1924 DTCIUnused5_784 "Diagnostic Trouble Code Information Extended 784 : Unused 5";
BA_ "VNSigAllNodes" SG_ 1924 DTCIUnused5_784 1;
BA_ "SignalType" SG_ 1924 DTCIUnused6_784 "BLN";
BA_ "PacketOrder" SG_ 1924 DTCIUnused6_784 6;
BA_ "SignalLongName" SG_ 1924 DTCIUnused6_784 "Diagnostic Trouble Code Information Extended 784 : Unused 6";
BA_ "VNSigAllNodes" SG_ 1924 DTCIUnused6_784 1;
BA_ "SignalType" SG_ 1924 DTCIUnused7_784 "BLN";
BA_ "PacketOrder" SG_ 1924 DTCIUnused7_784 7;
BA_ "SignalLongName" SG_ 1924 DTCIUnused7_784 "Diagnostic Trouble Code Information Extended 784 : Unused 7";
BA_ "VNSigAllNodes" SG_ 1924 DTCIUnused7_784 1;
BA_ "SignalType" SG_ 1924 DTCI_WrnIndRqdSt_784 "BLN";
BA_ "PacketOrder" SG_ 1924 DTCI_WrnIndRqdSt_784 12;
BA_ "SignalLongName" SG_ 1924 DTCI_WrnIndRqdSt_784 "Diagnostic Trouble Code Information Extended 784 : Warning Indicator Requested Status";
BA_ "VNSigAllNodes" SG_ 1924 DTCI_WrnIndRqdSt_784 1;
BA_ "SignalType" SG_ 1924 DTCI_CodeSupported_784 "BLN";
BA_ "PacketOrder" SG_ 1924 DTCI_CodeSupported_784 19;
BA_ "SignalLongName" SG_ 1924 DTCI_CodeSupported_784 "Diagnostic Trouble Code Information Extended 784 : Code Supported";
BA_ "VNSigAllNodes" SG_ 1924 DTCI_CodeSupported_784 1;
BA_ "SignalType" SG_ 1924 DTCI_CurrentStatus_784 "BLN";
BA_ "PacketOrder" SG_ 1924 DTCI_CurrentStatus_784 18;
BA_ "SignalLongName" SG_ 1924 DTCI_CurrentStatus_784 "Diagnostic Trouble Code Information Extended 784 : Current Status";
BA_ "VNSigAllNodes" SG_ 1924 DTCI_CurrentStatus_784 1;
BA_ "SignalType" SG_ 1924 DTCI_DTCFailType_784 "UNM";
BA_ "PacketOrder" SG_ 1924 DTCI_DTCFailType_784 11;
BA_ "SignalLongName" SG_ 1924 DTCI_DTCFailType_784 "Diagnostic Trouble Code Information Extended 784 : Diagnostic Trouble Code Failure Type";
BA_ "VNSigAllNodes" SG_ 1924 DTCI_DTCFailType_784 1;
BA_ "SignalType" SG_ 1924 DTCI_DTCFaultType_784 "ENM";
BA_ "PacketOrder" SG_ 1924 DTCI_DTCFaultType_784 20;
BA_ "SignalLongName" SG_ 1924 DTCI_DTCFaultType_784 "Diagnostic Trouble Code Information Extended 784 : Diagnostic Trouble Code Fault Type";
BA_ "VNSigAllNodes" SG_ 1924 DTCI_DTCFaultType_784 1;
BA_ "SignalType" SG_ 1924 DTCI_DTCNumber_784 "UNM";
BA_ "PacketOrder" SG_ 1924 DTCI_DTCNumber_784 10;
BA_ "SignalLongName" SG_ 1924 DTCI_DTCNumber_784 "Diagnostic Trouble Code Information Extended 784 : Diagnostic Trouble Code Number";
BA_ "VNSigAllNodes" SG_ 1924 DTCI_DTCNumber_784 1;
BA_ "SignalType" SG_ 1924 DTCI_DTCSource_784 "UNM";
BA_ "PacketOrder" SG_ 1924 DTCI_DTCSource_784 9;
BA_ "SignalLongName" SG_ 1924 DTCI_DTCSource_784 "Diagnostic Trouble Code Information Extended 784 : Diagnostic Trouble Code Source";
BA_ "VNSigAllNodes" SG_ 1924 DTCI_DTCSource_784 1;
BA_ "SignalType" SG_ 1924 DTCI_DTCTriggered_784 "BLN";
BA_ "PacketOrder" SG_ 1924 DTCI_DTCTriggered_784 8;
BA_ "SignalLongName" SG_ 1924 DTCI_DTCTriggered_784 "Diagnostic Trouble Code Information Extended 784 : Diagnostic Trouble Code Triggered";
BA_ "VNSigAllNodes" SG_ 1924 DTCI_DTCTriggered_784 1;
BA_ "SignalType" SG_ 1923 DTCI_WrnIndRqdSt_783 "BLN";
BA_ "PacketOrder" SG_ 1923 DTCI_WrnIndRqdSt_783 12;
BA_ "SignalLongName" SG_ 1923 DTCI_WrnIndRqdSt_783 "Diagnostic Trouble Code Information Extended 783 : Warning Indicator Requested Status";
BA_ "VNSigAllNodes" SG_ 1923 DTCI_WrnIndRqdSt_783 1;
BA_ "SignalType" SG_ 1923 DTCI_TstNPsdPwrUpSt_783 "BLN";
BA_ "PacketOrder" SG_ 1923 DTCI_TstNPsdPwrUpSt_783 14;
BA_ "SignalLongName" SG_ 1923 DTCI_TstNPsdPwrUpSt_783 "Diagnostic Trouble Code Information Extended 783 : Test Not Passed Since Power Up Status";
BA_ "VNSigAllNodes" SG_ 1923 DTCI_TstNPsdPwrUpSt_783 1;
BA_ "SignalType" SG_ 1923 DTCI_TstNPsdCdClrdSt_783 "BLN";
BA_ "PacketOrder" SG_ 1923 DTCI_TstNPsdCdClrdSt_783 17;
BA_ "SignalLongName" SG_ 1923 DTCI_TstNPsdCdClrdSt_783 "Diagnostic Trouble Code Information Extended 783 : Test Not Passed Since Code Cleared Status";
BA_ "VNSigAllNodes" SG_ 1923 DTCI_TstNPsdCdClrdSt_783 1;
BA_ "SignalType" SG_ 1923 DTCI_TstFldPwrUpSt_783 "BLN";
BA_ "PacketOrder" SG_ 1923 DTCI_TstFldPwrUpSt_783 13;
BA_ "SignalLongName" SG_ 1923 DTCI_TstFldPwrUpSt_783 "Diagnostic Trouble Code Information Extended 783 : Test Failed Since Power Up Status";
BA_ "VNSigAllNodes" SG_ 1923 DTCI_TstFldPwrUpSt_783 1;
BA_ "SignalType" SG_ 1923 DTCI_TstFldCdClrdStat_783 "BLN";
BA_ "PacketOrder" SG_ 1923 DTCI_TstFldCdClrdStat_783 16;
BA_ "SignalLongName" SG_ 1923 DTCI_TstFldCdClrdStat_783 "Diagnostic Trouble Code Information Extended 783 : Test Failed Since Code Cleared Status";
BA_ "VNSigAllNodes" SG_ 1923 DTCI_TstFldCdClrdStat_783 1;
BA_ "SignalType" SG_ 1923 DTCI_HistStat_783 "BLN";
BA_ "PacketOrder" SG_ 1923 DTCI_HistStat_783 15;
BA_ "SignalLongName" SG_ 1923 DTCI_HistStat_783 "Diagnostic Trouble Code Information Extended 783 : History Status";
BA_ "VNSigAllNodes" SG_ 1923 DTCI_HistStat_783 1;
BA_ "SignalType" SG_ 1923 DTCI_DTCTriggered_783 "BLN";
BA_ "PacketOrder" SG_ 1923 DTCI_DTCTriggered_783 8;
BA_ "SignalLongName" SG_ 1923 DTCI_DTCTriggered_783 "Diagnostic Trouble Code Information Extended 783 : Diagnostic Trouble Code Triggered";
BA_ "VNSigAllNodes" SG_ 1923 DTCI_DTCTriggered_783 1;
BA_ "SignalType" SG_ 1923 DTCI_DTCSource_783 "UNM";
BA_ "PacketOrder" SG_ 1923 DTCI_DTCSource_783 9;
BA_ "SignalLongName" SG_ 1923 DTCI_DTCSource_783 "Diagnostic Trouble Code Information Extended 783 : Diagnostic Trouble Code Source";
BA_ "VNSigAllNodes" SG_ 1923 DTCI_DTCSource_783 1;
BA_ "SignalType" SG_ 1923 DTCI_DTCNumber_783 "UNM";
BA_ "PacketOrder" SG_ 1923 DTCI_DTCNumber_783 10;
BA_ "SignalLongName" SG_ 1923 DTCI_DTCNumber_783 "Diagnostic Trouble Code Information Extended 783 : Diagnostic Trouble Code Number";
BA_ "VNSigAllNodes" SG_ 1923 DTCI_DTCNumber_783 1;
BA_ "SignalType" SG_ 1923 DTCI_DTCFaultType_783 "ENM";
BA_ "PacketOrder" SG_ 1923 DTCI_DTCFaultType_783 20;
BA_ "SignalLongName" SG_ 1923 DTCI_DTCFaultType_783 "Diagnostic Trouble Code Information Extended 783 : Diagnostic Trouble Code Fault Type";
BA_ "VNSigAllNodes" SG_ 1923 DTCI_DTCFaultType_783 1;
BA_ "SignalType" SG_ 1923 DTCI_DTCFailType_783 "UNM";
BA_ "PacketOrder" SG_ 1923 DTCI_DTCFailType_783 11;
BA_ "SignalLongName" SG_ 1923 DTCI_DTCFailType_783 "Diagnostic Trouble Code Information Extended 783 : Diagnostic Trouble Code Failure Type";
BA_ "VNSigAllNodes" SG_ 1923 DTCI_DTCFailType_783 1;
BA_ "SignalType" SG_ 1923 DTCI_CurrentStatus_783 "BLN";
BA_ "PacketOrder" SG_ 1923 DTCI_CurrentStatus_783 18;
BA_ "SignalLongName" SG_ 1923 DTCI_CurrentStatus_783 "Diagnostic Trouble Code Information Extended 783 : Current Status";
BA_ "VNSigAllNodes" SG_ 1923 DTCI_CurrentStatus_783 1;
BA_ "SignalType" SG_ 1923 DTCI_CodeSupported_783 "BLN";
BA_ "PacketOrder" SG_ 1923 DTCI_CodeSupported_783 19;
BA_ "SignalLongName" SG_ 1923 DTCI_CodeSupported_783 "Diagnostic Trouble Code Information Extended 783 : Code Supported";
BA_ "VNSigAllNodes" SG_ 1923 DTCI_CodeSupported_783 1;
BA_ "SignalType" SG_ 1923 DTCIUnused7_783 "BLN";
BA_ "PacketOrder" SG_ 1923 DTCIUnused7_783 7;
BA_ "SignalLongName" SG_ 1923 DTCIUnused7_783 "Diagnostic Trouble Code Information Extended 783 : Unused 7";
BA_ "VNSigAllNodes" SG_ 1923 DTCIUnused7_783 1;
BA_ "SignalType" SG_ 1923 DTCIUnused6_783 "BLN";
BA_ "PacketOrder" SG_ 1923 DTCIUnused6_783 6;
BA_ "SignalLongName" SG_ 1923 DTCIUnused6_783 "Diagnostic Trouble Code Information Extended 783 : Unused 6";
BA_ "VNSigAllNodes" SG_ 1923 DTCIUnused6_783 1;
BA_ "SignalType" SG_ 1923 DTCIUnused5_783 "BLN";
BA_ "PacketOrder" SG_ 1923 DTCIUnused5_783 5;
BA_ "SignalLongName" SG_ 1923 DTCIUnused5_783 "Diagnostic Trouble Code Information Extended 783 : Unused 5";
BA_ "VNSigAllNodes" SG_ 1923 DTCIUnused5_783 1;
BA_ "SignalType" SG_ 1923 DTCIUnused4_783 "BLN";
BA_ "PacketOrder" SG_ 1923 DTCIUnused4_783 4;
BA_ "SignalLongName" SG_ 1923 DTCIUnused4_783 "Diagnostic Trouble Code Information Extended 783 : Unused 4";
BA_ "VNSigAllNodes" SG_ 1923 DTCIUnused4_783 1;
BA_ "SignalType" SG_ 1923 DTCIUnused3_783 "BLN";
BA_ "PacketOrder" SG_ 1923 DTCIUnused3_783 3;
BA_ "SignalLongName" SG_ 1923 DTCIUnused3_783 "Diagnostic Trouble Code Information Extended 783 : Unused 3";
BA_ "VNSigAllNodes" SG_ 1923 DTCIUnused3_783 1;
BA_ "SignalType" SG_ 1923 DTCIUnused2_783 "BLN";
BA_ "PacketOrder" SG_ 1923 DTCIUnused2_783 2;
BA_ "SignalLongName" SG_ 1923 DTCIUnused2_783 "Diagnostic Trouble Code Information Extended 783 : Unused 2";
BA_ "VNSigAllNodes" SG_ 1923 DTCIUnused2_783 1;
BA_ "SignalType" SG_ 1923 DTCIUnused1_783 "BLN";
BA_ "PacketOrder" SG_ 1923 DTCIUnused1_783 1;
BA_ "SignalLongName" SG_ 1923 DTCIUnused1_783 "Diagnostic Trouble Code Information Extended 783 : Unused 1";
BA_ "VNSigAllNodes" SG_ 1923 DTCIUnused1_783 1;
BA_ "VNSigSLHSSharedDiagnostic" SG_ 1363 DgnInf_HS553 1;
BA_ "SignalType" SG_ 1363 DgnInf_HS553 "UNM";
BA_ "SignalLongName" SG_ 1363 DgnInf_HS553 "Diagnostic Information HS553";
BA_ "VNSigAllNodes" SG_ 1363 DgnInf_HS553 1;
BA_ "VNSigSLHSSharedDiagnostic" SG_ 607 DgnInf 1;
BA_ "SignalType" SG_ 607 DgnInf "UNM";
BA_ "SignalLongName" SG_ 607 DgnInf "Diagnostic Information";
BA_ "VNSigAllNodes" SG_ 607 DgnInf 1;
BA_ "VNSigSLHSSharedDiagnostic" SG_ 1630 DgnInf 1;
BA_ "SignalType" SG_ 1630 DgnInf "UNM";
BA_ "SignalLongName" SG_ 1630 DgnInf "Diagnostic Information";
BA_ "VNSigAllNodes" SG_ 1630 DgnInf 1;
BA_ "VNSigSLHSSharedDiagnostic" SG_ 1629 DgnInf 1;
BA_ "SignalType" SG_ 1629 DgnInf "UNM";
BA_ "SignalLongName" SG_ 1629 DgnInf "Diagnostic Information";
BA_ "VNSigAllNodes" SG_ 1629 DgnInf 1;
BA_ "VNSigSLHSSharedDiagnostic" SG_ 606 DgnInf 1;
BA_ "SignalType" SG_ 606 DgnInf "UNM";
BA_ "SignalLongName" SG_ 606 DgnInf "Diagnostic Information";
BA_ "VNSigAllNodes" SG_ 606 DgnInf 1;
BA_ "VNSigSLHSSharedDiagnostic" SG_ 605 DgnInf 1;
BA_ "SignalType" SG_ 605 DgnInf "UNM";
BA_ "SignalLongName" SG_ 605 DgnInf "Diagnostic Information";
BA_ "VNSigAllNodes" SG_ 605 DgnInf 1;
BA_ "VNSigSLHSSharedDiagnostic" SG_ 604 DgnInf 1;
BA_ "SignalType" SG_ 604 DgnInf "UNM";
BA_ "SignalLongName" SG_ 604 DgnInf "Diagnostic Information";
BA_ "VNSigAllNodes" SG_ 604 DgnInf 1;
BA_ "VNSigSLHSSharedDiagnostic" SG_ 603 DgnInf 1;
BA_ "SignalType" SG_ 603 DgnInf "UNM";
BA_ "SignalLongName" SG_ 603 DgnInf "Diagnostic Information";
BA_ "VNSigAllNodes" SG_ 603 DgnInf 1;
BA_ "VNSigSLHSSharedDiagnostic" SG_ 602 DgnInf 1;
BA_ "SignalType" SG_ 602 DgnInf "UNM";
BA_ "SignalLongName" SG_ 602 DgnInf "Diagnostic Information";
BA_ "VNSigAllNodes" SG_ 602 DgnInf 1;
BA_ "VNSigSLHSSharedDiagnostic" SG_ 1631 DgnInf 1;
BA_ "SignalType" SG_ 1631 DgnInf "UNM";
BA_ "SignalLongName" SG_ 1631 DgnInf "Diagnostic Information";
BA_ "VNSigAllNodes" SG_ 1631 DgnInf 1;
BA_ "VNSigSLHSSharedDiagnostic" SG_ 1375 DgnInf_HS55F 1;
BA_ "SignalType" SG_ 1375 DgnInf_HS55F "UNM";
BA_ "SignalLongName" SG_ 1375 DgnInf_HS55F "Diagnostic Information HS55F";
BA_ "VNSigAllNodes" SG_ 1375 DgnInf_HS55F 1;
BA_ "VNSigSLHSSharedDiagnostic" SG_ 1374 DgnInf_HS55E 1;
BA_ "SignalType" SG_ 1374 DgnInf_HS55E "UNM";
BA_ "SignalLongName" SG_ 1374 DgnInf_HS55E "Diagnostic Information HS55E";
BA_ "VNSigAllNodes" SG_ 1374 DgnInf_HS55E 1;
BA_ "VNSigSLHSSharedDiagnostic" SG_ 1373 DgnInf_HS55D 1;
BA_ "SignalType" SG_ 1373 DgnInf_HS55D "UNM";
BA_ "SignalLongName" SG_ 1373 DgnInf_HS55D "Diagnostic Information HS55D";
BA_ "VNSigAllNodes" SG_ 1373 DgnInf_HS55D 1;
BA_ "VNSigSLHSSharedDiagnostic" SG_ 1372 DgnInf_HS55C 1;
BA_ "SignalType" SG_ 1372 DgnInf_HS55C "UNM";
BA_ "SignalLongName" SG_ 1372 DgnInf_HS55C "Diagnostic Information HS55C";
BA_ "VNSigAllNodes" SG_ 1372 DgnInf_HS55C 1;
BA_ "VNSigSLHSSharedDiagnostic" SG_ 1371 DgnInf_HS55B 1;
BA_ "SignalType" SG_ 1371 DgnInf_HS55B "UNM";
BA_ "SignalLongName" SG_ 1371 DgnInf_HS55B "Diagnostic Information HS55B";
BA_ "VNSigAllNodes" SG_ 1371 DgnInf_HS55B 1;
BA_ "VNSigSLHSSharedDiagnostic" SG_ 1370 DgnInf_HS55A 1;
BA_ "SignalType" SG_ 1370 DgnInf_HS55A "UNM";
BA_ "SignalLongName" SG_ 1370 DgnInf_HS55A "Diagnostic Information HS55A";
BA_ "VNSigAllNodes" SG_ 1370 DgnInf_HS55A 1;
BA_ "VNSigSLHSSharedDiagnostic" SG_ 1368 DgnInf_HS558 1;
BA_ "SignalType" SG_ 1368 DgnInf_HS558 "UNM";
BA_ "SignalLongName" SG_ 1368 DgnInf_HS558 "Diagnostic Information HS558";
BA_ "VNSigAllNodes" SG_ 1368 DgnInf_HS558 1;
BA_ "VNSigSLHSSharedDiagnostic" SG_ 1367 DgnInf_HS557 1;
BA_ "SignalType" SG_ 1367 DgnInf_HS557 "UNM";
BA_ "SignalLongName" SG_ 1367 DgnInf_HS557 "Diagnostic Information HS557";
BA_ "VNSigAllNodes" SG_ 1367 DgnInf_HS557 1;
BA_ "VNSigSLHSSharedDiagnostic" SG_ 1366 DgnInf_HS556 1;
BA_ "SignalType" SG_ 1366 DgnInf_HS556 "UNM";
BA_ "SignalLongName" SG_ 1366 DgnInf_HS556 "Diagnostic Information HS556";
BA_ "VNSigAllNodes" SG_ 1366 DgnInf_HS556 1;
BA_ "VNSigSLHSSharedDiagnostic" SG_ 1362 DgnInf_HS552 1;
BA_ "SignalType" SG_ 1362 DgnInf_HS552 "UNM";
BA_ "SignalLongName" SG_ 1362 DgnInf_HS552 "Diagnostic Information HS552";
BA_ "VNSigAllNodes" SG_ 1362 DgnInf_HS552 1;
BA_ "VNSigSLHSSharedDiagnostic" SG_ 1628 DgnInf 1;
BA_ "SignalType" SG_ 1628 DgnInf "UNM";
BA_ "SignalLongName" SG_ 1628 DgnInf "Diagnostic Information";
BA_ "VNSigAllNodes" SG_ 1628 DgnInf 1;
BA_ "VNSigSLHSSharedDiagnostic" SG_ 1627 DgnInf 1;
BA_ "SignalType" SG_ 1627 DgnInf "UNM";
BA_ "SignalLongName" SG_ 1627 DgnInf "Diagnostic Information";
BA_ "VNSigAllNodes" SG_ 1627 DgnInf 1;
BA_ "VNSigSLHSSharedDiagnostic" SG_ 1626 DgnInf 1;
BA_ "SignalType" SG_ 1626 DgnInf "UNM";
BA_ "SignalLongName" SG_ 1626 DgnInf "Diagnostic Information";
BA_ "VNSigAllNodes" SG_ 1626 DgnInf 1;
BA_ "VNSigSLHSSharedDiagnostic" SG_ 1624 DgnInf 1;
BA_ "SignalType" SG_ 1624 DgnInf "UNM";
BA_ "SignalLongName" SG_ 1624 DgnInf "Diagnostic Information";
BA_ "VNSigAllNodes" SG_ 1624 DgnInf 1;
BA_ "VNSigSLHSSharedDiagnostic" SG_ 1623 DgnInf 1;
BA_ "SignalType" SG_ 1623 DgnInf "UNM";
BA_ "SignalLongName" SG_ 1623 DgnInf "Diagnostic Information";
BA_ "VNSigAllNodes" SG_ 1623 DgnInf 1;
BA_ "VNSigSLHSSharedDiagnostic" SG_ 1622 DgnInf 1;
BA_ "SignalType" SG_ 1622 DgnInf "UNM";
BA_ "SignalLongName" SG_ 1622 DgnInf "Diagnostic Information";
BA_ "VNSigAllNodes" SG_ 1622 DgnInf 1;
BA_ "VNSigSLHSSharedDiagnostic" SG_ 1619 DgnInf 1;
BA_ "SignalType" SG_ 1619 DgnInf "UNM";
BA_ "SignalLongName" SG_ 1619 DgnInf "Diagnostic Information";
BA_ "VNSigAllNodes" SG_ 1619 DgnInf 1;
BA_ "VNSigSLHSSharedDiagnostic" SG_ 1618 DgnInf 1;
BA_ "SignalType" SG_ 1618 DgnInf "UNM";
BA_ "SignalLongName" SG_ 1618 DgnInf "Diagnostic Information";
BA_ "VNSigAllNodes" SG_ 1618 DgnInf 1;
BA_ "VNSigSLHSSharedDiagnostic" SG_ 1617 DgnInf 1;
BA_ "SignalType" SG_ 1617 DgnInf "UNM";
BA_ "SignalLongName" SG_ 1617 DgnInf "Diagnostic Information";
BA_ "VNSigAllNodes" SG_ 1617 DgnInf 1;
BA_ "VNSigSLHSSharedDiagnostic" SG_ 600 DgnInf 1;
BA_ "SignalType" SG_ 600 DgnInf "UNM";
BA_ "SignalLongName" SG_ 600 DgnInf "Diagnostic Information";
BA_ "VNSigAllNodes" SG_ 600 DgnInf 1;
BA_ "VNSigSLHSSharedDiagnostic" SG_ 599 DgnInf 1;
BA_ "SignalType" SG_ 599 DgnInf "UNM";
BA_ "SignalLongName" SG_ 599 DgnInf "Diagnostic Information";
BA_ "VNSigAllNodes" SG_ 599 DgnInf 1;
BA_ "VNSigSLHSSharedDiagnostic" SG_ 598 DgnInf 1;
BA_ "SignalType" SG_ 598 DgnInf "UNM";
BA_ "SignalLongName" SG_ 598 DgnInf "Diagnostic Information";
BA_ "VNSigAllNodes" SG_ 598 DgnInf 1;
BA_ "VNSigSLHSSharedDiagnostic" SG_ 595 DgnInf 1;
BA_ "SignalType" SG_ 595 DgnInf "UNM";
BA_ "SignalLongName" SG_ 595 DgnInf "Diagnostic Information";
BA_ "VNSigAllNodes" SG_ 595 DgnInf 1;
BA_ "VNSigSLHSSharedDiagnostic" SG_ 594 DgnInf 1;
BA_ "SignalType" SG_ 594 DgnInf "UNM";
BA_ "SignalLongName" SG_ 594 DgnInf "Diagnostic Information";
BA_ "VNSigAllNodes" SG_ 594 DgnInf 1;
BA_ "VNSigSLHSSharedDiagnostic" SG_ 593 DgnInf 1;
BA_ "SignalType" SG_ 593 DgnInf "UNM";
BA_ "SignalLongName" SG_ 593 DgnInf "Diagnostic Information";
BA_ "VNSigAllNodes" SG_ 593 DgnInf 1;
BA_ "SignalType" SG_ 1280 WhlRotStatTmstmpRes "UNM";
BA_ "SignalLongName" SG_ 1280 WhlRotStatTmstmpRes "Wheel Rotational Status Timestamp Resolution";
BA_ "VNSigAllNodes" SG_ 1280 WhlRotStatTmstmpRes 1;
BA_ "SignalType" SG_ 1280 WhlPlsPerRevNonDrvn "UNM";
BA_ "SignalLongName" SG_ 1280 WhlPlsPerRevNonDrvn "Wheel Pulses Per Revolution Non Driven";
BA_ "VNSigAllNodes" SG_ 1280 WhlPlsPerRevNonDrvn 1;
BA_ "SignalType" SG_ 1280 WhlPlsPerRevDrvn "UNM";
BA_ "SignalLongName" SG_ 1280 WhlPlsPerRevDrvn "Wheel Pulses Per Revolution Driven";
BA_ "VNSigAllNodes" SG_ 1280 WhlPlsPerRevDrvn 1;
BA_ "SignalType" SG_ 190 PTSnsdBrkPdlInfPVal "UNM";
BA_ "SignalLongName" SG_ 190 PTSnsdBrkPdlInfPVal "Powertrain Sensed Brake Pedal Information Protection Value";
BA_ "VNSigAllNodes" SG_ 190 PTSnsdBrkPdlInfPVal 1;
BA_ "SignalType" SG_ 190 TrnsAuxPmpAct "BLN";
BA_ "SignalLongName" SG_ 190 TrnsAuxPmpAct "Transmission Auxiliary Pump Active";
BA_ "VNSigAllNodes" SG_ 190 TrnsAuxPmpAct 1;
BA_ "SignalType" SG_ 190 AccPos "UNM";
BA_ "SignalLongName" SG_ 190 AccPos "Accelerator Effective Position";
BA_ "VNSigAllNodes" SG_ 190 AccPos 1;
BA_ "SignalType" SG_ 190 PTSnsdBrkPdlInfARC "UNM";
BA_ "SignalLongName" SG_ 190 PTSnsdBrkPdlInfARC "Powertrain Sensed Brake Pedal Information Alive Rolling Count";
BA_ "VNSigAllNodes" SG_ 190 PTSnsdBrkPdlInfARC 1;
BA_ "SignalType" SG_ 190 PSBPI_PTSnBrkPdlPsV "ENM";
BA_ "SignalLongName" SG_ 190 PSBPI_PTSnBrkPdlPsV "Powertrain Sensed Brake Pedal Information : Powertrain Sensed Brake Pedal Position Validity";
BA_ "VNSigAllNodes" SG_ 190 PSBPI_PTSnBrkPdlPsV 1;
BA_ "SignalType" SG_ 190 PSBPI_PTSnBrkPdlPs "UNM";
BA_ "SignalLongName" SG_ 190 PSBPI_PTSnBrkPdlPs "Powertrain Sensed Brake Pedal Information : Powertrain Sensed Brake Pedal Position";
BA_ "VNSigAllNodes" SG_ 190 PSBPI_PTSnBrkPdlPs 1;
BA_ "VNSigSLHSSharedDiagnostic" SG_ 1361 DgnInf_HS551 1;
BA_ "SignalType" SG_ 1361 DgnInf_HS551 "UNM";
BA_ "SignalLongName" SG_ 1361 DgnInf_HS551 "Diagnostic Information HS551";
BA_ "VNSigAllNodes" SG_ 1361 DgnInf_HS551 1;
BA_ "VNSigSLHSSharedDiagnostic" SG_ 1345 DgnInf_HS541 1;
BA_ "SignalType" SG_ 1345 DgnInf_HS541 "UNM";
BA_ "SignalLongName" SG_ 1345 DgnInf_HS541 "Diagnostic Information HS541";
BA_ "VNSigAllNodes" SG_ 1345 DgnInf_HS541 1;
BA_ "SignalType" SG_ 322 AFLGPSCstStReq "ENM";
BA_ "SignalLongName" SG_ 322 AFLGPSCstStReq "Adaptive Forward Lighting With GPS Customization Setting Request";
BA_ "VNSigAllNodes" SG_ 322 AFLGPSCstStReq 1;
BA_ "SignalType" SG_ 322 AFLCstStReq "ENM";
BA_ "SignalLongName" SG_ 322 AFLCstStReq "Adaptive Forward Lighting Customization Setting Request";
BA_ "VNSigAllNodes" SG_ 322 AFLCstStReq 1;
BA_ "SignalType" SG_ 322 LtRtHnTrCstStReq "ENM";
BA_ "SignalLongName" SG_ 322 LtRtHnTrCstStReq "Left Right Hand Traffic Customization Setting Request";
BA_ "VNSigAllNodes" SG_ 322 LtRtHnTrCstStReq 1;
BA_ "SignalType" SG_ 322 AdpHgBmAsSnCsStRq "ENM";
BA_ "SignalLongName" SG_ 322 AdpHgBmAsSnCsStRq "Adaptive High Beam Assist With Sensitivity Customization Setting Request";
BA_ "VNSigAllNodes" SG_ 322 AdpHgBmAsSnCsStRq 1;
BA_ "SignalType" SG_ 322 AdpHgBmAstCstStRq "ENM";
BA_ "SignalLongName" SG_ 322 AdpHgBmAstCstStRq "Adaptive High Beam Assist Customization Setting Request";
BA_ "VNSigAllNodes" SG_ 322 AdpHgBmAstCstStRq 1;
BA_ "SignalType" SG_ 322 LtRtHnTrGPSCstStRq "ENM";
BA_ "SignalLongName" SG_ 322 LtRtHnTrGPSCstStRq "Left Right Hand Traffic With GPS Customization Setting Request";
BA_ "VNSigAllNodes" SG_ 322 LtRtHnTrGPSCstStRq 1;
BA_ "SignalType" SG_ 322 AutHgBmAsSnCsStRq "ENM";
BA_ "SignalLongName" SG_ 322 AutHgBmAsSnCsStRq "Auto High Beam Assist With Sensitivity Customization Setting Request";
BA_ "VNSigAllNodes" SG_ 322 AutHgBmAsSnCsStRq 1;
BA_ "SignalType" SG_ 322 AutHgBmAstCstStRq "ENM";
BA_ "SignalLongName" SG_ 322 AutHgBmAstCstStRq "Auto High Beam Assist Customization Setting Request";
BA_ "VNSigAllNodes" SG_ 322 AutHgBmAstCstStRq 1;
BA_ "VNSigSLHSSharedDiagnostic" SG_ 1608 DgnInf 1;
BA_ "SignalType" SG_ 1608 DgnInf "UNM";
BA_ "SignalLongName" SG_ 1608 DgnInf "Diagnostic Information";
BA_ "VNSigAllNodes" SG_ 1608 DgnInf 1;
BA_ "SignalType" SG_ 534 DmpSysVehTopSpdLim "UNM";
BA_ "SignalLongName" SG_ 534 DmpSysVehTopSpdLim "Damping System Vehicle Top Speed Limit Value";
BA_ "GenSigStartValue" SG_ 534 DmpSysVehTopSpdLim 255;
BA_ "VNSigAllNodes" SG_ 534 DmpSysVehTopSpdLim 1;
BA_ "SignalType" SG_ 534 SrvSuspSysIO "BLN";
BA_ "SignalLongName" SG_ 534 SrvSuspSysIO "Service Suspension System Indication On";
BA_ "VNSigAllNodes" SG_ 534 SrvSuspSysIO 1;
BA_ "SignalType" SG_ 309 StBltTgtCSRq "ENM";
BA_ "SignalLongName" SG_ 309 StBltTgtCSRq "Seat Belt Tightening Customize Setting Request";
BA_ "VNSigAllNodes" SG_ 309 StBltTgtCSRq 1;
BA_ "SignalType" SG_ 309 ColPrSysCustReq "ENM";
BA_ "SignalLongName" SG_ 309 ColPrSysCustReq "Collision Preparation System Customization Setting Request";
BA_ "VNSigAllNodes" SG_ 309 ColPrSysCustReq 1;
BA_ "SignalType" SG_ 309 SecV "ENM";
BA_ "SignalLongName" SG_ 309 SecV "Seconds Validity";
BA_ "VNSigAllNodes" SG_ 309 SecV 1;
BA_ "SignalType" SG_ 309 Sec "UNM";
BA_ "SignalLongName" SG_ 309 Sec "Seconds";
BA_ "VNSigAllNodes" SG_ 309 Sec 1;
BA_ "SignalType" SG_ 309 CldrYr_154 "UNM";
BA_ "SignalLongName" SG_ 309 CldrYr_154 "Calendar Year";
BA_ "VNSigAllNodes" SG_ 309 CldrYr_154 1;
BA_ "SignalType" SG_ 309 CldrYr "UNM";
BA_ "SignalLongName" SG_ 309 CldrYr "Calendar Year";
BA_ "VNSigAllNodes" SG_ 309 CldrYr 1;
BA_ "SignalType" SG_ 309 CldrMth_154 "ENM";
BA_ "SignalLongName" SG_ 309 CldrMth_154 "Calendar Month";
BA_ "VNSigAllNodes" SG_ 309 CldrMth_154 1;
BA_ "SignalType" SG_ 309 CldrMth "ENM";
BA_ "SignalLongName" SG_ 309 CldrMth "Calendar Month";
BA_ "VNSigAllNodes" SG_ 309 CldrMth 1;
BA_ "SignalType" SG_ 309 CldrDay_154 "UNM";
BA_ "SignalLongName" SG_ 309 CldrDay_154 "Calendar Day";
BA_ "VNSigAllNodes" SG_ 309 CldrDay_154 1;
BA_ "SignalType" SG_ 309 CldrDay "UNM";
BA_ "SignalLongName" SG_ 309 CldrDay "Calendar Day";
BA_ "VNSigAllNodes" SG_ 309 CldrDay 1;
BA_ "SignalType" SG_ 309 AutoHiBmVDA "ENM";
BA_ "SignalLongName" SG_ 309 AutoHiBmVDA "Automatic High Beam Virtual Device Availability";
BA_ "GenSigStartValue" SG_ 309 AutoHiBmVDA 1;
BA_ "VNSigAllNodes" SG_ 309 AutoHiBmVDA 1;
BA_ "SignalType" SG_ 309 CtLghtDet "BLN";
BA_ "SignalLongName" SG_ 309 CtLghtDet "City Light Detected";
BA_ "VNSigAllNodes" SG_ 309 CtLghtDet 1;
BA_ "SignalType" SG_ 309 RrClosVDA "ENM";
BA_ "SignalLongName" SG_ 309 RrClosVDA "Rear Closure Virtual Device Availability";
BA_ "GenSigStartValue" SG_ 309 RrClosVDA 1;
BA_ "VNSigAllNodes" SG_ 309 RrClosVDA 1;
BA_ "SignalType" SG_ 309 TCSysDisSwAtv "BLN";
BA_ "SignalLongName" SG_ 309 TCSysDisSwAtv "Traction Control System Disable Switch Active";
BA_ "VNSigAllNodes" SG_ 309 TCSysDisSwAtv 1;
BA_ "SignalType" SG_ 309 VehMovState "ENM";
BA_ "SignalLongName" SG_ 309 VehMovState "Vehicle Movement State";
BA_ "VNSigAllNodes" SG_ 309 VehMovState 1;
BA_ "SignalType" SG_ 309 TCSysDisSwAtvV "ENM";
BA_ "SignalLongName" SG_ 309 TCSysDisSwAtvV "Traction Control System Disable Switch Active Validity";
BA_ "VNSigAllNodes" SG_ 309 TCSysDisSwAtvV 1;
BA_ "SignalType" SG_ 309 HillDesCtrlMdSwActV "ENM";
BA_ "SignalLongName" SG_ 309 HillDesCtrlMdSwActV "Hill Descent Control Mode Switch Active Validity";
BA_ "VNSigAllNodes" SG_ 309 HillDesCtrlMdSwActV 1;
BA_ "SignalType" SG_ 309 WSWshSwAtv "BLN";
BA_ "SignalLongName" SG_ 309 WSWshSwAtv "Windshield Washer Switch Active";
BA_ "VNSigAllNodes" SG_ 309 WSWshSwAtv 1;
BA_ "SignalType" SG_ 309 HillDesCtrlMdSwAct "BLN";
BA_ "SignalLongName" SG_ 309 HillDesCtrlMdSwAct "Hill Descent Control Mode Switch Active";
BA_ "VNSigAllNodes" SG_ 309 HillDesCtrlMdSwAct 1;
BA_ "SignalType" SG_ 309 RrClosAjarSwAct "BLN";
BA_ "SignalLongName" SG_ 309 RrClosAjarSwAct "Rear Closure Ajar Switch Active";
BA_ "VNSigAllNodes" SG_ 309 RrClosAjarSwAct 1;
BA_ "SignalType" SG_ 309 WSWprAct "BLN";
BA_ "SignalLongName" SG_ 309 WSWprAct "Windshield Wiper Active";
BA_ "VNSigAllNodes" SG_ 309 WSWprAct 1;
BA_REL_ "GenSigTimeoutMsg" BU_SG_REL_ EOCM_F_HS SG_ 452 AutBrkAccActPsStRC 452;
BA_REL_ "GenSigTimeoutMsg" BU_SG_REL_ ACC_HS SG_ 452 AutBrkAccActPsStRC 452;
BA_REL_ "GenSigSuprvResp" BU_SG_REL_ EBCM_OBD_HS SG_ 452 AutBrkAccActPsStRC 1;
BA_REL_ "GenSigTimeoutMsg" BU_SG_REL_ EBCM_OBD_HS SG_ 452 AutBrkAccActPsStRC 452;
BA_REL_ "GenSigTimeoutTime" BU_SG_REL_ EBCM_OBD_HS SG_ 452 AutBrkAccActPsStRC 250;
BA_REL_ "GenSigSuprvResp" BU_SG_REL_ EBCM_OBD_HS SG_ 452 AutBrkAccActPsStRC 1;
BA_REL_ "GenSigTimeoutMsg" BU_SG_REL_ EBCM_OBD_HS SG_ 452 AutBrkAccActPsStRC 452;
BA_REL_ "GenSigTimeoutTime" BU_SG_REL_ EBCM_OBD_HS SG_ 452 AutBrkAccActPsStRC 250;
BA_REL_ "GenSigSuprvResp" BU_SG_REL_ EBCM_OBD_HS SG_ 452 AutBrkAccActPsStRC 1;
BA_REL_ "GenSigTimeoutMsg" BU_SG_REL_ EBCM_OBD_HS SG_ 452 AutBrkAccActPsStRC 452;
BA_REL_ "GenSigTimeoutTime" BU_SG_REL_ EBCM_OBD_HS SG_ 452 AutBrkAccActPsStRC 250;
BA_REL_ "GenSigSuprvResp" BU_SG_REL_ EBCM_OBD_HS SG_ 452 AutBrkAccActPsStRC 1;
BA_REL_ "GenSigTimeoutMsg" BU_SG_REL_ EBCM_OBD_HS SG_ 452 AutBrkAccActPsStRC 452;
BA_REL_ "GenSigTimeoutTime" BU_SG_REL_ EBCM_OBD_HS SG_ 452 AutBrkAccActPsStRC 250;
BA_REL_ "GenSigSuprvResp" BU_SG_REL_ EBCM_OBD_HS SG_ 452 AutBrkAccActPsStRC 1;
BA_REL_ "GenSigTimeoutMsg" BU_SG_REL_ EBCM_OBD_HS SG_ 452 AutBrkAccActPsStRC 452;
BA_REL_ "GenSigTimeoutTime" BU_SG_REL_ EBCM_OBD_HS SG_ 452 AutBrkAccActPsStRC 250;
BA_REL_ "GenSigSuprvResp" BU_SG_REL_ EBCM_OBD_HS SG_ 452 AutBrkAccActPsStRC 1;
BA_REL_ "GenSigTimeoutMsg" BU_SG_REL_ EBCM_OBD_HS SG_ 452 AutBrkAccActPsStRC 452;
BA_REL_ "GenSigTimeoutTime" BU_SG_REL_ EBCM_OBD_HS SG_ 452 AutBrkAccActPsStRC 250;
BA_REL_ "GenSigSuprvResp" BU_SG_REL_ EBCM_HS SG_ 452 AutBrkAccActPsStRC 1;
BA_REL_ "GenSigTimeoutMsg" BU_SG_REL_ EBCM_HS SG_ 452 AutBrkAccActPsStRC 452;
BA_REL_ "GenSigTimeoutTime" BU_SG_REL_ EBCM_HS SG_ 452 AutBrkAccActPsStRC 250;
BA_REL_ "GenSigSuprvResp" BU_SG_REL_ EBCM_HS SG_ 452 AutBrkAccActPsStRC 1;
BA_REL_ "GenSigTimeoutMsg" BU_SG_REL_ EBCM_HS SG_ 452 AutBrkAccActPsStRC 452;
BA_REL_ "GenSigTimeoutTime" BU_SG_REL_ EBCM_HS SG_ 452 AutBrkAccActPsStRC 250;
BA_REL_ "GenSigSuprvResp" BU_SG_REL_ EBCM_HS SG_ 452 AutBrkAccActPsStRC 1;
BA_REL_ "GenSigTimeoutMsg" BU_SG_REL_ EBCM_HS SG_ 452 AutBrkAccActPsStRC 452;
BA_REL_ "GenSigTimeoutTime" BU_SG_REL_ EBCM_HS SG_ 452 AutBrkAccActPsStRC 250;
BA_REL_ "GenSigSuprvResp" BU_SG_REL_ EBCM_HS SG_ 452 AutBrkAccActPsStRC 1;
BA_REL_ "GenSigTimeoutMsg" BU_SG_REL_ EBCM_HS SG_ 452 AutBrkAccActPsStRC 452;
BA_REL_ "GenSigTimeoutTime" BU_SG_REL_ EBCM_HS SG_ 452 AutBrkAccActPsStRC 250;
BA_REL_ "GenSigSuprvResp" BU_SG_REL_ EBCM_HS SG_ 452 AutBrkAccActPsStRC 1;
BA_REL_ "GenSigTimeoutMsg" BU_SG_REL_ EBCM_HS SG_ 452 AutBrkAccActPsStRC 452;
BA_REL_ "GenSigTimeoutTime" BU_SG_REL_ EBCM_HS SG_ 452 AutBrkAccActPsStRC 250;
BA_REL_ "GenSigSuprvResp" BU_SG_REL_ EBCM_HS SG_ 452 AutBrkAccActPsStRC 1;
BA_REL_ "GenSigTimeoutMsg" BU_SG_REL_ EBCM_HS SG_ 452 AutBrkAccActPsStRC 452;
BA_REL_ "GenSigTimeoutTime" BU_SG_REL_ EBCM_HS SG_ 452 AutBrkAccActPsStRC 250;
BA_REL_ "GenSigTimeoutMsg" BU_SG_REL_ EOCM_F_HS SG_ 452 AutBrkAccActPsStPVal 452;
BA_REL_ "GenSigTimeoutMsg" BU_SG_REL_ ACC_HS SG_ 452 AutBrkAccActPsStPVal 452;
BA_REL_ "GenSigSuprvResp" BU_SG_REL_ EBCM_OBD_HS SG_ 452 AutBrkAccActPsStPVal 1;
BA_REL_ "GenSigTimeoutMsg" BU_SG_REL_ EBCM_OBD_HS SG_ 452 AutBrkAccActPsStPVal 452;
BA_REL_ "GenSigTimeoutTime" BU_SG_REL_ EBCM_OBD_HS SG_ 452 AutBrkAccActPsStPVal 250;
BA_REL_ "GenSigSuprvResp" BU_SG_REL_ EBCM_OBD_HS SG_ 452 AutBrkAccActPsStPVal 1;
BA_REL_ "GenSigTimeoutMsg" BU_SG_REL_ EBCM_OBD_HS SG_ 452 AutBrkAccActPsStPVal 452;
BA_REL_ "GenSigTimeoutTime" BU_SG_REL_ EBCM_OBD_HS SG_ 452 AutBrkAccActPsStPVal 250;
BA_REL_ "GenSigSuprvResp" BU_SG_REL_ EBCM_OBD_HS SG_ 452 AutBrkAccActPsStPVal 1;
BA_REL_ "GenSigTimeoutMsg" BU_SG_REL_ EBCM_OBD_HS SG_ 452 AutBrkAccActPsStPVal 452;
BA_REL_ "GenSigTimeoutTime" BU_SG_REL_ EBCM_OBD_HS SG_ 452 AutBrkAccActPsStPVal 250;
BA_REL_ "GenSigSuprvResp" BU_SG_REL_ EBCM_OBD_HS SG_ 452 AutBrkAccActPsStPVal 1;
BA_REL_ "GenSigTimeoutMsg" BU_SG_REL_ EBCM_OBD_HS SG_ 452 AutBrkAccActPsStPVal 452;
BA_REL_ "GenSigTimeoutTime" BU_SG_REL_ EBCM_OBD_HS SG_ 452 AutBrkAccActPsStPVal 250;
BA_REL_ "GenSigSuprvResp" BU_SG_REL_ EBCM_OBD_HS SG_ 452 AutBrkAccActPsStPVal 1;
BA_REL_ "GenSigTimeoutMsg" BU_SG_REL_ EBCM_OBD_HS SG_ 452 AutBrkAccActPsStPVal 452;
BA_REL_ "GenSigTimeoutTime" BU_SG_REL_ EBCM_OBD_HS SG_ 452 AutBrkAccActPsStPVal 250;
BA_REL_ "GenSigSuprvResp" BU_SG_REL_ EBCM_OBD_HS SG_ 452 AutBrkAccActPsStPVal 1;
BA_REL_ "GenSigTimeoutMsg" BU_SG_REL_ EBCM_OBD_HS SG_ 452 AutBrkAccActPsStPVal 452;
BA_REL_ "GenSigTimeoutTime" BU_SG_REL_ EBCM_OBD_HS SG_ 452 AutBrkAccActPsStPVal 250;
BA_REL_ "GenSigSuprvResp" BU_SG_REL_ EBCM_HS SG_ 452 AutBrkAccActPsStPVal 1;
BA_REL_ "GenSigTimeoutMsg" BU_SG_REL_ EBCM_HS SG_ 452 AutBrkAccActPsStPVal 452;
BA_REL_ "GenSigTimeoutTime" BU_SG_REL_ EBCM_HS SG_ 452 AutBrkAccActPsStPVal 250;
BA_REL_ "GenSigSuprvResp" BU_SG_REL_ EBCM_HS SG_ 452 AutBrkAccActPsStPVal 1;
BA_REL_ "GenSigTimeoutMsg" BU_SG_REL_ EBCM_HS SG_ 452 AutBrkAccActPsStPVal 452;
BA_REL_ "GenSigTimeoutTime" BU_SG_REL_ EBCM_HS SG_ 452 AutBrkAccActPsStPVal 250;
BA_REL_ "GenSigSuprvResp" BU_SG_REL_ EBCM_HS SG_ 452 AutBrkAccActPsStPVal 1;
BA_REL_ "GenSigTimeoutMsg" BU_SG_REL_ EBCM_HS SG_ 452 AutBrkAccActPsStPVal 452;
BA_REL_ "GenSigTimeoutTime" BU_SG_REL_ EBCM_HS SG_ 452 AutBrkAccActPsStPVal 250;
BA_REL_ "GenSigSuprvResp" BU_SG_REL_ EBCM_HS SG_ 452 AutBrkAccActPsStPVal 1;
BA_REL_ "GenSigTimeoutMsg" BU_SG_REL_ EBCM_HS SG_ 452 AutBrkAccActPsStPVal 452;
BA_REL_ "GenSigTimeoutTime" BU_SG_REL_ EBCM_HS SG_ 452 AutBrkAccActPsStPVal 250;
BA_REL_ "GenSigSuprvResp" BU_SG_REL_ EBCM_HS SG_ 452 AutBrkAccActPsStPVal 1;
BA_REL_ "GenSigTimeoutMsg" BU_SG_REL_ EBCM_HS SG_ 452 AutBrkAccActPsStPVal 452;
BA_REL_ "GenSigTimeoutTime" BU_SG_REL_ EBCM_HS SG_ 452 AutBrkAccActPsStPVal 250;
BA_REL_ "GenSigSuprvResp" BU_SG_REL_ EBCM_HS SG_ 452 AutBrkAccActPsStPVal 1;
BA_REL_ "GenSigTimeoutMsg" BU_SG_REL_ EBCM_HS SG_ 452 AutBrkAccActPsStPVal 452;
BA_REL_ "GenSigTimeoutTime" BU_SG_REL_ EBCM_HS SG_ 452 AutBrkAccActPsStPVal 250;
BA_REL_ "GenSigSuprvResp" BU_SG_REL_ EBCM_OBD_HS SG_ 452 ABAAPS_AccPos 1;
BA_REL_ "GenSigTimeoutMsg" BU_SG_REL_ EBCM_OBD_HS SG_ 452 ABAAPS_AccPos 452;
BA_REL_ "GenSigTimeoutTime" BU_SG_REL_ EBCM_OBD_HS SG_ 452 ABAAPS_AccPos 250;
BA_REL_ "GenSigSuprvResp" BU_SG_REL_ EBCM_OBD_HS SG_ 452 ABAAPS_AccPos 1;
BA_REL_ "GenSigTimeoutMsg" BU_SG_REL_ EBCM_OBD_HS SG_ 452 ABAAPS_AccPos 452;
BA_REL_ "GenSigTimeoutTime" BU_SG_REL_ EBCM_OBD_HS SG_ 452 ABAAPS_AccPos 250;
BA_REL_ "GenSigSuprvResp" BU_SG_REL_ EBCM_OBD_HS SG_ 452 ABAAPS_AccPos 1;
BA_REL_ "GenSigTimeoutMsg" BU_SG_REL_ EBCM_OBD_HS SG_ 452 ABAAPS_AccPos 452;
BA_REL_ "GenSigTimeoutTime" BU_SG_REL_ EBCM_OBD_HS SG_ 452 ABAAPS_AccPos 250;
BA_REL_ "GenSigSuprvResp" BU_SG_REL_ EBCM_OBD_HS SG_ 452 ABAAPS_AccPos 1;
BA_REL_ "GenSigTimeoutMsg" BU_SG_REL_ EBCM_OBD_HS SG_ 452 ABAAPS_AccPos 452;
BA_REL_ "GenSigTimeoutTime" BU_SG_REL_ EBCM_OBD_HS SG_ 452 ABAAPS_AccPos 250;
BA_REL_ "GenSigSuprvResp" BU_SG_REL_ EBCM_OBD_HS SG_ 452 ABAAPS_AccPos 1;
BA_REL_ "GenSigTimeoutMsg" BU_SG_REL_ EBCM_OBD_HS SG_ 452 ABAAPS_AccPos 452;
BA_REL_ "GenSigTimeoutTime" BU_SG_REL_ EBCM_OBD_HS SG_ 452 ABAAPS_AccPos 250;
BA_REL_ "GenSigSuprvResp" BU_SG_REL_ EBCM_OBD_HS SG_ 452 ABAAPS_AccPos 1;
BA_REL_ "GenSigTimeoutMsg" BU_SG_REL_ EBCM_OBD_HS SG_ 452 ABAAPS_AccPos 452;
BA_REL_ "GenSigTimeoutTime" BU_SG_REL_ EBCM_OBD_HS SG_ 452 ABAAPS_AccPos 250;
BA_REL_ "GenSigSuprvResp" BU_SG_REL_ EBCM_HS SG_ 452 ABAAPS_AccPos 1;
BA_REL_ "GenSigTimeoutMsg" BU_SG_REL_ EBCM_HS SG_ 452 ABAAPS_AccPos 452;
BA_REL_ "GenSigTimeoutTime" BU_SG_REL_ EBCM_HS SG_ 452 ABAAPS_AccPos 250;
BA_REL_ "GenSigSuprvResp" BU_SG_REL_ EBCM_HS SG_ 452 ABAAPS_AccPos 1;
BA_REL_ "GenSigTimeoutMsg" BU_SG_REL_ EBCM_HS SG_ 452 ABAAPS_AccPos 452;
BA_REL_ "GenSigTimeoutTime" BU_SG_REL_ EBCM_HS SG_ 452 ABAAPS_AccPos 250;
BA_REL_ "GenSigSuprvResp" BU_SG_REL_ EBCM_HS SG_ 452 ABAAPS_AccPos 1;
BA_REL_ "GenSigTimeoutMsg" BU_SG_REL_ EBCM_HS SG_ 452 ABAAPS_AccPos 452;
BA_REL_ "GenSigTimeoutTime" BU_SG_REL_ EBCM_HS SG_ 452 ABAAPS_AccPos 250;
BA_REL_ "GenSigSuprvResp" BU_SG_REL_ EBCM_HS SG_ 452 ABAAPS_AccPos 1;
BA_REL_ "GenSigTimeoutMsg" BU_SG_REL_ EBCM_HS SG_ 452 ABAAPS_AccPos 452;
BA_REL_ "GenSigTimeoutTime" BU_SG_REL_ EBCM_HS SG_ 452 ABAAPS_AccPos 250;
BA_REL_ "GenSigSuprvResp" BU_SG_REL_ EBCM_HS SG_ 452 ABAAPS_AccPos 1;
BA_REL_ "GenSigTimeoutMsg" BU_SG_REL_ EBCM_HS SG_ 452 ABAAPS_AccPos 452;
BA_REL_ "GenSigTimeoutTime" BU_SG_REL_ EBCM_HS SG_ 452 ABAAPS_AccPos 250;
BA_REL_ "GenSigSuprvResp" BU_SG_REL_ EBCM_HS SG_ 452 ABAAPS_AccPos 1;
BA_REL_ "GenSigTimeoutMsg" BU_SG_REL_ EBCM_HS SG_ 452 ABAAPS_AccPos 452;
BA_REL_ "GenSigTimeoutTime" BU_SG_REL_ EBCM_HS SG_ 452 ABAAPS_AccPos 250;
BA_REL_ "GenSigSuprvResp" BU_SG_REL_ ACC_HS SG_ 452 ABAAPS_AccPos 1;
BA_REL_ "GenSigTimeoutMsg" BU_SG_REL_ ACC_HS SG_ 452 ABAAPS_AccPos 452;
BA_REL_ "GenSigTimeoutTime" BU_SG_REL_ ACC_HS SG_ 452 ABAAPS_AccPos 250;
BA_REL_ "GenSigSuprvResp" BU_SG_REL_ EBCM_OBD_HS SG_ 452 ABAAPS_AccPosV 1;
BA_REL_ "GenSigTimeoutMsg" BU_SG_REL_ EBCM_OBD_HS SG_ 452 ABAAPS_AccPosV 452;
BA_REL_ "GenSigTimeoutTime" BU_SG_REL_ EBCM_OBD_HS SG_ 452 ABAAPS_AccPosV 250;
BA_REL_ "GenSigSuprvResp" BU_SG_REL_ EBCM_OBD_HS SG_ 452 ABAAPS_AccPosV 1;
BA_REL_ "GenSigTimeoutMsg" BU_SG_REL_ EBCM_OBD_HS SG_ 452 ABAAPS_AccPosV 452;
BA_REL_ "GenSigTimeoutTime" BU_SG_REL_ EBCM_OBD_HS SG_ 452 ABAAPS_AccPosV 250;
BA_REL_ "GenSigSuprvResp" BU_SG_REL_ EBCM_OBD_HS SG_ 452 ABAAPS_AccPosV 1;
BA_REL_ "GenSigTimeoutMsg" BU_SG_REL_ EBCM_OBD_HS SG_ 452 ABAAPS_AccPosV 452;
BA_REL_ "GenSigTimeoutTime" BU_SG_REL_ EBCM_OBD_HS SG_ 452 ABAAPS_AccPosV 250;
BA_REL_ "GenSigSuprvResp" BU_SG_REL_ EBCM_OBD_HS SG_ 452 ABAAPS_AccPosV 1;
BA_REL_ "GenSigTimeoutMsg" BU_SG_REL_ EBCM_OBD_HS SG_ 452 ABAAPS_AccPosV 452;
BA_REL_ "GenSigTimeoutTime" BU_SG_REL_ EBCM_OBD_HS SG_ 452 ABAAPS_AccPosV 250;
BA_REL_ "GenSigSuprvResp" BU_SG_REL_ EBCM_OBD_HS SG_ 452 ABAAPS_AccPosV 1;
BA_REL_ "GenSigTimeoutMsg" BU_SG_REL_ EBCM_OBD_HS SG_ 452 ABAAPS_AccPosV 452;
BA_REL_ "GenSigTimeoutTime" BU_SG_REL_ EBCM_OBD_HS SG_ 452 ABAAPS_AccPosV 250;
BA_REL_ "GenSigSuprvResp" BU_SG_REL_ EBCM_OBD_HS SG_ 452 ABAAPS_AccPosV 1;
BA_REL_ "GenSigTimeoutMsg" BU_SG_REL_ EBCM_OBD_HS SG_ 452 ABAAPS_AccPosV 452;
BA_REL_ "GenSigTimeoutTime" BU_SG_REL_ EBCM_OBD_HS SG_ 452 ABAAPS_AccPosV 250;
BA_REL_ "GenSigSuprvResp" BU_SG_REL_ EBCM_HS SG_ 452 ABAAPS_AccPosV 1;
BA_REL_ "GenSigTimeoutMsg" BU_SG_REL_ EBCM_HS SG_ 452 ABAAPS_AccPosV 452;
BA_REL_ "GenSigTimeoutTime" BU_SG_REL_ EBCM_HS SG_ 452 ABAAPS_AccPosV 250;
BA_REL_ "GenSigSuprvResp" BU_SG_REL_ EBCM_HS SG_ 452 ABAAPS_AccPosV 1;
BA_REL_ "GenSigTimeoutMsg" BU_SG_REL_ EBCM_HS SG_ 452 ABAAPS_AccPosV 452;
BA_REL_ "GenSigTimeoutTime" BU_SG_REL_ EBCM_HS SG_ 452 ABAAPS_AccPosV 250;
BA_REL_ "GenSigSuprvResp" BU_SG_REL_ EBCM_HS SG_ 452 ABAAPS_AccPosV 1;
BA_REL_ "GenSigTimeoutMsg" BU_SG_REL_ EBCM_HS SG_ 452 ABAAPS_AccPosV 452;
BA_REL_ "GenSigTimeoutTime" BU_SG_REL_ EBCM_HS SG_ 452 ABAAPS_AccPosV 250;
BA_REL_ "GenSigSuprvResp" BU_SG_REL_ EBCM_HS SG_ 452 ABAAPS_AccPosV 1;
BA_REL_ "GenSigTimeoutMsg" BU_SG_REL_ EBCM_HS SG_ 452 ABAAPS_AccPosV 452;
BA_REL_ "GenSigTimeoutTime" BU_SG_REL_ EBCM_HS SG_ 452 ABAAPS_AccPosV 250;
BA_REL_ "GenSigSuprvResp" BU_SG_REL_ EBCM_HS SG_ 452 ABAAPS_AccPosV 1;
BA_REL_ "GenSigTimeoutMsg" BU_SG_REL_ EBCM_HS SG_ 452 ABAAPS_AccPosV 452;
BA_REL_ "GenSigTimeoutTime" BU_SG_REL_ EBCM_HS SG_ 452 ABAAPS_AccPosV 250;
BA_REL_ "GenSigSuprvResp" BU_SG_REL_ EBCM_HS SG_ 452 ABAAPS_AccPosV 1;
BA_REL_ "GenSigTimeoutMsg" BU_SG_REL_ EBCM_HS SG_ 452 ABAAPS_AccPosV 452;
BA_REL_ "GenSigTimeoutTime" BU_SG_REL_ EBCM_HS SG_ 452 ABAAPS_AccPosV 250;
BA_REL_ "GenSigSuprvResp" BU_SG_REL_ ACC_HS SG_ 452 ABAAPS_AccPosV 1;
BA_REL_ "GenSigTimeoutMsg" BU_SG_REL_ ACC_HS SG_ 452 ABAAPS_AccPosV 452;
BA_REL_ "GenSigTimeoutTime" BU_SG_REL_ ACC_HS SG_ 452 ABAAPS_AccPosV 250;
BA_REL_ "GenSigRxStartValue" BU_SG_REL_ ACC_HS SG_ 452 ACCATCS_LmtgStat "0";
BA_REL_ "GenSigSuprvResp" BU_SG_REL_ ACC_HS SG_ 452 ACCATCS_LmtgStat 1;
BA_REL_ "GenSigTimeoutMsg" BU_SG_REL_ ACC_HS SG_ 452 ACCATCS_LmtgStat 452;
BA_REL_ "GenSigTimeoutTime" BU_SG_REL_ ACC_HS SG_ 452 ACCATCS_LmtgStat 125;
BA_REL_ "GenSigRxStartValue" BU_SG_REL_ ACC_HS SG_ 452 ACCATCS_RqStat "0";
BA_REL_ "GenSigSuprvResp" BU_SG_REL_ ACC_HS SG_ 452 ACCATCS_RqStat 1;
BA_REL_ "GenSigTimeoutMsg" BU_SG_REL_ ACC_HS SG_ 452 ACCATCS_RqStat 452;
BA_REL_ "GenSigTimeoutTime" BU_SG_REL_ ACC_HS SG_ 452 ACCATCS_RqStat 125;
BA_REL_ "GenSigSuprvResp" BU_SG_REL_ EOCM_F_HS SG_ 452 RdLdNomAxlTrq 1;
BA_REL_ "GenSigTimeoutTime" BU_SG_REL_ EOCM_F_HS SG_ 452 RdLdNomAxlTrq 120;
BA_REL_ "GenSigSuprvResp" BU_SG_REL_ ACC_HS SG_ 452 RdLdNomAxlTrq 1;
BA_REL_ "GenSigTimeoutMsg" BU_SG_REL_ ACC_HS SG_ 452 RdLdNomAxlTrq 452;
BA_REL_ "GenSigTimeoutTime" BU_SG_REL_ ACC_HS SG_ 452 RdLdNomAxlTrq 125;
BA_REL_ "GenSigSuprvResp" BU_SG_REL_ PTO_HS SG_ 452 AccPdlOvrrdAtvProtVal 1;
BA_REL_ "GenSigTimeoutMsg" BU_SG_REL_ PTO_HS SG_ 452 AccPdlOvrrdAtvProtVal 452;
BA_REL_ "GenSigTimeoutTime" BU_SG_REL_ PTO_HS SG_ 452 AccPdlOvrrdAtvProtVal 250;
BA_REL_ "GenSigSuprvResp" BU_SG_REL_ EOCM_F_HS SG_ 452 AccPdlOvrrdAtvARC 1;
BA_REL_ "GenSigTimeoutTime" BU_SG_REL_ EOCM_F_HS SG_ 452 AccPdlOvrrdAtvARC 120;
BA_REL_ "GenSigSuprvResp" BU_SG_REL_ PTO_HS SG_ 452 AccPdlOvrrdAtvARC 1;
BA_REL_ "GenSigTimeoutMsg" BU_SG_REL_ PTO_HS SG_ 452 AccPdlOvrrdAtvARC 452;
BA_REL_ "GenSigTimeoutTime" BU_SG_REL_ PTO_HS SG_ 452 AccPdlOvrrdAtvARC 250;
BA_REL_ "GenSigRxStartValue" BU_SG_REL_ ACC_HS SG_ 452 AccPdlOvrrdAtv "0";
BA_REL_ "GenSigSuprvResp" BU_SG_REL_ ACC_HS SG_ 452 AccPdlOvrrdAtv 1;
BA_REL_ "GenSigTimeoutMsg" BU_SG_REL_ ACC_HS SG_ 452 AccPdlOvrrdAtv 452;
BA_REL_ "GenSigTimeoutTime" BU_SG_REL_ ACC_HS SG_ 452 AccPdlOvrrdAtv 125;
BA_REL_ "GenSigSuprvResp" BU_SG_REL_ PTO_HS SG_ 452 AccPdlOvrrdAtv 1;
BA_REL_ "GenSigTimeoutMsg" BU_SG_REL_ PTO_HS SG_ 452 AccPdlOvrrdAtv 452;
BA_REL_ "GenSigTimeoutTime" BU_SG_REL_ PTO_HS SG_ 452 AccPdlOvrrdAtv 250;
BA_REL_ "GenSigSuprvResp" BU_SG_REL_ EOCM_F_HS SG_ 452 CPSATCS_ReqStatus 1;
BA_REL_ "GenSigTimeoutTime" BU_SG_REL_ EOCM_F_HS SG_ 452 CPSATCS_ReqStatus 120;
BA_REL_ "GenSigSuprvResp" BU_SG_REL_ EOCM_F_HS SG_ 452 CPSATCS_LmtngStatus 1;
BA_REL_ "GenSigTimeoutTime" BU_SG_REL_ EOCM_F_HS SG_ 452 CPSATCS_LmtngStatus 120;
BA_REL_ "GenSigSuprvResp" BU_SG_REL_ EOCM_F_HS SG_ 452 RVBATCS_ReqStat 1;
BA_REL_ "GenSigTimeoutMsg" BU_SG_REL_ EOCM_F_HS SG_ 452 RVBATCS_ReqStat 452;
BA_REL_ "GenSigTimeoutTime" BU_SG_REL_ EOCM_F_HS SG_ 452 RVBATCS_ReqStat 120;
BA_REL_ "GenSigSuprvResp" BU_SG_REL_ EOCM_F_HS SG_ 452 RVBATCS_LmtngStat 1;
BA_REL_ "GenSigTimeoutMsg" BU_SG_REL_ EOCM_F_HS SG_ 452 RVBATCS_LmtngStat 452;
BA_REL_ "GenSigTimeoutTime" BU_SG_REL_ EOCM_F_HS SG_ 452 RVBATCS_LmtngStat 120;
BA_REL_ "GenSigSuprvResp" BU_SG_REL_ VES_HS SG_ 1280 WhlRotStatTmstmpRes 1;
BA_REL_ "GenSigTimeoutMsg" BU_SG_REL_ VES_HS SG_ 1280 WhlRotStatTmstmpRes 1280;
BA_REL_ "GenSigTimeoutTime" BU_SG_REL_ VES_HS SG_ 1280 WhlRotStatTmstmpRes 2500;
BA_REL_ "GenSigSuprvResp" BU_SG_REL_ EPS_HS SG_ 1280 WhlRotStatTmstmpRes 1;
BA_REL_ "GenSigTimeoutMsg" BU_SG_REL_ EPS_HS SG_ 1280 WhlRotStatTmstmpRes 1280;
BA_REL_ "GenSigTimeoutTime" BU_SG_REL_ EPS_HS SG_ 1280 WhlRotStatTmstmpRes 2500;
BA_REL_ "GenSigSuprvResp" BU_SG_REL_ EOCM_F_HS SG_ 1280 WhlRotStatTmstmpRes 1;
BA_REL_ "GenSigTimeoutTime" BU_SG_REL_ EOCM_F_HS SG_ 1280 WhlRotStatTmstmpRes 2500;
BA_REL_ "GenSigSuprvResp" BU_SG_REL_ TCCM_HS SG_ 1280 WhlPlsPerRevNonDrvn 1;
BA_REL_ "GenSigTimeoutMsg" BU_SG_REL_ TCCM_HS SG_ 1280 WhlPlsPerRevNonDrvn 1280;
BA_REL_ "GenSigTimeoutTime" BU_SG_REL_ TCCM_HS SG_ 1280 WhlPlsPerRevNonDrvn 2500;
BA_REL_ "GenSigSuprvResp" BU_SG_REL_ EOCM_F_HS SG_ 1280 WhlPlsPerRevNonDrvn 1;
BA_REL_ "GenSigTimeoutTime" BU_SG_REL_ EOCM_F_HS SG_ 1280 WhlPlsPerRevNonDrvn 2500;
BA_REL_ "GenSigRxStartValue" BU_SG_REL_ RDCM_HS SG_ 1280 WhlPlsPerRevNonDrvn "48 pulses ($30)";
BA_REL_ "GenSigSuprvResp" BU_SG_REL_ TCCM_HS SG_ 1280 WhlPlsPerRevDrvn 1;
BA_REL_ "GenSigTimeoutMsg" BU_SG_REL_ TCCM_HS SG_ 1280 WhlPlsPerRevDrvn 1280;
BA_REL_ "GenSigTimeoutTime" BU_SG_REL_ TCCM_HS SG_ 1280 WhlPlsPerRevDrvn 2500;
BA_REL_ "GenSigSuprvResp" BU_SG_REL_ EOCM_F_HS SG_ 1280 WhlPlsPerRevDrvn 1;
BA_REL_ "GenSigTimeoutTime" BU_SG_REL_ EOCM_F_HS SG_ 1280 WhlPlsPerRevDrvn 2500;
BA_REL_ "GenSigSuprvResp" BU_SG_REL_ RDCM_HS SG_ 1280 WhlPlsPerRevDrvn 1;
BA_REL_ "GenSigTimeoutMsg" BU_SG_REL_ RDCM_HS SG_ 1280 WhlPlsPerRevDrvn 1280;
BA_REL_ "GenSigTimeoutTime" BU_SG_REL_ RDCM_HS SG_ 1280 WhlPlsPerRevDrvn 2500;
BA_REL_ "GenSigRxStartValue" BU_SG_REL_ RDCM_HS SG_ 1280 WhlPlsPerRevDrvn "48 pulses ($30)";
BA_REL_ "GenSigSuprvResp" BU_SG_REL_ RDCM_HS SG_ 1280 WhlPlsPerRevDrvn 1;
BA_REL_ "GenSigTimeoutMsg" BU_SG_REL_ RDCM_HS SG_ 1280 WhlPlsPerRevDrvn 1280;
BA_REL_ "GenSigTimeoutTime" BU_SG_REL_ RDCM_HS SG_ 1280 WhlPlsPerRevDrvn 2500;
BA_REL_ "GenSigSuprvResp" BU_SG_REL_ ICCM_OBD_HS SG_ 190 PTSnsdBrkPdlInfPVal 1;
BA_REL_ "GenSigTimeoutMsg" BU_SG_REL_ ICCM_OBD_HS SG_ 190 PTSnsdBrkPdlInfPVal 190;
BA_REL_ "GenSigTimeoutTime" BU_SG_REL_ ICCM_OBD_HS SG_ 190 PTSnsdBrkPdlInfPVal 250;
BA_REL_ "GenSigSuprvResp" BU_SG_REL_ ICCM_HS SG_ 190 PTSnsdBrkPdlInfPVal 1;
BA_REL_ "GenSigTimeoutMsg" BU_SG_REL_ ICCM_HS SG_ 190 PTSnsdBrkPdlInfPVal 190;
BA_REL_ "GenSigTimeoutTime" BU_SG_REL_ ICCM_HS SG_ 190 PTSnsdBrkPdlInfPVal 250;
BA_REL_ "GenSigSuprvResp" BU_SG_REL_ TCM_HS SG_ 190 TrnsAuxPmpAct 1;
BA_REL_ "GenSigTimeoutMsg" BU_SG_REL_ TCM_HS SG_ 190 TrnsAuxPmpAct 190;
BA_REL_ "GenSigTimeoutTime" BU_SG_REL_ TCM_HS SG_ 190 TrnsAuxPmpAct 250;
BA_REL_ "GenSigSuprvResp" BU_SG_REL_ BCP_HS SG_ 190 AccPos 1;
BA_REL_ "GenSigTimeoutMsg" BU_SG_REL_ BCP_HS SG_ 190 AccPos 190;
BA_REL_ "GenSigTimeoutTime" BU_SG_REL_ BCP_HS SG_ 190 AccPos 250;
BA_REL_ "GenSigSuprvResp" BU_SG_REL_ FICM_HS SG_ 190 AccPos 1;
BA_REL_ "GenSigTimeoutMsg" BU_SG_REL_ FICM_HS SG_ 190 AccPos 190;
BA_REL_ "GenSigTimeoutTime" BU_SG_REL_ FICM_HS SG_ 190 AccPos 250;
BA_REL_ "GenSigSuprvResp" BU_SG_REL_ TCM_HS SG_ 190 AccPos 1;
BA_REL_ "GenSigTimeoutMsg" BU_SG_REL_ TCM_HS SG_ 190 AccPos 190;
BA_REL_ "GenSigTimeoutTime" BU_SG_REL_ TCM_HS SG_ 190 AccPos 250;
BA_REL_ "GenSigSuprvResp" BU_SG_REL_ TCCM_HS SG_ 190 AccPos 1;
BA_REL_ "GenSigTimeoutMsg" BU_SG_REL_ TCCM_HS SG_ 190 AccPos 190;
BA_REL_ "GenSigTimeoutTime" BU_SG_REL_ TCCM_HS SG_ 190 AccPos 250;
BA_REL_ "GenSigSuprvResp" BU_SG_REL_ ICCM_OBD_HS SG_ 190 PTSnsdBrkPdlInfARC 1;
BA_REL_ "GenSigTimeoutMsg" BU_SG_REL_ ICCM_OBD_HS SG_ 190 PTSnsdBrkPdlInfARC 190;
BA_REL_ "GenSigTimeoutTime" BU_SG_REL_ ICCM_OBD_HS SG_ 190 PTSnsdBrkPdlInfARC 250;
BA_REL_ "GenSigSuprvResp" BU_SG_REL_ ICCM_HS SG_ 190 PTSnsdBrkPdlInfARC 1;
BA_REL_ "GenSigTimeoutMsg" BU_SG_REL_ ICCM_HS SG_ 190 PTSnsdBrkPdlInfARC 190;
BA_REL_ "GenSigTimeoutTime" BU_SG_REL_ ICCM_HS SG_ 190 PTSnsdBrkPdlInfARC 250;
BA_REL_ "GenSigSuprvResp" BU_SG_REL_ ICCM_OBD_HS SG_ 190 PSBPI_PTSnBrkPdlPsV 1;
BA_REL_ "GenSigTimeoutMsg" BU_SG_REL_ ICCM_OBD_HS SG_ 190 PSBPI_PTSnBrkPdlPsV 190;
BA_REL_ "GenSigTimeoutTime" BU_SG_REL_ ICCM_OBD_HS SG_ 190 PSBPI_PTSnBrkPdlPsV 250;
BA_REL_ "GenSigSuprvResp" BU_SG_REL_ ICCM_HS SG_ 190 PSBPI_PTSnBrkPdlPsV 1;
BA_REL_ "GenSigTimeoutMsg" BU_SG_REL_ ICCM_HS SG_ 190 PSBPI_PTSnBrkPdlPsV 190;
BA_REL_ "GenSigTimeoutTime" BU_SG_REL_ ICCM_HS SG_ 190 PSBPI_PTSnBrkPdlPsV 250;
BA_REL_ "GenSigSuprvResp" BU_SG_REL_ ICCM_OBD_HS SG_ 190 PSBPI_PTSnBrkPdlPs 1;
BA_REL_ "GenSigTimeoutMsg" BU_SG_REL_ ICCM_OBD_HS SG_ 190 PSBPI_PTSnBrkPdlPs 190;
BA_REL_ "GenSigTimeoutTime" BU_SG_REL_ ICCM_OBD_HS SG_ 190 PSBPI_PTSnBrkPdlPs 250;
BA_REL_ "GenSigSuprvResp" BU_SG_REL_ ICCM_HS SG_ 190 PSBPI_PTSnBrkPdlPs 1;
BA_REL_ "GenSigTimeoutMsg" BU_SG_REL_ ICCM_HS SG_ 190 PSBPI_PTSnBrkPdlPs 190;
BA_REL_ "GenSigTimeoutTime" BU_SG_REL_ ICCM_HS SG_ 190 PSBPI_PTSnBrkPdlPs 250;
BA_REL_ "GenSigSuprvRespSubValue" BU_SG_REL_ BCM_HS SG_ 534 DmpSysVehTopSpdLim 255;
BA_REL_ "GenSigSuprvResp" BU_SG_REL_ BCM_HS SG_ 534 DmpSysVehTopSpdLim 2;
BA_REL_ "GenSigTimeoutMsg" BU_SG_REL_ BCM_HS SG_ 534 DmpSysVehTopSpdLim 534;
BA_REL_ "GenSigTimeoutTime" BU_SG_REL_ BCM_HS SG_ 534 DmpSysVehTopSpdLim 250;
BA_REL_ "GenSigSuprvResp" BU_SG_REL_ BCM_HS SG_ 534 SrvSuspSysIO 1;
BA_REL_ "GenSigTimeoutMsg" BU_SG_REL_ BCM_HS SG_ 534 SrvSuspSysIO 534;
BA_REL_ "GenSigTimeoutTime" BU_SG_REL_ BCM_HS SG_ 534 SrvSuspSysIO 250;
BA_REL_ "GenSigSuprvResp" BU_SG_REL_ EBCM_OBD_HS SG_ 309 StBltTgtCSRq 1;
BA_REL_ "GenSigTimeoutMsg" BU_SG_REL_ EBCM_OBD_HS SG_ 309 StBltTgtCSRq 309;
BA_REL_ "GenSigTimeoutTime" BU_SG_REL_ EBCM_OBD_HS SG_ 309 StBltTgtCSRq 250;
BA_REL_ "GenSigSuprvResp" BU_SG_REL_ EBCM_HS SG_ 309 StBltTgtCSRq 1;
BA_REL_ "GenSigTimeoutMsg" BU_SG_REL_ EBCM_HS SG_ 309 StBltTgtCSRq 309;
BA_REL_ "GenSigTimeoutTime" BU_SG_REL_ EBCM_HS SG_ 309 StBltTgtCSRq 250;
BA_REL_ "GenSigSuprvResp" BU_SG_REL_ EOCM_F_HS SG_ 309 ColPrSysCustReq 1;
BA_REL_ "GenSigTimeoutMsg" BU_SG_REL_ EOCM_F_HS SG_ 309 ColPrSysCustReq 309;
BA_REL_ "GenSigTimeoutTime" BU_SG_REL_ EOCM_F_HS SG_ 309 ColPrSysCustReq 250;
BA_REL_ "GenSigVDAFailComment" BU_SG_REL_ AHL_AFL_HS SG_ 309 CtLghtDet "Automatic High Beam Virtual Device Availability";
BA_REL_ "GenSigVDAFailResp" BU_SG_REL_ AHL_AFL_HS SG_ 309 CtLghtDet 1;
BA_REL_ "GenSigSuprvResp" BU_SG_REL_ AHL_AFL_HS SG_ 309 CtLghtDet 1;
BA_REL_ "GenSigTimeoutMsg" BU_SG_REL_ AHL_AFL_HS SG_ 309 CtLghtDet 309;
BA_REL_ "GenSigTimeoutTime" BU_SG_REL_ AHL_AFL_HS SG_ 309 CtLghtDet 250;
BA_REL_ "GenSigSuprvResp" BU_SG_REL_ HMIM_HS SG_ 309 VehMovState 1;
BA_REL_ "GenSigTimeoutMsg" BU_SG_REL_ HMIM_HS SG_ 309 VehMovState 309;
BA_REL_ "GenSigTimeoutTime" BU_SG_REL_ HMIM_HS SG_ 309 VehMovState 250;
BA_REL_ "GenSigSuprvResp" BU_SG_REL_ AHL_AFL_HS SG_ 309 VehMovState 1;
BA_REL_ "GenSigTimeoutMsg" BU_SG_REL_ AHL_AFL_HS SG_ 309 VehMovState 309;
BA_REL_ "GenSigTimeoutTime" BU_SG_REL_ AHL_AFL_HS SG_ 309 VehMovState 250;
BA_REL_ "GenSigSuprvResp" BU_SG_REL_ EOCM_F_HS SG_ 309 WSWshSwAtv 1;
BA_REL_ "GenSigTimeoutMsg" BU_SG_REL_ EOCM_F_HS SG_ 309 WSWshSwAtv 309;
BA_REL_ "GenSigTimeoutTime" BU_SG_REL_ EOCM_F_HS SG_ 309 WSWshSwAtv 250;
BA_REL_ "GenSigSuprvResp" BU_SG_REL_ ACC_HS SG_ 309 WSWshSwAtv 1;
BA_REL_ "GenSigTimeoutMsg" BU_SG_REL_ ACC_HS SG_ 309 WSWshSwAtv 309;
BA_REL_ "GenSigTimeoutTime" BU_SG_REL_ ACC_HS SG_ 309 WSWshSwAtv 250;
BA_REL_ "GenSigSuprvResp" BU_SG_REL_ EOCM_F_HS SG_ 309 WSWprAct 2;
BA_REL_ "GenSigTimeoutMsg" BU_SG_REL_ EOCM_F_HS SG_ 309 WSWprAct 309;
BA_REL_ "GenSigTimeoutTime" BU_SG_REL_ EOCM_F_HS SG_ 309 WSWprAct 250;
BA_REL_ "GenSigSuprvResp" BU_SG_REL_ ACC_HS SG_ 309 WSWprAct 1;
BA_REL_ "GenSigTimeoutMsg" BU_SG_REL_ ACC_HS SG_ 309 WSWprAct 309;
BA_REL_ "GenSigTimeoutTime" BU_SG_REL_ ACC_HS SG_ 309 WSWprAct 250;
VAL_ 452 FSpRgACCSwADd 1 "true" 0 "false" ;
VAL_ 452 ABAAPS_AccPosV 1 "Invalid" 0 "Valid" ;
VAL_ 452 ACCATCS_LmtgStat 3 "Request Rate Limited" 2 "Request Value Limited Maximum" 1 "Request Value Limited Minimum" 0 "Request Not Limited" ;
VAL_ 452 ACCATCS_RqStat 4 "Request Suspended Till Driver Input" 3 "Request Denied" 2 "Lost Arbitration" 1 "Request Honored" 0 "No Request" ;
VAL_ 452 AccPdlOvrrdAtv 1 "true" 0 "false" ;
VAL_ 452 CPSATCS_ReqStatus 0 "No Request" 1 "Request Honored" 2 "Lost Arbitration" 3 "Serial Data Failure Temporary" 4 "Serial Data Failure Permanent" 5 "Control System Failure Temporary" 6 "Control System Failure Permanent" ;
VAL_ 452 CPSATCS_LmtngStatus 0 "Request Not Limited" 1 "Request Value Limited to Minimum" 2 "Request Value Limited to Maximum" 3 "Request Rate Limited" ;
VAL_ 452 RVBATCS_ReqStat 0 "No Request" 1 "Request Honored" 2 "Lost Arbitration" 3 "Serial Data Failure Temporary" 4 "Serial Data Failure Permanent" 5 "Control System Failure Temporary" 6 "Control System Failure Permanent" ;
VAL_ 452 RVBATCS_LmtngStat 0 "Request Not Limited" 1 "Request Value Limited to Minimum" 2 "Request Value Limited to Maximum" 3 "Request Rate Limited" ;
VAL_ 1905 DTCI_DTCFaultType_771 3 "Type C" 2 "Type B" 1 "Type A" 0 "Not Supported" ;
VAL_ 1905 DTCI_CodeSupported_771 1 "true" 0 "false" ;
VAL_ 1905 DTCI_CurrentStatus_771 1 "true" 0 "false" ;
VAL_ 1905 DTCI_TstNPsdCdClrdSt_771 1 "true" 0 "false" ;
VAL_ 1905 DTCI_TstFldCdClrdStat_771 1 "true" 0 "false" ;
VAL_ 1905 DTCI_HistStat_771 1 "true" 0 "false" ;
VAL_ 1905 DTCI_TstNPsdPwrUpSt_771 1 "true" 0 "false" ;
VAL_ 1905 DTCI_TstFldPwrUpSt_771 1 "true" 0 "false" ;
VAL_ 1905 DTCI_WrnIndRqdSt_771 1 "true" 0 "false" ;
VAL_ 1905 DTCI_DTCTriggered_771 1 "true" 0 "false" ;
VAL_ 1905 DTCIUnused7_771 1 "true" 0 "false" ;
VAL_ 1905 DTCIUnused6_771 1 "true" 0 "false" ;
VAL_ 1905 DTCIUnused5_771 1 "true" 0 "false" ;
VAL_ 1905 DTCIUnused4_771 1 "true" 0 "false" ;
VAL_ 1905 DTCIUnused3_771 1 "true" 0 "false" ;
VAL_ 1905 DTCIUnused2_771 1 "true" 0 "false" ;
VAL_ 1905 DTCIUnused1_771 1 "true" 0 "false" ;
VAL_ 1935 DTCI_DTCTriggered_78F 1 "true" 0 "false" ;
VAL_ 1935 DTCIUnused1_78F 1 "true" 0 "false" ;
VAL_ 1935 DTCIUnused2_78F 1 "true" 0 "false" ;
VAL_ 1935 DTCIUnused3_78F 1 "true" 0 "false" ;
VAL_ 1935 DTCIUnused4_78F 1 "true" 0 "false" ;
VAL_ 1935 DTCIUnused5_78F 1 "true" 0 "false" ;
VAL_ 1935 DTCIUnused6_78F 1 "true" 0 "false" ;
VAL_ 1935 DTCIUnused7_78F 1 "true" 0 "false" ;
VAL_ 1935 DTCI_CodeSupported_78F 1 "true" 0 "false" ;
VAL_ 1935 DTCI_CurrentStatus_78F 1 "true" 0 "false" ;
VAL_ 1935 DTCI_DTCFaultType_78F 3 "Type C" 2 "Type B" 1 "Type A" 0 "Not Supported" ;
VAL_ 1935 DTCI_TstFldCdClrdStat_78F 1 "true" 0 "false" ;
VAL_ 1935 DTCI_TstNPsdCdClrdSt_78F 1 "true" 0 "false" ;
VAL_ 1935 DTCI_HistStat_78F 1 "true" 0 "false" ;
VAL_ 1935 DTCI_TstNPsdPwrUpSt_78F 1 "true" 0 "false" ;
VAL_ 1935 DTCI_TstFldPwrUpSt_78F 1 "true" 0 "false" ;
VAL_ 1935 DTCI_WrnIndRqdSt_78F 1 "true" 0 "false" ;
VAL_ 1934 DTCI_CodeSupported_78E 1 "true" 0 "false" ;
VAL_ 1934 DTCI_CurrentStatus_78E 1 "true" 0 "false" ;
VAL_ 1934 DTCI_DTCFaultType_78E 3 "Type C" 2 "Type B" 1 "Type A" 0 "Not Supported" ;
VAL_ 1934 DTCI_DTCTriggered_78E 1 "true" 0 "false" ;
VAL_ 1934 DTCI_HistStat_78E 1 "true" 0 "false" ;
VAL_ 1934 DTCI_TstFldCdClrdStat_78E 1 "true" 0 "false" ;
VAL_ 1934 DTCI_TstFldPwrUpSt_78E 1 "true" 0 "false" ;
VAL_ 1934 DTCI_TstNPsdCdClrdSt_78E 1 "true" 0 "false" ;
VAL_ 1934 DTCI_TstNPsdPwrUpSt_78E 1 "true" 0 "false" ;
VAL_ 1934 DTCIUnused1_78E 1 "true" 0 "false" ;
VAL_ 1934 DTCIUnused2_78E 1 "true" 0 "false" ;
VAL_ 1934 DTCIUnused3_78E 1 "true" 0 "false" ;
VAL_ 1934 DTCIUnused4_78E 1 "true" 0 "false" ;
VAL_ 1934 DTCIUnused5_78E 1 "true" 0 "false" ;
VAL_ 1934 DTCIUnused6_78E 1 "true" 0 "false" ;
VAL_ 1934 DTCIUnused7_78E 1 "true" 0 "false" ;
VAL_ 1934 DTCI_WrnIndRqdSt_78E 1 "true" 0 "false" ;
VAL_ 1933 DTCI_CodeSupported_78D 1 "true" 0 "false" ;
VAL_ 1933 DTCI_CurrentStatus_78D 1 "true" 0 "false" ;
VAL_ 1933 DTCI_DTCFaultType_78D 3 "Type C" 2 "Type B" 1 "Type A" 0 "Not Supported" ;
VAL_ 1933 DTCI_DTCTriggered_78D 1 "true" 0 "false" ;
VAL_ 1933 DTCI_HistStat_78D 1 "true" 0 "false" ;
VAL_ 1933 DTCI_TstFldCdClrdStat_78D 1 "true" 0 "false" ;
VAL_ 1933 DTCI_TstFldPwrUpSt_78D 1 "true" 0 "false" ;
VAL_ 1933 DTCI_TstNPsdCdClrdSt_78D 1 "true" 0 "false" ;
VAL_ 1933 DTCI_TstNPsdPwrUpSt_78D 1 "true" 0 "false" ;
VAL_ 1933 DTCIUnused1_78D 1 "true" 0 "false" ;
VAL_ 1933 DTCIUnused2_78D 1 "true" 0 "false" ;
VAL_ 1933 DTCIUnused3_78D 1 "true" 0 "false" ;
VAL_ 1933 DTCIUnused4_78D 1 "true" 0 "false" ;
VAL_ 1933 DTCIUnused5_78D 1 "true" 0 "false" ;
VAL_ 1933 DTCIUnused6_78D 1 "true" 0 "false" ;
VAL_ 1933 DTCIUnused7_78D 1 "true" 0 "false" ;
VAL_ 1933 DTCI_WrnIndRqdSt_78D 1 "true" 0 "false" ;
VAL_ 1932 DTCI_CodeSupported_78C 1 "true" 0 "false" ;
VAL_ 1932 DTCI_CurrentStatus_78C 1 "true" 0 "false" ;
VAL_ 1932 DTCI_DTCFaultType_78C 3 "Type C" 2 "Type B" 1 "Type A" 0 "Not Supported" ;
VAL_ 1932 DTCI_DTCTriggered_78C 1 "true" 0 "false" ;
VAL_ 1932 DTCI_HistStat_78C 1 "true" 0 "false" ;
VAL_ 1932 DTCI_TstFldCdClrdStat_78C 1 "true" 0 "false" ;
VAL_ 1932 DTCI_TstFldPwrUpSt_78C 1 "true" 0 "false" ;
VAL_ 1932 DTCI_TstNPsdCdClrdSt_78C 1 "true" 0 "false" ;
VAL_ 1932 DTCI_TstNPsdPwrUpSt_78C 1 "true" 0 "false" ;
VAL_ 1932 DTCIUnused1_78C 1 "true" 0 "false" ;
VAL_ 1932 DTCIUnused2_78C 1 "true" 0 "false" ;
VAL_ 1932 DTCIUnused3_78C 1 "true" 0 "false" ;
VAL_ 1932 DTCIUnused4_78C 1 "true" 0 "false" ;
VAL_ 1932 DTCIUnused5_78C 1 "true" 0 "false" ;
VAL_ 1932 DTCIUnused6_78C 1 "true" 0 "false" ;
VAL_ 1932 DTCIUnused7_78C 1 "true" 0 "false" ;
VAL_ 1932 DTCI_WrnIndRqdSt_78C 1 "true" 0 "false" ;
VAL_ 1931 DTCI_CodeSupported_78B 1 "true" 0 "false" ;
VAL_ 1931 DTCI_CurrentStatus_78B 1 "true" 0 "false" ;
VAL_ 1931 DTCI_DTCFaultType_78B 3 "Type C" 2 "Type B" 1 "Type A" 0 "Not Supported" ;
VAL_ 1931 DTCI_DTCTriggered_78B 1 "true" 0 "false" ;
VAL_ 1931 DTCI_HistStat_78B 1 "true" 0 "false" ;
VAL_ 1931 DTCI_TstFldCdClrdStat_78B 1 "true" 0 "false" ;
VAL_ 1931 DTCI_TstFldPwrUpSt_78B 1 "true" 0 "false" ;
VAL_ 1931 DTCI_TstNPsdCdClrdSt_78B 1 "true" 0 "false" ;
VAL_ 1931 DTCI_TstNPsdPwrUpSt_78B 1 "true" 0 "false" ;
VAL_ 1931 DTCIUnused1_78B 1 "true" 0 "false" ;
VAL_ 1931 DTCIUnused2_78B 1 "true" 0 "false" ;
VAL_ 1931 DTCIUnused3_78B 1 "true" 0 "false" ;
VAL_ 1931 DTCIUnused4_78B 1 "true" 0 "false" ;
VAL_ 1931 DTCIUnused5_78B 1 "true" 0 "false" ;
VAL_ 1931 DTCIUnused6_78B 1 "true" 0 "false" ;
VAL_ 1931 DTCIUnused7_78B 1 "true" 0 "false" ;
VAL_ 1931 DTCI_WrnIndRqdSt_78B 1 "true" 0 "false" ;
VAL_ 1930 DTCI_CodeSupported_78A 1 "true" 0 "false" ;
VAL_ 1930 DTCI_CurrentStatus_78A 1 "true" 0 "false" ;
VAL_ 1930 DTCI_DTCFaultType_78A 3 "Type C" 2 "Type B" 1 "Type A" 0 "Not Supported" ;
VAL_ 1930 DTCI_DTCTriggered_78A 1 "true" 0 "false" ;
VAL_ 1930 DTCI_HistStat_78A 1 "true" 0 "false" ;
VAL_ 1930 DTCI_TstFldCdClrdStat_78A 1 "true" 0 "false" ;
VAL_ 1930 DTCI_TstFldPwrUpSt_78A 1 "true" 0 "false" ;
VAL_ 1930 DTCI_TstNPsdCdClrdSt_78A 1 "true" 0 "false" ;
VAL_ 1930 DTCI_TstNPsdPwrUpSt_78A 1 "true" 0 "false" ;
VAL_ 1930 DTCIUnused1_78A 1 "true" 0 "false" ;
VAL_ 1930 DTCIUnused2_78A 1 "true" 0 "false" ;
VAL_ 1930 DTCIUnused3_78A 1 "true" 0 "false" ;
VAL_ 1930 DTCIUnused4_78A 1 "true" 0 "false" ;
VAL_ 1930 DTCIUnused5_78A 1 "true" 0 "false" ;
VAL_ 1930 DTCIUnused6_78A 1 "true" 0 "false" ;
VAL_ 1930 DTCIUnused7_78A 1 "true" 0 "false" ;
VAL_ 1930 DTCI_WrnIndRqdSt_78A 1 "true" 0 "false" ;
VAL_ 1929 DTCI_CodeSupported_789 1 "true" 0 "false" ;
VAL_ 1929 DTCI_CurrentStatus_789 1 "true" 0 "false" ;
VAL_ 1929 DTCI_DTCFaultType_789 3 "Type C" 2 "Type B" 1 "Type A" 0 "Not Supported" ;
VAL_ 1929 DTCI_DTCTriggered_789 1 "true" 0 "false" ;
VAL_ 1929 DTCI_HistStat_789 1 "true" 0 "false" ;
VAL_ 1929 DTCI_TstFldCdClrdStat_789 1 "true" 0 "false" ;
VAL_ 1929 DTCI_TstFldPwrUpSt_789 1 "true" 0 "false" ;
VAL_ 1929 DTCI_TstNPsdCdClrdSt_789 1 "true" 0 "false" ;
VAL_ 1929 DTCI_TstNPsdPwrUpSt_789 1 "true" 0 "false" ;
VAL_ 1929 DTCIUnused1_789 1 "true" 0 "false" ;
VAL_ 1929 DTCIUnused2_789 1 "true" 0 "false" ;
VAL_ 1929 DTCIUnused3_789 1 "true" 0 "false" ;
VAL_ 1929 DTCIUnused4_789 1 "true" 0 "false" ;
VAL_ 1929 DTCIUnused5_789 1 "true" 0 "false" ;
VAL_ 1929 DTCIUnused6_789 1 "true" 0 "false" ;
VAL_ 1929 DTCIUnused7_789 1 "true" 0 "false" ;
VAL_ 1929 DTCI_WrnIndRqdSt_789 1 "true" 0 "false" ;
VAL_ 1928 DTCI_CodeSupported_788 1 "true" 0 "false" ;
VAL_ 1928 DTCI_CurrentStatus_788 1 "true" 0 "false" ;
VAL_ 1928 DTCI_DTCFaultType_788 3 "Type C" 2 "Type B" 1 "Type A" 0 "Not Supported" ;
VAL_ 1928 DTCI_DTCTriggered_788 1 "true" 0 "false" ;
VAL_ 1928 DTCI_HistStat_788 1 "true" 0 "false" ;
VAL_ 1928 DTCI_TstFldCdClrdStat_788 1 "true" 0 "false" ;
VAL_ 1928 DTCI_TstFldPwrUpSt_788 1 "true" 0 "false" ;
VAL_ 1928 DTCI_TstNPsdCdClrdSt_788 1 "true" 0 "false" ;
VAL_ 1928 DTCI_TstNPsdPwrUpSt_788 1 "true" 0 "false" ;
VAL_ 1928 DTCIUnused1_788 1 "true" 0 "false" ;
VAL_ 1928 DTCIUnused2_788 1 "true" 0 "false" ;
VAL_ 1928 DTCIUnused3_788 1 "true" 0 "false" ;
VAL_ 1928 DTCIUnused4_788 1 "true" 0 "false" ;
VAL_ 1928 DTCIUnused5_788 1 "true" 0 "false" ;
VAL_ 1928 DTCIUnused6_788 1 "true" 0 "false" ;
VAL_ 1928 DTCIUnused7_788 1 "true" 0 "false" ;
VAL_ 1928 DTCI_WrnIndRqdSt_788 1 "true" 0 "false" ;
VAL_ 1927 DTCI_CodeSupported_787 1 "true" 0 "false" ;
VAL_ 1927 DTCI_CurrentStatus_787 1 "true" 0 "false" ;
VAL_ 1927 DTCI_DTCFaultType_787 3 "Type C" 2 "Type B" 1 "Type A" 0 "Not Supported" ;
VAL_ 1927 DTCI_DTCTriggered_787 1 "true" 0 "false" ;
VAL_ 1927 DTCI_HistStat_787 1 "true" 0 "false" ;
VAL_ 1927 DTCI_TstFldCdClrdStat_787 1 "true" 0 "false" ;
VAL_ 1927 DTCI_TstFldPwrUpSt_787 1 "true" 0 "false" ;
VAL_ 1927 DTCI_TstNPsdCdClrdSt_787 1 "true" 0 "false" ;
VAL_ 1927 DTCI_TstNPsdPwrUpSt_787 1 "true" 0 "false" ;
VAL_ 1927 DTCIUnused1_787 1 "true" 0 "false" ;
VAL_ 1927 DTCIUnused2_787 1 "true" 0 "false" ;
VAL_ 1927 DTCIUnused3_787 1 "true" 0 "false" ;
VAL_ 1927 DTCIUnused4_787 1 "true" 0 "false" ;
VAL_ 1927 DTCIUnused5_787 1 "true" 0 "false" ;
VAL_ 1927 DTCIUnused6_787 1 "true" 0 "false" ;
VAL_ 1927 DTCIUnused7_787 1 "true" 0 "false" ;
VAL_ 1927 DTCI_WrnIndRqdSt_787 1 "true" 0 "false" ;
VAL_ 1926 DTCI_CodeSupported_786 1 "true" 0 "false" ;
VAL_ 1926 DTCI_CurrentStatus_786 1 "true" 0 "false" ;
VAL_ 1926 DTCI_DTCFaultType_786 3 "Type C" 2 "Type B" 1 "Type A" 0 "Not Supported" ;
VAL_ 1926 DTCI_DTCTriggered_786 1 "true" 0 "false" ;
VAL_ 1926 DTCI_HistStat_786 1 "true" 0 "false" ;
VAL_ 1926 DTCI_TstFldCdClrdStat_786 1 "true" 0 "false" ;
VAL_ 1926 DTCI_TstFldPwrUpSt_786 1 "true" 0 "false" ;
VAL_ 1926 DTCI_TstNPsdCdClrdSt_786 1 "true" 0 "false" ;
VAL_ 1926 DTCI_TstNPsdPwrUpSt_786 1 "true" 0 "false" ;
VAL_ 1926 DTCIUnused1_786 1 "true" 0 "false" ;
VAL_ 1926 DTCIUnused2_786 1 "true" 0 "false" ;
VAL_ 1926 DTCIUnused3_786 1 "true" 0 "false" ;
VAL_ 1926 DTCIUnused4_786 1 "true" 0 "false" ;
VAL_ 1926 DTCIUnused5_786 1 "true" 0 "false" ;
VAL_ 1926 DTCIUnused6_786 1 "true" 0 "false" ;
VAL_ 1926 DTCIUnused7_786 1 "true" 0 "false" ;
VAL_ 1926 DTCI_WrnIndRqdSt_786 1 "true" 0 "false" ;
VAL_ 1925 DTCI_CodeSupported_785 1 "true" 0 "false" ;
VAL_ 1925 DTCI_CurrentStatus_785 1 "true" 0 "false" ;
VAL_ 1925 DTCI_DTCFaultType_785 3 "Type C" 2 "Type B" 1 "Type A" 0 "Not Supported" ;
VAL_ 1925 DTCI_DTCTriggered_785 1 "true" 0 "false" ;
VAL_ 1925 DTCI_HistStat_785 1 "true" 0 "false" ;
VAL_ 1925 DTCI_TstFldCdClrdStat_785 1 "true" 0 "false" ;
VAL_ 1925 DTCI_TstFldPwrUpSt_785 1 "true" 0 "false" ;
VAL_ 1925 DTCI_TstNPsdCdClrdSt_785 1 "true" 0 "false" ;
VAL_ 1925 DTCI_TstNPsdPwrUpSt_785 1 "true" 0 "false" ;
VAL_ 1925 DTCIUnused1_785 1 "true" 0 "false" ;
VAL_ 1925 DTCIUnused2_785 1 "true" 0 "false" ;
VAL_ 1925 DTCIUnused3_785 1 "true" 0 "false" ;
VAL_ 1925 DTCIUnused4_785 1 "true" 0 "false" ;
VAL_ 1925 DTCIUnused5_785 1 "true" 0 "false" ;
VAL_ 1925 DTCIUnused6_785 1 "true" 0 "false" ;
VAL_ 1925 DTCIUnused7_785 1 "true" 0 "false" ;
VAL_ 1925 DTCI_WrnIndRqdSt_785 1 "true" 0 "false" ;
VAL_ 1924 DTCI_HistStat_784 1 "true" 0 "false" ;
VAL_ 1924 DTCI_TstFldCdClrdStat_784 1 "true" 0 "false" ;
VAL_ 1924 DTCI_TstFldPwrUpSt_784 1 "true" 0 "false" ;
VAL_ 1924 DTCI_TstNPsdCdClrdSt_784 1 "true" 0 "false" ;
VAL_ 1924 DTCI_TstNPsdPwrUpSt_784 1 "true" 0 "false" ;
VAL_ 1924 DTCIUnused1_784 1 "true" 0 "false" ;
VAL_ 1924 DTCIUnused2_784 1 "true" 0 "false" ;
VAL_ 1924 DTCIUnused3_784 1 "true" 0 "false" ;
VAL_ 1924 DTCIUnused4_784 1 "true" 0 "false" ;
VAL_ 1924 DTCIUnused5_784 1 "true" 0 "false" ;
VAL_ 1924 DTCIUnused6_784 1 "true" 0 "false" ;
VAL_ 1924 DTCIUnused7_784 1 "true" 0 "false" ;
VAL_ 1924 DTCI_WrnIndRqdSt_784 1 "true" 0 "false" ;
VAL_ 1924 DTCI_CodeSupported_784 1 "true" 0 "false" ;
VAL_ 1924 DTCI_CurrentStatus_784 1 "true" 0 "false" ;
VAL_ 1924 DTCI_DTCFaultType_784 3 "Type C" 2 "Type B" 1 "Type A" 0 "Not Supported" ;
VAL_ 1924 DTCI_DTCTriggered_784 1 "true" 0 "false" ;
VAL_ 1923 DTCI_WrnIndRqdSt_783 1 "true" 0 "false" ;
VAL_ 1923 DTCI_TstNPsdPwrUpSt_783 1 "true" 0 "false" ;
VAL_ 1923 DTCI_TstNPsdCdClrdSt_783 1 "true" 0 "false" ;
VAL_ 1923 DTCI_TstFldPwrUpSt_783 1 "true" 0 "false" ;
VAL_ 1923 DTCI_TstFldCdClrdStat_783 1 "true" 0 "false" ;
VAL_ 1923 DTCI_HistStat_783 1 "true" 0 "false" ;
VAL_ 1923 DTCI_DTCTriggered_783 1 "true" 0 "false" ;
VAL_ 1923 DTCI_DTCFaultType_783 3 "Type C" 2 "Type B" 1 "Type A" 0 "Not Supported" ;
VAL_ 1923 DTCI_CurrentStatus_783 1 "true" 0 "false" ;
VAL_ 1923 DTCI_CodeSupported_783 1 "true" 0 "false" ;
VAL_ 1923 DTCIUnused7_783 1 "true" 0 "false" ;
VAL_ 1923 DTCIUnused6_783 1 "true" 0 "false" ;
VAL_ 1923 DTCIUnused5_783 1 "true" 0 "false" ;
VAL_ 1923 DTCIUnused4_783 1 "true" 0 "false" ;
VAL_ 1923 DTCIUnused3_783 1 "true" 0 "false" ;
VAL_ 1923 DTCIUnused2_783 1 "true" 0 "false" ;
VAL_ 1923 DTCIUnused1_783 1 "true" 0 "false" ;
VAL_ 190 TrnsAuxPmpAct 1 "true" 0 "false" ;
VAL_ 190 PSBPI_PTSnBrkPdlPsV 1 "Invalid" 0 "Valid" ;
VAL_ 322 AFLGPSCstStReq 0 "No Action" 1 "Corner And Curve Lighting Only" 2 "Intelligent Light Distribution" 3 "GPS Assistance" 4 "Reserved1" 5 "Reserved2" 6 "Reserved3" 7 "Reserved4" ;
VAL_ 322 AFLCstStReq 0 "No Action" 1 "Corner And Curve Lighting Only" 2 "Intelligent Light Distribution" 3 "Reserved1" 4 "Reserved2" 5 "Reserved3" 6 "Reserved4" 7 "Reserved5" ;
VAL_ 322 LtRtHnTrCstStReq 0 "No Action" 1 "Left Hand Drive" 2 "Right Hand Drive" ;
VAL_ 322 AdpHgBmAsSnCsStRq 0 "No Action" 1 "Off" 2 "Normal Sensitivity" 3 "Reduced Sensitivity" 4 "Reserved1" 5 "Reserved2" 6 "Reserved3" 7 "Reserved4" ;
VAL_ 322 AdpHgBmAstCstStRq 0 "No Action" 1 "Off" 2 "On" 3 "Reserved1" 4 "Reserved2" 5 "Reserved3" 6 "Reserved4" 7 "Reserved5" ;
VAL_ 322 LtRtHnTrGPSCstStRq 0 "No Action" 1 "Left Hand Traffic" 2 "Right Hand Traffic" 3 "Automatic" 4 "Reserved1" 5 "Reserved2" 6 "Reserved3" 7 "Reserved4" ;
VAL_ 322 AutHgBmAsSnCsStRq 0 "No Action" 1 "Off" 2 "On Normal Sensitivity" 3 "On Reduced Sensitivity" 4 "Reserved1" 5 "Reserved2" 6 "Reserved3" 7 "Reserved4" ;
VAL_ 322 AutHgBmAstCstStRq 0 "No Action" 1 "Off" 2 "On" 3 "Reserved1" 4 "Reserved2" 5 "Reserved3" 6 "Reserved4" 7 "Reserved5" ;
VAL_ 534 SrvSuspSysIO 1 "true" 0 "false" ;
VAL_ 309 StBltTgtCSRq 0 "No Action" 1 "Low" 2 "Normal" 3 "Performance" 4 "Locked" ;
VAL_ 309 ColPrSysCustReq 0 "No Action" 1 "Off" 2 "Alert" 3 "Alert and Brake" ;
VAL_ 309 SecV 1 "Invalid" 0 "Valid" ;
VAL_ 309 CldrMth_154 12 "December" 11 "November" 10 "October" 9 "September" 8 "August" 7 "July" 6 "June" 5 "May" 4 "April" 3 "March" 2 "February" 1 "January" 0 "Unknown" ;
VAL_ 309 CldrMth 12 "December" 11 "November" 10 "October" 9 "September" 8 "August" 7 "July" 6 "June" 5 "May" 4 "April" 3 "March" 2 "February" 1 "January" 0 "Unknown" ;
VAL_ 309 AutoHiBmVDA 1 "VirtualDeviceAvailable" 0 "VirtualDeviceUnavailable" ;
VAL_ 309 CtLghtDet 1 "true" 0 "false" ;
VAL_ 309 RrClosVDA 1 "VirtualDeviceAvailable" 0 "VirtualDeviceUnavailable" ;
VAL_ 309 TCSysDisSwAtv 1 "true" 0 "false" ;
VAL_ 309 VehMovState 4 "Invalid" 3 "Reverse" 2 "Forward" 1 "Neutral" 0 "Parked" ;
VAL_ 309 TCSysDisSwAtvV 1 "Invalid" 0 "Valid" ;
VAL_ 309 HillDesCtrlMdSwActV 1 "Invalid" 0 "Valid" ;
VAL_ 309 WSWshSwAtv 1 "true" 0 "false" ;
VAL_ 309 HillDesCtrlMdSwAct 1 "true" 0 "false" ;
VAL_ 309 RrClosAjarSwAct 1 "true" 0 "false" ;
VAL_ 309 WSWprAct 1 "true" 0 "false" ;
SIG_GROUP_ 452 AutBrkAccActPsSt 1 : ABAAPS_AccPos ABAAPS_AccPosV;
SIG_GROUP_ 452 ACCAxlTrqCmdStat 1 : ACCATCS_LmtgStat ACCATCS_RqStat;
SIG_GROUP_ 452 ColPrSysAxlTrqCmdStat 1 : CPSATCS_ReqStatus CPSATCS_LmtngStatus;
SIG_GROUP_ 452 RrVrtBmpAxlTrqCmdStat 1 : RVBATCS_ReqStat RVBATCS_LmtngStat;
SIG_GROUP_ 1905 DTCInfo_771 1 : DTCI_DTCFaultType_771 DTCI_CodeSupported_771 DTCI_CurrentStatus_771 DTCI_TstNPsdCdClrdSt_771 DTCI_TstFldCdClrdStat_771 DTCI_HistStat_771 DTCI_TstNPsdPwrUpSt_771 DTCI_TstFldPwrUpSt_771 DTCI_WrnIndRqdSt_771 DTCI_DTCFailType_771 DTCI_DTCNumber_771 DTCI_DTCSource_771 DTCI_DTCTriggered_771 DTCIUnused7_771 DTCIUnused6_771 DTCIUnused5_771 DTCIUnused4_771 DTCIUnused3_771 DTCIUnused2_771 DTCIUnused1_771;
SIG_GROUP_ 1935 DTCInfo_78F 1 : DTCI_DTCSource_78F DTCI_DTCTriggered_78F DTCIUnused1_78F DTCIUnused2_78F DTCIUnused3_78F DTCIUnused4_78F DTCIUnused5_78F DTCIUnused6_78F DTCIUnused7_78F DTCI_CodeSupported_78F DTCI_CurrentStatus_78F DTCI_DTCFaultType_78F DTCI_TstFldCdClrdStat_78F DTCI_TstNPsdCdClrdSt_78F DTCI_HistStat_78F DTCI_TstNPsdPwrUpSt_78F DTCI_TstFldPwrUpSt_78F DTCI_WrnIndRqdSt_78F DTCI_DTCFailType_78F DTCI_DTCNumber_78F;
SIG_GROUP_ 1934 DTCInfo_78E 1 : DTCI_CodeSupported_78E DTCI_CurrentStatus_78E DTCI_DTCFailType_78E DTCI_DTCFaultType_78E DTCI_DTCNumber_78E DTCI_DTCSource_78E DTCI_DTCTriggered_78E DTCI_HistStat_78E DTCI_TstFldCdClrdStat_78E DTCI_TstFldPwrUpSt_78E DTCI_TstNPsdCdClrdSt_78E DTCI_TstNPsdPwrUpSt_78E DTCIUnused1_78E DTCIUnused2_78E DTCIUnused3_78E DTCIUnused4_78E DTCIUnused5_78E DTCIUnused6_78E DTCIUnused7_78E DTCI_WrnIndRqdSt_78E;
SIG_GROUP_ 1933 DTCInfo_78D 1 : DTCI_CodeSupported_78D DTCI_CurrentStatus_78D DTCI_DTCFailType_78D DTCI_DTCFaultType_78D DTCI_DTCNumber_78D DTCI_DTCSource_78D DTCI_DTCTriggered_78D DTCI_HistStat_78D DTCI_TstFldCdClrdStat_78D DTCI_TstFldPwrUpSt_78D DTCI_TstNPsdCdClrdSt_78D DTCI_TstNPsdPwrUpSt_78D DTCIUnused1_78D DTCIUnused2_78D DTCIUnused3_78D DTCIUnused4_78D DTCIUnused5_78D DTCIUnused6_78D DTCIUnused7_78D DTCI_WrnIndRqdSt_78D;
SIG_GROUP_ 1932 DTCInfo_78C 1 : DTCI_CodeSupported_78C DTCI_CurrentStatus_78C DTCI_DTCFailType_78C DTCI_DTCFaultType_78C DTCI_DTCNumber_78C DTCI_DTCSource_78C DTCI_DTCTriggered_78C DTCI_HistStat_78C DTCI_TstFldCdClrdStat_78C DTCI_TstFldPwrUpSt_78C DTCI_TstNPsdCdClrdSt_78C DTCI_TstNPsdPwrUpSt_78C DTCIUnused1_78C DTCIUnused2_78C DTCIUnused3_78C DTCIUnused4_78C DTCIUnused5_78C DTCIUnused6_78C DTCIUnused7_78C DTCI_WrnIndRqdSt_78C;
SIG_GROUP_ 1931 DTCInfo_78B 1 : DTCI_CodeSupported_78B DTCI_CurrentStatus_78B DTCI_DTCFailType_78B DTCI_DTCFaultType_78B DTCI_DTCNumber_78B DTCI_DTCSource_78B DTCI_DTCTriggered_78B DTCI_HistStat_78B DTCI_TstFldCdClrdStat_78B DTCI_TstFldPwrUpSt_78B DTCI_TstNPsdCdClrdSt_78B DTCI_TstNPsdPwrUpSt_78B DTCIUnused1_78B DTCIUnused2_78B DTCIUnused3_78B DTCIUnused4_78B DTCIUnused5_78B DTCIUnused6_78B DTCIUnused7_78B DTCI_WrnIndRqdSt_78B;
SIG_GROUP_ 1930 DTCInfo_78A 1 : DTCI_CodeSupported_78A DTCI_CurrentStatus_78A DTCI_DTCFailType_78A DTCI_DTCFaultType_78A DTCI_DTCNumber_78A DTCI_DTCSource_78A DTCI_DTCTriggered_78A DTCI_HistStat_78A DTCI_TstFldCdClrdStat_78A DTCI_TstFldPwrUpSt_78A DTCI_TstNPsdCdClrdSt_78A DTCI_TstNPsdPwrUpSt_78A DTCIUnused1_78A DTCIUnused2_78A DTCIUnused3_78A DTCIUnused4_78A DTCIUnused5_78A DTCIUnused6_78A DTCIUnused7_78A DTCI_WrnIndRqdSt_78A;
SIG_GROUP_ 1929 DTCInfo_789 1 : DTCI_CodeSupported_789 DTCI_CurrentStatus_789 DTCI_DTCFailType_789 DTCI_DTCFaultType_789 DTCI_DTCNumber_789 DTCI_DTCSource_789 DTCI_DTCTriggered_789 DTCI_HistStat_789 DTCI_TstFldCdClrdStat_789 DTCI_TstFldPwrUpSt_789 DTCI_TstNPsdCdClrdSt_789 DTCI_TstNPsdPwrUpSt_789 DTCIUnused1_789 DTCIUnused2_789 DTCIUnused3_789 DTCIUnused4_789 DTCIUnused5_789 DTCIUnused6_789 DTCIUnused7_789 DTCI_WrnIndRqdSt_789;
SIG_GROUP_ 1928 DTCInfo_788 1 : DTCI_CodeSupported_788 DTCI_CurrentStatus_788 DTCI_DTCFailType_788 DTCI_DTCFaultType_788 DTCI_DTCNumber_788 DTCI_DTCSource_788 DTCI_DTCTriggered_788 DTCI_HistStat_788 DTCI_TstFldCdClrdStat_788 DTCI_TstFldPwrUpSt_788 DTCI_TstNPsdCdClrdSt_788 DTCI_TstNPsdPwrUpSt_788 DTCIUnused1_788 DTCIUnused2_788 DTCIUnused3_788 DTCIUnused4_788 DTCIUnused5_788 DTCIUnused6_788 DTCIUnused7_788 DTCI_WrnIndRqdSt_788;
SIG_GROUP_ 1927 DTCInfo_787 1 : DTCI_CodeSupported_787 DTCI_CurrentStatus_787 DTCI_DTCFailType_787 DTCI_DTCFaultType_787 DTCI_DTCNumber_787 DTCI_DTCSource_787 DTCI_DTCTriggered_787 DTCI_HistStat_787 DTCI_TstFldCdClrdStat_787 DTCI_TstFldPwrUpSt_787 DTCI_TstNPsdCdClrdSt_787 DTCI_TstNPsdPwrUpSt_787 DTCIUnused1_787 DTCIUnused2_787 DTCIUnused3_787 DTCIUnused4_787 DTCIUnused5_787 DTCIUnused6_787 DTCIUnused7_787 DTCI_WrnIndRqdSt_787;
SIG_GROUP_ 1926 DTCInfo_786 1 : DTCI_CodeSupported_786 DTCI_CurrentStatus_786 DTCI_DTCFailType_786 DTCI_DTCFaultType_786 DTCI_DTCNumber_786 DTCI_DTCSource_786 DTCI_DTCTriggered_786 DTCI_HistStat_786 DTCI_TstFldCdClrdStat_786 DTCI_TstFldPwrUpSt_786 DTCI_TstNPsdCdClrdSt_786 DTCI_TstNPsdPwrUpSt_786 DTCIUnused1_786 DTCIUnused2_786 DTCIUnused3_786 DTCIUnused4_786 DTCIUnused5_786 DTCIUnused6_786 DTCIUnused7_786 DTCI_WrnIndRqdSt_786;
SIG_GROUP_ 1925 DTCInfo_785 1 : DTCI_CodeSupported_785 DTCI_CurrentStatus_785 DTCI_DTCFailType_785 DTCI_DTCFaultType_785 DTCI_DTCNumber_785 DTCI_DTCSource_785 DTCI_DTCTriggered_785 DTCI_HistStat_785 DTCI_TstFldCdClrdStat_785 DTCI_TstFldPwrUpSt_785 DTCI_TstNPsdCdClrdSt_785 DTCI_TstNPsdPwrUpSt_785 DTCIUnused1_785 DTCIUnused2_785 DTCIUnused3_785 DTCIUnused4_785 DTCIUnused5_785 DTCIUnused6_785 DTCIUnused7_785 DTCI_WrnIndRqdSt_785;
SIG_GROUP_ 1924 DTCInfo_784 1 : DTCI_HistStat_784 DTCI_TstFldCdClrdStat_784 DTCI_TstFldPwrUpSt_784 DTCI_TstNPsdCdClrdSt_784 DTCI_TstNPsdPwrUpSt_784 DTCIUnused1_784 DTCIUnused2_784 DTCIUnused3_784 DTCIUnused4_784 DTCIUnused5_784 DTCIUnused6_784 DTCIUnused7_784 DTCI_WrnIndRqdSt_784 DTCI_CodeSupported_784 DTCI_CurrentStatus_784 DTCI_DTCFailType_784 DTCI_DTCFaultType_784 DTCI_DTCNumber_784 DTCI_DTCSource_784 DTCI_DTCTriggered_784;
SIG_GROUP_ 1923 DTCInfo_783 1 : DTCI_WrnIndRqdSt_783 DTCI_TstNPsdPwrUpSt_783 DTCI_TstNPsdCdClrdSt_783 DTCI_TstFldPwrUpSt_783 DTCI_TstFldCdClrdStat_783 DTCI_HistStat_783 DTCI_DTCTriggered_783 DTCI_DTCSource_783 DTCI_DTCNumber_783 DTCI_DTCFaultType_783 DTCI_DTCFailType_783 DTCI_CurrentStatus_783 DTCI_CodeSupported_783 DTCIUnused7_783 DTCIUnused6_783 DTCIUnused5_783 DTCIUnused4_783 DTCIUnused3_783 DTCIUnused2_783 DTCIUnused1_783;
SIG_GROUP_ 190 PTSnsdBrkPdlInf 1 : PSBPI_PTSnBrkPdlPsV PSBPI_PTSnBrkPdlPs;
